VERSION ""

NS_ :

BS_:

BU_: HVESP01 HVESS

BO_ 2499743845 HVESP01_DiagnosticA_1: 8 HVESP01
 SG_ HVESP01_vBrickOverSev_1 : 2|2@1+ (1,0) [0|3] ""  HVESP01
 SG_ HVESP01_vBrickOverMod_1 : 0|2@1+ (1,0) [0|3] ""  HVESP01
 SG_ HVESP01_vBrickOverWar_1 : 14|2@1+ (1,0) [0|3] ""  HVESP01
 SG_ HVESP01_HVESP01Quiet_1 : 12|2@1+ (1,0) [0|3] ""  HVESP01
 SG_ HVESP01_vBrickUnderMod_1 : 10|2@1+ (1,0) [0|3] ""  HVESP01
 SG_ HVESP01_vBrickUnderWar_1 : 8|2@1+ (1,0) [0|3] ""  HVESP01
 SG_ HVESP01_TempModuleOverSev_1 : 22|2@1+ (1,0) [0|3] ""  HVESP01
 SG_ HVESP01_TempModuleOverMod_1 : 20|2@1+ (1,0) [0|3] ""  HVESP01
 SG_ HVESP01_TempModuleOverWar_1 : 18|2@1+ (1,0) [0|3] ""  HVESP01
 SG_ HVESP01_TempModuleUnderSev_1 : 16|2@1+ (1,0) [0|3] ""  HVESP01
 SG_ HVESP01_TempModuleUnderMod_1 : 30|2@1+ (1,0) [0|3] ""  HVESP01
 SG_ HVESP01_TempModuleUnderWar_1 : 28|2@1+ (1,0) [0|3] ""  HVESP01
 SG_ HVESP01_iOvercharge_1 : 26|2@1+ (1,0) [0|3] ""  HVESP01
 SG_ HVESP01_iOverdischarge_1 : 24|2@1+ (1,0) [0|3] ""  HVESP01
 SG_ HVESP01_iOverHardware_1 : 38|2@1+ (1,0) [0|3] ""  HVESP01
 SG_ HVESP01_PosContStuckOpen_1_1 : 36|2@1+ (1,0) [0|3] ""  HVESP01
 SG_ HVESP01_BATT_PosContWelded_1_1 : 34|2@1+ (1,0) [0|3] ""  HVESP01
 SG_ HVESP01_NegContStuckOpen_1_1 : 32|2@1+ (1,0) [0|3] ""  HVESP01
 SG_ HVESP01_NegContWelded_1_1 : 46|2@1+ (1,0) [0|3] ""  HVESP01
 SG_ HVESP01_PrechgTimeout_2_1 : 44|2@1+ (1,0) [0|3] ""  HVESP01
 SG_ HVESP01_PrechgContStuckOpen_2_1 : 42|2@1+ (1,0) [0|3] ""  HVESP01
 SG_ HVESP01_PrechgTimeout_1_1 : 40|2@1+ (1,0) [0|3] ""  HVESP01
 SG_ HVESP01_PrechgContStuckOpen_1_1 : 54|2@1+ (1,0) [0|3] ""  HVESP01
 SG_ HVESP01_ModuleImbalance_1 : 52|2@1+ (1,0) [0|3] ""  HVESP01
 SG_ HVESP01_ModuleMIA_1 : 50|2@1+ (1,0) [0|3] ""  HVESP01
 SG_ HVESP01_SensePackVoltError_1 : 48|2@1+ (1,0) [0|3] ""  HVESP01
 SG_ HVESP01_SenseLoadVoltError_1 : 62|2@1+ (1,0) [0|3] ""  HVESP01
 SG_ HVESP01_SenseShuntError_1 : 60|2@1+ (1,0) [0|3] ""  HVESP01
 SG_ HVESP01_SenseFcVoltErrorr_1 : 58|2@1+ (1,0) [0|3] ""  HVESP01
 SG_ HVESP01_Placeholder14_1 : 56|2@1+ (1,0) [0|3] ""  HVESP01

BO_ 2499743846 HVESP01_DiagnosticA_2: 8 HVESP01
 SG_ HVESP01_vBrickOverSev_2 : 2|2@1+ (1,0) [0|3] ""  HVESP01
 SG_ HVESP01_vBrickOverMod_2 : 0|2@1+ (1,0) [0|3] ""  HVESP01
 SG_ HVESP01_vBrickOverWar_2 : 14|2@1+ (1,0) [0|3] ""  HVESP01
 SG_ HVESP01_HVESP01Quiet_2 : 12|2@1+ (1,0) [0|3] ""  HVESP01
 SG_ HVESP01_vBrickUnderMod_2 : 10|2@1+ (1,0) [0|3] ""  HVESP01
 SG_ HVESP01_vBrickUnderWar_2 : 8|2@1+ (1,0) [0|3] ""  HVESP01
 SG_ HVESP01_TempModuleOverSev_2 : 22|2@1+ (1,0) [0|3] ""  HVESP01
 SG_ HVESP01_TempModuleOverMod_2 : 20|2@1+ (1,0) [0|3] ""  HVESP01
 SG_ HVESP01_TempModuleOverWar_2 : 18|2@1+ (1,0) [0|3] ""  HVESP01
 SG_ HVESP01_TempModuleUnderSev_2 : 16|2@1+ (1,0) [0|3] ""  HVESP01
 SG_ HVESP01_TempModuleUnderMod_2 : 30|2@1+ (1,0) [0|3] ""  HVESP01
 SG_ HVESP01_TempModuleUnderWar_2 : 28|2@1+ (1,0) [0|3] ""  HVESP01
 SG_ HVESP01_iOvercharge_2 : 26|2@1+ (1,0) [0|3] ""  HVESP01
 SG_ HVESP01_iOverdischarge_2 : 24|2@1+ (1,0) [0|3] ""  HVESP01
 SG_ HVESP01_iOverHardware_2 : 38|2@1+ (1,0) [0|3] ""  HVESP01
 SG_ HVESP01_PosContStuckOpen_1_2 : 36|2@1+ (1,0) [0|3] ""  HVESP01
 SG_ HVESP01_BATT_PosContWelded_1_2 : 34|2@1+ (1,0) [0|3] ""  HVESP01
 SG_ HVESP01_NegContStuckOpen_1_2 : 32|2@1+ (1,0) [0|3] ""  HVESP01
 SG_ HVESP01_NegContWelded_1_2 : 46|2@1+ (1,0) [0|3] ""  HVESP01
 SG_ HVESP01_PrechgTimeout_2_2 : 44|2@1+ (1,0) [0|3] ""  HVESP01
 SG_ HVESP01_PrechgContStuckOpen_2_2 : 42|2@1+ (1,0) [0|3] ""  HVESP01
 SG_ HVESP01_PrechgTimeout_1_2 : 40|2@1+ (1,0) [0|3] ""  HVESP01
 SG_ HVESP01_PrechgContStuckOpen_1_2 : 54|2@1+ (1,0) [0|3] ""  HVESP01
 SG_ HVESP01_ModuleImbalance_2 : 52|2@1+ (1,0) [0|3] ""  HVESP01
 SG_ HVESP01_ModuleMIA_2 : 50|2@1+ (1,0) [0|3] ""  HVESP01
 SG_ HVESP01_SensePackVoltError_2 : 48|2@1+ (1,0) [0|3] ""  HVESP01
 SG_ HVESP01_SenseLoadVoltError_2 : 62|2@1+ (1,0) [0|3] ""  HVESP01
 SG_ HVESP01_SenseShuntError_2 : 60|2@1+ (1,0) [0|3] ""  HVESP01
 SG_ HVESP01_SenseFcVoltErrorr_2 : 58|2@1+ (1,0) [0|3] ""  HVESP01
 SG_ HVESP01_Placeholder14_2 : 56|2@1+ (1,0) [0|3] ""  HVESP01

BO_ 2499743847 HVESP01_DiagnosticA_3: 8 HVESP01
 SG_ HVESP01_vBrickOverSev_3 : 2|2@1+ (1,0) [0|3] ""  HVESP01
 SG_ HVESP01_vBrickOverMod_3 : 0|2@1+ (1,0) [0|3] ""  HVESP01
 SG_ HVESP01_vBrickOverWar_3 : 14|2@1+ (1,0) [0|3] ""  HVESP01
 SG_ HVESP01_HVESP01Quiet_3 : 12|2@1+ (1,0) [0|3] ""  HVESP01
 SG_ HVESP01_vBrickUnderMod_3 : 10|2@1+ (1,0) [0|3] ""  HVESP01
 SG_ HVESP01_vBrickUnderWar_3 : 8|2@1+ (1,0) [0|3] ""  HVESP01
 SG_ HVESP01_TempModuleOverSev_3 : 22|2@1+ (1,0) [0|3] ""  HVESP01
 SG_ HVESP01_TempModuleOverMod_3 : 20|2@1+ (1,0) [0|3] ""  HVESP01
 SG_ HVESP01_TempModuleOverWar_3 : 18|2@1+ (1,0) [0|3] ""  HVESP01
 SG_ HVESP01_TempModuleUnderSev_3 : 16|2@1+ (1,0) [0|3] ""  HVESP01
 SG_ HVESP01_TempModuleUnderMod_3 : 30|2@1+ (1,0) [0|3] ""  HVESP01
 SG_ HVESP01_TempModuleUnderWar_3 : 28|2@1+ (1,0) [0|3] ""  HVESP01
 SG_ HVESP01_iOvercharge_3 : 26|2@1+ (1,0) [0|3] ""  HVESP01
 SG_ HVESP01_iOverdischarge_3 : 24|2@1+ (1,0) [0|3] ""  HVESP01
 SG_ HVESP01_iOverHardware_3 : 38|2@1+ (1,0) [0|3] ""  HVESP01
 SG_ HVESP01_PosContStuckOpen_1_3 : 36|2@1+ (1,0) [0|3] ""  HVESP01
 SG_ HVESP01_BATT_PosContWelded_1_3 : 34|2@1+ (1,0) [0|3] ""  HVESP01
 SG_ HVESP01_NegContStuckOpen_1_3 : 32|2@1+ (1,0) [0|3] ""  HVESP01
 SG_ HVESP01_NegContWelded_1_3 : 46|2@1+ (1,0) [0|3] ""  HVESP01
 SG_ HVESP01_PrechgTimeout_2_3 : 44|2@1+ (1,0) [0|3] ""  HVESP01
 SG_ HVESP01_PrechgContStuckOpen_2_3 : 42|2@1+ (1,0) [0|3] ""  HVESP01
 SG_ HVESP01_PrechgTimeout_1_3 : 40|2@1+ (1,0) [0|3] ""  HVESP01
 SG_ HVESP01_PrechgContStuckOpen_1_3 : 54|2@1+ (1,0) [0|3] ""  HVESP01
 SG_ HVESP01_ModuleImbalance_3 : 52|2@1+ (1,0) [0|3] ""  HVESP01
 SG_ HVESP01_ModuleMIA_3 : 50|2@1+ (1,0) [0|3] ""  HVESP01
 SG_ HVESP01_SensePackVoltError_3 : 48|2@1+ (1,0) [0|3] ""  HVESP01
 SG_ HVESP01_SenseLoadVoltError_3 : 62|2@1+ (1,0) [0|3] ""  HVESP01
 SG_ HVESP01_SenseShuntError_3 : 60|2@1+ (1,0) [0|3] ""  HVESP01
 SG_ HVESP01_SenseFcVoltErrorr_3 : 58|2@1+ (1,0) [0|3] ""  HVESP01
 SG_ HVESP01_Placeholder14_3 : 56|2@1+ (1,0) [0|3] ""  HVESP01

BO_ 2499743848 HVESP01_DiagnosticA_4: 8 HVESP01
 SG_ HVESP01_vBrickOverSev_4 : 2|2@1+ (1,0) [0|3] ""  HVESP01
 SG_ HVESP01_vBrickOverMod_4 : 0|2@1+ (1,0) [0|3] ""  HVESP01
 SG_ HVESP01_vBrickOverWar_4 : 14|2@1+ (1,0) [0|3] ""  HVESP01
 SG_ HVESP01_HVESP01Quiet_4 : 12|2@1+ (1,0) [0|3] ""  HVESP01
 SG_ HVESP01_vBrickUnderMod_4 : 10|2@1+ (1,0) [0|3] ""  HVESP01
 SG_ HVESP01_vBrickUnderWar_4 : 8|2@1+ (1,0) [0|3] ""  HVESP01
 SG_ HVESP01_TempModuleOverSev_4 : 22|2@1+ (1,0) [0|3] ""  HVESP01
 SG_ HVESP01_TempModuleOverMod_4 : 20|2@1+ (1,0) [0|3] ""  HVESP01
 SG_ HVESP01_TempModuleOverWar_4 : 18|2@1+ (1,0) [0|3] ""  HVESP01
 SG_ HVESP01_TempModuleUnderSev_4 : 16|2@1+ (1,0) [0|3] ""  HVESP01
 SG_ HVESP01_TempModuleUnderMod_4 : 30|2@1+ (1,0) [0|3] ""  HVESP01
 SG_ HVESP01_TempModuleUnderWar_4 : 28|2@1+ (1,0) [0|3] ""  HVESP01
 SG_ HVESP01_iOvercharge_4 : 26|2@1+ (1,0) [0|3] ""  HVESP01
 SG_ HVESP01_iOverdischarge_4 : 24|2@1+ (1,0) [0|3] ""  HVESP01
 SG_ HVESP01_iOverHardware_4 : 38|2@1+ (1,0) [0|3] ""  HVESP01
 SG_ HVESP01_PosContStuckOpen_1_4 : 36|2@1+ (1,0) [0|3] ""  HVESP01
 SG_ HVESP01_BATT_PosContWelded_1_4 : 34|2@1+ (1,0) [0|3] ""  HVESP01
 SG_ HVESP01_NegContStuckOpen_1_4 : 32|2@1+ (1,0) [0|3] ""  HVESP01
 SG_ HVESP01_NegContWelded_1_4 : 46|2@1+ (1,0) [0|3] ""  HVESP01
 SG_ HVESP01_PrechgTimeout_2_4 : 44|2@1+ (1,0) [0|3] ""  HVESP01
 SG_ HVESP01_PrechgContStuckOpen_2_4 : 42|2@1+ (1,0) [0|3] ""  HVESP01
 SG_ HVESP01_PrechgTimeout_1_4 : 40|2@1+ (1,0) [0|3] ""  HVESP01
 SG_ HVESP01_PrechgContStuckOpen_1_4 : 54|2@1+ (1,0) [0|3] ""  HVESP01
 SG_ HVESP01_ModuleImbalance_4 : 52|2@1+ (1,0) [0|3] ""  HVESP01
 SG_ HVESP01_ModuleMIA_4 : 50|2@1+ (1,0) [0|3] ""  HVESP01
 SG_ HVESP01_SensePackVoltError_4 : 48|2@1+ (1,0) [0|3] ""  HVESP01
 SG_ HVESP01_SenseLoadVoltError_4 : 62|2@1+ (1,0) [0|3] ""  HVESP01
 SG_ HVESP01_SenseShuntError_4 : 60|2@1+ (1,0) [0|3] ""  HVESP01
 SG_ HVESP01_SenseFcVoltErrorr_4 : 58|2@1+ (1,0) [0|3] ""  HVESP01
 SG_ HVESP01_Placeholder14_4 : 56|2@1+ (1,0) [0|3] ""  HVESP01

BO_ 2499743849 HVESP01_DiagnosticA_5: 8 HVESP01
 SG_ HVESP01_vBrickOverSev_5 : 2|2@1+ (1,0) [0|3] ""  HVESP01
 SG_ HVESP01_vBrickOverMod_5 : 0|2@1+ (1,0) [0|3] ""  HVESP01
 SG_ HVESP01_vBrickOverWar_5 : 14|2@1+ (1,0) [0|3] ""  HVESP01
 SG_ HVESP01_HVESP01Quiet_5 : 12|2@1+ (1,0) [0|3] ""  HVESP01
 SG_ HVESP01_vBrickUnderMod_5 : 10|2@1+ (1,0) [0|3] ""  HVESP01
 SG_ HVESP01_vBrickUnderWar_5 : 8|2@1+ (1,0) [0|3] ""  HVESP01
 SG_ HVESP01_TempModuleOverSev_5 : 22|2@1+ (1,0) [0|3] ""  HVESP01
 SG_ HVESP01_TempModuleOverMod_5 : 20|2@1+ (1,0) [0|3] ""  HVESP01
 SG_ HVESP01_TempModuleOverWar_5 : 18|2@1+ (1,0) [0|3] ""  HVESP01
 SG_ HVESP01_TempModuleUnderSev_5 : 16|2@1+ (1,0) [0|3] ""  HVESP01
 SG_ HVESP01_TempModuleUnderMod_5 : 30|2@1+ (1,0) [0|3] ""  HVESP01
 SG_ HVESP01_TempModuleUnderWar_5 : 28|2@1+ (1,0) [0|3] ""  HVESP01
 SG_ HVESP01_iOvercharge_5 : 26|2@1+ (1,0) [0|3] ""  HVESP01
 SG_ HVESP01_iOverdischarge_5 : 24|2@1+ (1,0) [0|3] ""  HVESP01
 SG_ HVESP01_iOverHardware_5 : 38|2@1+ (1,0) [0|3] ""  HVESP01
 SG_ HVESP01_PosContStuckOpen_1_5 : 36|2@1+ (1,0) [0|3] ""  HVESP01
 SG_ HVESP01_BATT_PosContWelded_1_5 : 34|2@1+ (1,0) [0|3] ""  HVESP01
 SG_ HVESP01_NegContStuckOpen_1_5 : 32|2@1+ (1,0) [0|3] ""  HVESP01
 SG_ HVESP01_NegContWelded_1_5 : 46|2@1+ (1,0) [0|3] ""  HVESP01
 SG_ HVESP01_PrechgTimeout_2_5 : 44|2@1+ (1,0) [0|3] ""  HVESP01
 SG_ HVESP01_PrechgContStuckOpen_2_5 : 42|2@1+ (1,0) [0|3] ""  HVESP01
 SG_ HVESP01_PrechgTimeout_1_5 : 40|2@1+ (1,0) [0|3] ""  HVESP01
 SG_ HVESP01_PrechgContStuckOpen_1_5 : 54|2@1+ (1,0) [0|3] ""  HVESP01
 SG_ HVESP01_ModuleImbalance_5 : 52|2@1+ (1,0) [0|3] ""  HVESP01
 SG_ HVESP01_ModuleMIA_5 : 50|2@1+ (1,0) [0|3] ""  HVESP01
 SG_ HVESP01_SensePackVoltError_5 : 48|2@1+ (1,0) [0|3] ""  HVESP01
 SG_ HVESP01_SenseLoadVoltError_5 : 62|2@1+ (1,0) [0|3] ""  HVESP01
 SG_ HVESP01_SenseShuntError_5 : 60|2@1+ (1,0) [0|3] ""  HVESP01
 SG_ HVESP01_SenseFcVoltErrorr_5 : 58|2@1+ (1,0) [0|3] ""  HVESP01
 SG_ HVESP01_Placeholder14_5 : 56|2@1+ (1,0) [0|3] ""  HVESP01

BO_ 2499743850 HVESP01_DiagnosticA_6: 8 HVESP01
 SG_ HVESP01_vBrickOverSev_6 : 2|2@1+ (1,0) [0|3] ""  HVESP01
 SG_ HVESP01_vBrickOverMod_6 : 0|2@1+ (1,0) [0|3] ""  HVESP01
 SG_ HVESP01_vBrickOverWar_6 : 14|2@1+ (1,0) [0|3] ""  HVESP01
 SG_ HVESP01_HVESP01Quiet_6 : 12|2@1+ (1,0) [0|3] ""  HVESP01
 SG_ HVESP01_vBrickUnderMod_6 : 10|2@1+ (1,0) [0|3] ""  HVESP01
 SG_ HVESP01_vBrickUnderWar_6 : 8|2@1+ (1,0) [0|3] ""  HVESP01
 SG_ HVESP01_TempModuleOverSev_6 : 22|2@1+ (1,0) [0|3] ""  HVESP01
 SG_ HVESP01_TempModuleOverMod_6 : 20|2@1+ (1,0) [0|3] ""  HVESP01
 SG_ HVESP01_TempModuleOverWar_6 : 18|2@1+ (1,0) [0|3] ""  HVESP01
 SG_ HVESP01_TempModuleUnderSev_6 : 16|2@1+ (1,0) [0|3] ""  HVESP01
 SG_ HVESP01_TempModuleUnderMod_6 : 30|2@1+ (1,0) [0|3] ""  HVESP01
 SG_ HVESP01_TempModuleUnderWar_6 : 28|2@1+ (1,0) [0|3] ""  HVESP01
 SG_ HVESP01_iOvercharge_6 : 26|2@1+ (1,0) [0|3] ""  HVESP01
 SG_ HVESP01_iOverdischarge_6 : 24|2@1+ (1,0) [0|3] ""  HVESP01
 SG_ HVESP01_iOverHardware_6 : 38|2@1+ (1,0) [0|3] ""  HVESP01
 SG_ HVESP01_PosContStuckOpen_1_6 : 36|2@1+ (1,0) [0|3] ""  HVESP01
 SG_ HVESP01_BATT_PosContWelded_1_6 : 34|2@1+ (1,0) [0|3] ""  HVESP01
 SG_ HVESP01_NegContStuckOpen_1_6 : 32|2@1+ (1,0) [0|3] ""  HVESP01
 SG_ HVESP01_NegContWelded_1_6 : 46|2@1+ (1,0) [0|3] ""  HVESP01
 SG_ HVESP01_PrechgTimeout_2_6 : 44|2@1+ (1,0) [0|3] ""  HVESP01
 SG_ HVESP01_PrechgContStuckOpen_2_6 : 42|2@1+ (1,0) [0|3] ""  HVESP01
 SG_ HVESP01_PrechgTimeout_1_6 : 40|2@1+ (1,0) [0|3] ""  HVESP01
 SG_ HVESP01_PrechgContStuckOpen_1_6 : 54|2@1+ (1,0) [0|3] ""  HVESP01
 SG_ HVESP01_ModuleImbalance_6 : 52|2@1+ (1,0) [0|3] ""  HVESP01
 SG_ HVESP01_ModuleMIA_6 : 50|2@1+ (1,0) [0|3] ""  HVESP01
 SG_ HVESP01_SensePackVoltError_6 : 48|2@1+ (1,0) [0|3] ""  HVESP01
 SG_ HVESP01_SenseLoadVoltError_6 : 62|2@1+ (1,0) [0|3] ""  HVESP01
 SG_ HVESP01_SenseShuntError_6 : 60|2@1+ (1,0) [0|3] ""  HVESP01
 SG_ HVESP01_SenseFcVoltErrorr_6 : 58|2@1+ (1,0) [0|3] ""  HVESP01
 SG_ HVESP01_Placeholder14_6 : 56|2@1+ (1,0) [0|3] ""  HVESP01

BO_ 2499743851 HVESP01_DiagnosticA_7: 8 HVESP01
 SG_ HVESP01_vBrickOverSev_7 : 2|2@1+ (1,0) [0|3] ""  HVESP01
 SG_ HVESP01_vBrickOverMod_7 : 0|2@1+ (1,0) [0|3] ""  HVESP01
 SG_ HVESP01_vBrickOverWar_7 : 14|2@1+ (1,0) [0|3] ""  HVESP01
 SG_ HVESP01_HVESP01Quiet_7 : 12|2@1+ (1,0) [0|3] ""  HVESP01
 SG_ HVESP01_vBrickUnderMod_7 : 10|2@1+ (1,0) [0|3] ""  HVESP01
 SG_ HVESP01_vBrickUnderWar_7 : 8|2@1+ (1,0) [0|3] ""  HVESP01
 SG_ HVESP01_TempModuleOverSev_7 : 22|2@1+ (1,0) [0|3] ""  HVESP01
 SG_ HVESP01_TempModuleOverMod_7 : 20|2@1+ (1,0) [0|3] ""  HVESP01
 SG_ HVESP01_TempModuleOverWar_7 : 18|2@1+ (1,0) [0|3] ""  HVESP01
 SG_ HVESP01_TempModuleUnderSev_7 : 16|2@1+ (1,0) [0|3] ""  HVESP01
 SG_ HVESP01_TempModuleUnderMod_7 : 30|2@1+ (1,0) [0|3] ""  HVESP01
 SG_ HVESP01_TempModuleUnderWar_7 : 28|2@1+ (1,0) [0|3] ""  HVESP01
 SG_ HVESP01_iOvercharge_7 : 26|2@1+ (1,0) [0|3] ""  HVESP01
 SG_ HVESP01_iOverdischarge_7 : 24|2@1+ (1,0) [0|3] ""  HVESP01
 SG_ HVESP01_iOverHardware_7 : 38|2@1+ (1,0) [0|3] ""  HVESP01
 SG_ HVESP01_PosContStuckOpen_1_7 : 36|2@1+ (1,0) [0|3] ""  HVESP01
 SG_ HVESP01_BATT_PosContWelded_1_7 : 34|2@1+ (1,0) [0|3] ""  HVESP01
 SG_ HVESP01_NegContStuckOpen_1_7 : 32|2@1+ (1,0) [0|3] ""  HVESP01
 SG_ HVESP01_NegContWelded_1_7 : 46|2@1+ (1,0) [0|3] ""  HVESP01
 SG_ HVESP01_PrechgTimeout_2_7 : 44|2@1+ (1,0) [0|3] ""  HVESP01
 SG_ HVESP01_PrechgContStuckOpen_2_7 : 42|2@1+ (1,0) [0|3] ""  HVESP01
 SG_ HVESP01_PrechgTimeout_1_7 : 40|2@1+ (1,0) [0|3] ""  HVESP01
 SG_ HVESP01_PrechgContStuckOpen_1_7 : 54|2@1+ (1,0) [0|3] ""  HVESP01
 SG_ HVESP01_ModuleImbalance_7 : 52|2@1+ (1,0) [0|3] ""  HVESP01
 SG_ HVESP01_ModuleMIA_7 : 50|2@1+ (1,0) [0|3] ""  HVESP01
 SG_ HVESP01_SensePackVoltError_7 : 48|2@1+ (1,0) [0|3] ""  HVESP01
 SG_ HVESP01_SenseLoadVoltError_7 : 62|2@1+ (1,0) [0|3] ""  HVESP01
 SG_ HVESP01_SenseShuntError_7 : 60|2@1+ (1,0) [0|3] ""  HVESP01
 SG_ HVESP01_SenseFcVoltErrorr_7 : 58|2@1+ (1,0) [0|3] ""  HVESP01
 SG_ HVESP01_Placeholder14_7 : 56|2@1+ (1,0) [0|3] ""  HVESP01

BO_ 2499743852 HVESP01_DiagnosticA_8: 8 HVESP01
 SG_ HVESP01_vBrickOverSev_8 : 2|2@1+ (1,0) [0|3] ""  HVESP01
 SG_ HVESP01_vBrickOverMod_8 : 0|2@1+ (1,0) [0|3] ""  HVESP01
 SG_ HVESP01_vBrickOverWar_8 : 14|2@1+ (1,0) [0|3] ""  HVESP01
 SG_ HVESP01_HVESP01Quiet_8 : 12|2@1+ (1,0) [0|3] ""  HVESP01
 SG_ HVESP01_vBrickUnderMod_8 : 10|2@1+ (1,0) [0|3] ""  HVESP01
 SG_ HVESP01_vBrickUnderWar_8 : 8|2@1+ (1,0) [0|3] ""  HVESP01
 SG_ HVESP01_TempModuleOverSev_8 : 22|2@1+ (1,0) [0|3] ""  HVESP01
 SG_ HVESP01_TempModuleOverMod_8 : 20|2@1+ (1,0) [0|3] ""  HVESP01
 SG_ HVESP01_TempModuleOverWar_8 : 18|2@1+ (1,0) [0|3] ""  HVESP01
 SG_ HVESP01_TempModuleUnderSev_8 : 16|2@1+ (1,0) [0|3] ""  HVESP01
 SG_ HVESP01_TempModuleUnderMod_8 : 30|2@1+ (1,0) [0|3] ""  HVESP01
 SG_ HVESP01_TempModuleUnderWar_8 : 28|2@1+ (1,0) [0|3] ""  HVESP01
 SG_ HVESP01_iOvercharge_8 : 26|2@1+ (1,0) [0|3] ""  HVESP01
 SG_ HVESP01_iOverdischarge_8 : 24|2@1+ (1,0) [0|3] ""  HVESP01
 SG_ HVESP01_iOverHardware_8 : 38|2@1+ (1,0) [0|3] ""  HVESP01
 SG_ HVESP01_PosContStuckOpen_1_8 : 36|2@1+ (1,0) [0|3] ""  HVESP01
 SG_ HVESP01_BATT_PosContWelded_1_8 : 34|2@1+ (1,0) [0|3] ""  HVESP01
 SG_ HVESP01_NegContStuckOpen_1_8 : 32|2@1+ (1,0) [0|3] ""  HVESP01
 SG_ HVESP01_NegContWelded_1_8 : 46|2@1+ (1,0) [0|3] ""  HVESP01
 SG_ HVESP01_PrechgTimeout_2_8 : 44|2@1+ (1,0) [0|3] ""  HVESP01
 SG_ HVESP01_PrechgContStuckOpen_2_8 : 42|2@1+ (1,0) [0|3] ""  HVESP01
 SG_ HVESP01_PrechgTimeout_1_8 : 40|2@1+ (1,0) [0|3] ""  HVESP01
 SG_ HVESP01_PrechgContStuckOpen_1_8 : 54|2@1+ (1,0) [0|3] ""  HVESP01
 SG_ HVESP01_ModuleImbalance_8 : 52|2@1+ (1,0) [0|3] ""  HVESP01
 SG_ HVESP01_ModuleMIA_8 : 50|2@1+ (1,0) [0|3] ""  HVESP01
 SG_ HVESP01_SensePackVoltError_8 : 48|2@1+ (1,0) [0|3] ""  HVESP01
 SG_ HVESP01_SenseLoadVoltError_8 : 62|2@1+ (1,0) [0|3] ""  HVESP01
 SG_ HVESP01_SenseShuntError_8 : 60|2@1+ (1,0) [0|3] ""  HVESP01
 SG_ HVESP01_SenseFcVoltErrorr_8 : 58|2@1+ (1,0) [0|3] ""  HVESP01
 SG_ HVESP01_Placeholder14_8 : 56|2@1+ (1,0) [0|3] ""  HVESP01

BO_ 2499744101 HVESP01_DiagnosticB_1: 8 HVESP01
 SG_ HVESP01_SenseBrickImpHigh_1 : 2|2@1+ (1,0) [0|3] ""  HVESP01
 SG_ HVESP01_AFEfault_1 : 0|2@1+ (1,0) [0|3] ""  HVESP01
 SG_ HVESP01_AFEerror_1 : 14|2@1+ (1,0) [0|3] ""  HVESP01
 SG_ HVESP01_HVESP01MIA_1 : 12|2@1+ (1,0) [0|3] ""  HVESP01
 SG_ HVESP01_TempAmbientOverSev_1 : 10|2@1+ (1,0) [0|3] ""  HVESP01
 SG_ HVESP01_TempAmbientOverMod_1 : 8|2@1+ (1,0) [0|3] ""  HVESP01
 SG_ HVESP01_TempAmbientOverWar_1 : 22|2@1+ (1,0) [0|3] ""  HVESP01
 SG_ HVESP01_AbnormReset_1 : 20|2@1+ (1,0) [0|3] ""  HVESP01
 SG_ HVESP01_SenseAuxVoltError_1 : 18|2@1+ (1,0) [0|3] ""  HVESP01
 SG_ HVESP01_CalibrationInvalid_1 : 16|2@1+ (1,0) [0|3] ""  HVESP01
 SG_ HVESP01_TaskLockup_1 : 30|2@1+ (1,0) [0|3] ""  HVESP01
 SG_ HVESP01_RAMover_1 : 28|2@1+ (1,0) [0|3] ""  HVESP01
 SG_ HVESP01_BrickOverdischarge_1 : 26|2@1+ (1,0) [0|3] ""  HVESP01
 SG_ HVESP01_BrickOvercharge_1 : 24|2@1+ (1,0) [0|3] ""  HVESP01
 SG_ HVESP01_vBrickImbalancePer_1 : 38|2@1+ (1,0) [0|3] ""  HVESP01
 SG_ HVESP01_TempBrickImbalance_1 : 36|2@1+ (1,0) [0|3] ""  HVESP01
 SG_ HVESP01_CapPackLow_1 : 34|2@1+ (1,0) [0|3] ""  HVESP01
 SG_ HVESP01_rBrickHigh_1 : 32|2@1+ (1,0) [0|3] ""  HVESP01
 SG_ HVESP01_PowerpackInsuffErr_1 : 46|2@1+ (1,0) [0|3] ""  HVESP01
 SG_ HVESP01_BrickSoftShort_1 : 44|2@1+ (1,0) [0|3] ""  HVESP01
 SG_ HVESP01_chargeUndercurrent_1 : 42|2@1+ (1,0) [0|3] ""  HVESP01
 SG_ HVESP01_HVILcurrentSourceError_1 : 40|2@1+ (1,0) [0|3] ""  HVESP01
 SG_ HVESP01_SRS_1 : 54|2@1+ (1,0) [0|3] ""  HVESP01
 SG_ HVESP01_IsolationExtWar_1 : 52|2@1+ (1,0) [0|3] ""  HVESP01
 SG_ HVESP01_IsolationIntWar_1 : 50|2@1+ (1,0) [0|3] ""  HVESP01
 SG_ HVESP01_PyroFuseBlown_1 : 48|2@1+ (1,0) [0|3] ""  HVESP01
 SG_ HVESP01_vBrickUnderSev_1 : 62|2@1+ (1,0) [0|3] ""  HVESP01
 SG_ HVESP01_chargePrechargeTimeout_1 : 60|2@1+ (1,0) [0|3] ""  HVESP01
 SG_ HVESP01_ModuleThermFaultModerate_1 : 58|2@1+ (1,0) [0|3] ""  HVESP01
 SG_ HVESP01_ModuleThermFaultWarning_1 : 56|2@1+ (1,0) [0|3] ""  HVESP01

BO_ 2499744102 HVESP01_DiagnosticB_2: 8 HVESP01
 SG_ HVESP01_SenseBrickImpHigh_2 : 2|2@1+ (1,0) [0|3] ""  HVESP01
 SG_ HVESP01_AFEfault_2 : 0|2@1+ (1,0) [0|3] ""  HVESP01
 SG_ HVESP01_AFEerror_2 : 14|2@1+ (1,0) [0|3] ""  HVESP01
 SG_ HVESP01_HVESP01MIA_2 : 12|2@1+ (1,0) [0|3] ""  HVESP01
 SG_ HVESP01_TempAmbientOverSev_2 : 10|2@1+ (1,0) [0|3] ""  HVESP01
 SG_ HVESP01_TempAmbientOverMod_2 : 8|2@1+ (1,0) [0|3] ""  HVESP01
 SG_ HVESP01_TempAmbientOverWar_2 : 22|2@1+ (1,0) [0|3] ""  HVESP01
 SG_ HVESP01_AbnormReset_2 : 20|2@1+ (1,0) [0|3] ""  HVESP01
 SG_ HVESP01_SenseAuxVoltError_2 : 18|2@1+ (1,0) [0|3] ""  HVESP01
 SG_ HVESP01_CalibrationInvalid_2 : 16|2@1+ (1,0) [0|3] ""  HVESP01
 SG_ HVESP01_TaskLockup_2 : 30|2@1+ (1,0) [0|3] ""  HVESP01
 SG_ HVESP01_RAMover_2 : 28|2@1+ (1,0) [0|3] ""  HVESP01
 SG_ HVESP01_BrickOverdischarge_2 : 26|2@1+ (1,0) [0|3] ""  HVESP01
 SG_ HVESP01_BrickOvercharge_2 : 24|2@1+ (1,0) [0|3] ""  HVESP01
 SG_ HVESP01_vBrickImbalancePer_2 : 38|2@1+ (1,0) [0|3] ""  HVESP01
 SG_ HVESP01_TempBrickImbalance_2 : 36|2@1+ (1,0) [0|3] ""  HVESP01
 SG_ HVESP01_CapPackLow_2 : 34|2@1+ (1,0) [0|3] ""  HVESP01
 SG_ HVESP01_rBrickHigh_2 : 32|2@1+ (1,0) [0|3] ""  HVESP01
 SG_ HVESP01_PowerpackInsuffErr_2 : 46|2@1+ (1,0) [0|3] ""  HVESP01
 SG_ HVESP01_BrickSoftShort_2 : 44|2@1+ (1,0) [0|3] ""  HVESP01
 SG_ HVESP01_chargeUndercurrent_2 : 42|2@1+ (1,0) [0|3] ""  HVESP01
 SG_ HVESP01_HVILcurrentSourceError_2 : 40|2@1+ (1,0) [0|3] ""  HVESP01
 SG_ HVESP01_SRS_2 : 54|2@1+ (1,0) [0|3] ""  HVESP01
 SG_ HVESP01_IsolationExtWar_2 : 52|2@1+ (1,0) [0|3] ""  HVESP01
 SG_ HVESP01_IsolationIntWar_2 : 50|2@1+ (1,0) [0|3] ""  HVESP01
 SG_ HVESP01_PyroFuseBlown_2 : 48|2@1+ (1,0) [0|3] ""  HVESP01
 SG_ HVESP01_vBrickUnderSev_2 : 62|2@1+ (1,0) [0|3] ""  HVESP01
 SG_ HVESP01_chargePrechargeTimeout_2 : 60|2@1+ (1,0) [0|3] ""  HVESP01
 SG_ HVESP01_ModuleThermFaultModerate_2 : 58|2@1+ (1,0) [0|3] ""  HVESP01
 SG_ HVESP01_ModuleThermFaultWarning_2 : 56|2@1+ (1,0) [0|3] ""  HVESP01

BO_ 2499744103 HVESP01_DiagnosticB_3: 8 HVESP01
 SG_ HVESP01_SenseBrickImpHigh_3 : 2|2@1+ (1,0) [0|3] ""  HVESP01
 SG_ HVESP01_AFEfault_3 : 0|2@1+ (1,0) [0|3] ""  HVESP01
 SG_ HVESP01_AFEerror_3 : 14|2@1+ (1,0) [0|3] ""  HVESP01
 SG_ HVESP01_HVESP01MIA_3 : 12|2@1+ (1,0) [0|3] ""  HVESP01
 SG_ HVESP01_TempAmbientOverSev_3 : 10|2@1+ (1,0) [0|3] ""  HVESP01
 SG_ HVESP01_TempAmbientOverMod_3 : 8|2@1+ (1,0) [0|3] ""  HVESP01
 SG_ HVESP01_TempAmbientOverWar_3 : 22|2@1+ (1,0) [0|3] ""  HVESP01
 SG_ HVESP01_AbnormReset_3 : 20|2@1+ (1,0) [0|3] ""  HVESP01
 SG_ HVESP01_SenseAuxVoltError_3 : 18|2@1+ (1,0) [0|3] ""  HVESP01
 SG_ HVESP01_CalibrationInvalid_3 : 16|2@1+ (1,0) [0|3] ""  HVESP01
 SG_ HVESP01_TaskLockup_3 : 30|2@1+ (1,0) [0|3] ""  HVESP01
 SG_ HVESP01_RAMover_3 : 28|2@1+ (1,0) [0|3] ""  HVESP01
 SG_ HVESP01_BrickOverdischarge_3 : 26|2@1+ (1,0) [0|3] ""  HVESP01
 SG_ HVESP01_BrickOvercharge_3 : 24|2@1+ (1,0) [0|3] ""  HVESP01
 SG_ HVESP01_vBrickImbalancePer_3 : 38|2@1+ (1,0) [0|3] ""  HVESP01
 SG_ HVESP01_TempBrickImbalance_3 : 36|2@1+ (1,0) [0|3] ""  HVESP01
 SG_ HVESP01_CapPackLow_3 : 34|2@1+ (1,0) [0|3] ""  HVESP01
 SG_ HVESP01_rBrickHigh_3 : 32|2@1+ (1,0) [0|3] ""  HVESP01
 SG_ HVESP01_PowerpackInsuffErr_3 : 46|2@1+ (1,0) [0|3] ""  HVESP01
 SG_ HVESP01_BrickSoftShort_3 : 44|2@1+ (1,0) [0|3] ""  HVESP01
 SG_ HVESP01_chargeUndercurrent_3 : 42|2@1+ (1,0) [0|3] ""  HVESP01
 SG_ HVESP01_HVILcurrentSourceError_3 : 40|2@1+ (1,0) [0|3] ""  HVESP01
 SG_ HVESP01_SRS_3 : 54|2@1+ (1,0) [0|3] ""  HVESP01
 SG_ HVESP01_IsolationExtWar_3 : 52|2@1+ (1,0) [0|3] ""  HVESP01
 SG_ HVESP01_IsolationIntWar_3 : 50|2@1+ (1,0) [0|3] ""  HVESP01
 SG_ HVESP01_PyroFuseBlown_3 : 48|2@1+ (1,0) [0|3] ""  HVESP01
 SG_ HVESP01_vBrickUnderSev_3 : 62|2@1+ (1,0) [0|3] ""  HVESP01
 SG_ HVESP01_chargePrechargeTimeout_3 : 60|2@1+ (1,0) [0|3] ""  HVESP01
 SG_ HVESP01_ModuleThermFaultModerate_3 : 58|2@1+ (1,0) [0|3] ""  HVESP01
 SG_ HVESP01_ModuleThermFaultWarning_3 : 56|2@1+ (1,0) [0|3] ""  HVESP01

BO_ 2499744104 HVESP01_DiagnosticB_4: 8 HVESP01
 SG_ HVESP01_SenseBrickImpHigh_4 : 2|2@1+ (1,0) [0|3] ""  HVESP01
 SG_ HVESP01_AFEfault_4 : 0|2@1+ (1,0) [0|3] ""  HVESP01
 SG_ HVESP01_AFEerror_4 : 14|2@1+ (1,0) [0|3] ""  HVESP01
 SG_ HVESP01_HVESP01MIA_4 : 12|2@1+ (1,0) [0|3] ""  HVESP01
 SG_ HVESP01_TempAmbientOverSev_4 : 10|2@1+ (1,0) [0|3] ""  HVESP01
 SG_ HVESP01_TempAmbientOverMod_4 : 8|2@1+ (1,0) [0|3] ""  HVESP01
 SG_ HVESP01_TempAmbientOverWar_4 : 22|2@1+ (1,0) [0|3] ""  HVESP01
 SG_ HVESP01_AbnormReset_4 : 20|2@1+ (1,0) [0|3] ""  HVESP01
 SG_ HVESP01_SenseAuxVoltError_4 : 18|2@1+ (1,0) [0|3] ""  HVESP01
 SG_ HVESP01_CalibrationInvalid_4 : 16|2@1+ (1,0) [0|3] ""  HVESP01
 SG_ HVESP01_TaskLockup_4 : 30|2@1+ (1,0) [0|3] ""  HVESP01
 SG_ HVESP01_RAMover_4 : 28|2@1+ (1,0) [0|3] ""  HVESP01
 SG_ HVESP01_BrickOverdischarge_4 : 26|2@1+ (1,0) [0|3] ""  HVESP01
 SG_ HVESP01_BrickOvercharge_4 : 24|2@1+ (1,0) [0|3] ""  HVESP01
 SG_ HVESP01_vBrickImbalancePer_4 : 38|2@1+ (1,0) [0|3] ""  HVESP01
 SG_ HVESP01_TempBrickImbalance_4 : 36|2@1+ (1,0) [0|3] ""  HVESP01
 SG_ HVESP01_CapPackLow_4 : 34|2@1+ (1,0) [0|3] ""  HVESP01
 SG_ HVESP01_rBrickHigh_4 : 32|2@1+ (1,0) [0|3] ""  HVESP01
 SG_ HVESP01_PowerpackInsuffErr_4 : 46|2@1+ (1,0) [0|3] ""  HVESP01
 SG_ HVESP01_BrickSoftShort_4 : 44|2@1+ (1,0) [0|3] ""  HVESP01
 SG_ HVESP01_chargeUndercurrent_4 : 42|2@1+ (1,0) [0|3] ""  HVESP01
 SG_ HVESP01_HVILcurrentSourceError_4 : 40|2@1+ (1,0) [0|3] ""  HVESP01
 SG_ HVESP01_SRS_4 : 54|2@1+ (1,0) [0|3] ""  HVESP01
 SG_ HVESP01_IsolationExtWar_4 : 52|2@1+ (1,0) [0|3] ""  HVESP01
 SG_ HVESP01_IsolationIntWar_4 : 50|2@1+ (1,0) [0|3] ""  HVESP01
 SG_ HVESP01_PyroFuseBlown_4 : 48|2@1+ (1,0) [0|3] ""  HVESP01
 SG_ HVESP01_vBrickUnderSev_4 : 62|2@1+ (1,0) [0|3] ""  HVESP01
 SG_ HVESP01_chargePrechargeTimeout_4 : 60|2@1+ (1,0) [0|3] ""  HVESP01
 SG_ HVESP01_ModuleThermFaultModerate_4 : 58|2@1+ (1,0) [0|3] ""  HVESP01
 SG_ HVESP01_ModuleThermFaultWarning_4 : 56|2@1+ (1,0) [0|3] ""  HVESP01

BO_ 2499744105 HVESP01_DiagnosticB_5: 8 HVESP01
 SG_ HVESP01_SenseBrickImpHigh_5 : 2|2@1+ (1,0) [0|3] ""  HVESP01
 SG_ HVESP01_AFEfault_5 : 0|2@1+ (1,0) [0|3] ""  HVESP01
 SG_ HVESP01_AFEerror_5 : 14|2@1+ (1,0) [0|3] ""  HVESP01
 SG_ HVESP01_HVESP01MIA_5 : 12|2@1+ (1,0) [0|3] ""  HVESP01
 SG_ HVESP01_TempAmbientOverSev_5 : 10|2@1+ (1,0) [0|3] ""  HVESP01
 SG_ HVESP01_TempAmbientOverMod_5 : 8|2@1+ (1,0) [0|3] ""  HVESP01
 SG_ HVESP01_TempAmbientOverWar_5 : 22|2@1+ (1,0) [0|3] ""  HVESP01
 SG_ HVESP01_AbnormReset_5 : 20|2@1+ (1,0) [0|3] ""  HVESP01
 SG_ HVESP01_SenseAuxVoltError_5 : 18|2@1+ (1,0) [0|3] ""  HVESP01
 SG_ HVESP01_CalibrationInvalid_5 : 16|2@1+ (1,0) [0|3] ""  HVESP01
 SG_ HVESP01_TaskLockup_5 : 30|2@1+ (1,0) [0|3] ""  HVESP01
 SG_ HVESP01_RAMover_5 : 28|2@1+ (1,0) [0|3] ""  HVESP01
 SG_ HVESP01_BrickOverdischarge_5 : 26|2@1+ (1,0) [0|3] ""  HVESP01
 SG_ HVESP01_BrickOvercharge_5 : 24|2@1+ (1,0) [0|3] ""  HVESP01
 SG_ HVESP01_vBrickImbalancePer_5 : 38|2@1+ (1,0) [0|3] ""  HVESP01
 SG_ HVESP01_TempBrickImbalance_5 : 36|2@1+ (1,0) [0|3] ""  HVESP01
 SG_ HVESP01_CapPackLow_5 : 34|2@1+ (1,0) [0|3] ""  HVESP01
 SG_ HVESP01_rBrickHigh_5 : 32|2@1+ (1,0) [0|3] ""  HVESP01
 SG_ HVESP01_PowerpackInsuffErr_5 : 46|2@1+ (1,0) [0|3] ""  HVESP01
 SG_ HVESP01_BrickSoftShort_5 : 44|2@1+ (1,0) [0|3] ""  HVESP01
 SG_ HVESP01_chargeUndercurrent_5 : 42|2@1+ (1,0) [0|3] ""  HVESP01
 SG_ HVESP01_HVILcurrentSourceError_5 : 40|2@1+ (1,0) [0|3] ""  HVESP01
 SG_ HVESP01_SRS_5 : 54|2@1+ (1,0) [0|3] ""  HVESP01
 SG_ HVESP01_IsolationExtWar_5 : 52|2@1+ (1,0) [0|3] ""  HVESP01
 SG_ HVESP01_IsolationIntWar_5 : 50|2@1+ (1,0) [0|3] ""  HVESP01
 SG_ HVESP01_PyroFuseBlown_5 : 48|2@1+ (1,0) [0|3] ""  HVESP01
 SG_ HVESP01_vBrickUnderSev_5 : 62|2@1+ (1,0) [0|3] ""  HVESP01
 SG_ HVESP01_chargePrechargeTimeout_5 : 60|2@1+ (1,0) [0|3] ""  HVESP01
 SG_ HVESP01_ModuleThermFaultModerate_5 : 58|2@1+ (1,0) [0|3] ""  HVESP01
 SG_ HVESP01_ModuleThermFaultWarning_5 : 56|2@1+ (1,0) [0|3] ""  HVESP01

BO_ 2499744106 HVESP01_DiagnosticB_6: 8 HVESP01
 SG_ HVESP01_SenseBrickImpHigh_6 : 2|2@1+ (1,0) [0|3] ""  HVESP01
 SG_ HVESP01_AFEfault_6 : 0|2@1+ (1,0) [0|3] ""  HVESP01
 SG_ HVESP01_AFEerror_6 : 14|2@1+ (1,0) [0|3] ""  HVESP01
 SG_ HVESP01_HVESP01MIA_6 : 12|2@1+ (1,0) [0|3] ""  HVESP01
 SG_ HVESP01_TempAmbientOverSev_6 : 10|2@1+ (1,0) [0|3] ""  HVESP01
 SG_ HVESP01_TempAmbientOverMod_6 : 8|2@1+ (1,0) [0|3] ""  HVESP01
 SG_ HVESP01_TempAmbientOverWar_6 : 22|2@1+ (1,0) [0|3] ""  HVESP01
 SG_ HVESP01_AbnormReset_6 : 20|2@1+ (1,0) [0|3] ""  HVESP01
 SG_ HVESP01_SenseAuxVoltError_6 : 18|2@1+ (1,0) [0|3] ""  HVESP01
 SG_ HVESP01_CalibrationInvalid_6 : 16|2@1+ (1,0) [0|3] ""  HVESP01
 SG_ HVESP01_TaskLockup_6 : 30|2@1+ (1,0) [0|3] ""  HVESP01
 SG_ HVESP01_RAMover_6 : 28|2@1+ (1,0) [0|3] ""  HVESP01
 SG_ HVESP01_BrickOverdischarge_6 : 26|2@1+ (1,0) [0|3] ""  HVESP01
 SG_ HVESP01_BrickOvercharge_6 : 24|2@1+ (1,0) [0|3] ""  HVESP01
 SG_ HVESP01_vBrickImbalancePer_6 : 38|2@1+ (1,0) [0|3] ""  HVESP01
 SG_ HVESP01_TempBrickImbalance_6 : 36|2@1+ (1,0) [0|3] ""  HVESP01
 SG_ HVESP01_CapPackLow_6 : 34|2@1+ (1,0) [0|3] ""  HVESP01
 SG_ HVESP01_rBrickHigh_6 : 32|2@1+ (1,0) [0|3] ""  HVESP01
 SG_ HVESP01_PowerpackInsuffErr_6 : 46|2@1+ (1,0) [0|3] ""  HVESP01
 SG_ HVESP01_BrickSoftShort_6 : 44|2@1+ (1,0) [0|3] ""  HVESP01
 SG_ HVESP01_chargeUndercurrent_6 : 42|2@1+ (1,0) [0|3] ""  HVESP01
 SG_ HVESP01_HVILcurrentSourceError_6 : 40|2@1+ (1,0) [0|3] ""  HVESP01
 SG_ HVESP01_SRS_6 : 54|2@1+ (1,0) [0|3] ""  HVESP01
 SG_ HVESP01_IsolationExtWar_6 : 52|2@1+ (1,0) [0|3] ""  HVESP01
 SG_ HVESP01_IsolationIntWar_6 : 50|2@1+ (1,0) [0|3] ""  HVESP01
 SG_ HVESP01_PyroFuseBlown_6 : 48|2@1+ (1,0) [0|3] ""  HVESP01
 SG_ HVESP01_vBrickUnderSev_6 : 62|2@1+ (1,0) [0|3] ""  HVESP01
 SG_ HVESP01_chargePrechargeTimeout_6 : 60|2@1+ (1,0) [0|3] ""  HVESP01
 SG_ HVESP01_ModuleThermFaultModerate_6 : 58|2@1+ (1,0) [0|3] ""  HVESP01
 SG_ HVESP01_ModuleThermFaultWarning_6 : 56|2@1+ (1,0) [0|3] ""  HVESP01

BO_ 2499744107 HVESP01_DiagnosticB_7: 8 HVESP01
 SG_ HVESP01_SenseBrickImpHigh_7 : 2|2@1+ (1,0) [0|3] ""  HVESP01
 SG_ HVESP01_AFEfault_7 : 0|2@1+ (1,0) [0|3] ""  HVESP01
 SG_ HVESP01_AFEerror_7 : 14|2@1+ (1,0) [0|3] ""  HVESP01
 SG_ HVESP01_HVESP01MIA_7 : 12|2@1+ (1,0) [0|3] ""  HVESP01
 SG_ HVESP01_TempAmbientOverSev_7 : 10|2@1+ (1,0) [0|3] ""  HVESP01
 SG_ HVESP01_TempAmbientOverMod_7 : 8|2@1+ (1,0) [0|3] ""  HVESP01
 SG_ HVESP01_TempAmbientOverWar_7 : 22|2@1+ (1,0) [0|3] ""  HVESP01
 SG_ HVESP01_AbnormReset_7 : 20|2@1+ (1,0) [0|3] ""  HVESP01
 SG_ HVESP01_SenseAuxVoltError_7 : 18|2@1+ (1,0) [0|3] ""  HVESP01
 SG_ HVESP01_CalibrationInvalid_7 : 16|2@1+ (1,0) [0|3] ""  HVESP01
 SG_ HVESP01_TaskLockup_7 : 30|2@1+ (1,0) [0|3] ""  HVESP01
 SG_ HVESP01_RAMover_7 : 28|2@1+ (1,0) [0|3] ""  HVESP01
 SG_ HVESP01_BrickOverdischarge_7 : 26|2@1+ (1,0) [0|3] ""  HVESP01
 SG_ HVESP01_BrickOvercharge_7 : 24|2@1+ (1,0) [0|3] ""  HVESP01
 SG_ HVESP01_vBrickImbalancePer_7 : 38|2@1+ (1,0) [0|3] ""  HVESP01
 SG_ HVESP01_TempBrickImbalance_7 : 36|2@1+ (1,0) [0|3] ""  HVESP01
 SG_ HVESP01_CapPackLow_7 : 34|2@1+ (1,0) [0|3] ""  HVESP01
 SG_ HVESP01_rBrickHigh_7 : 32|2@1+ (1,0) [0|3] ""  HVESP01
 SG_ HVESP01_PowerpackInsuffErr_7 : 46|2@1+ (1,0) [0|3] ""  HVESP01
 SG_ HVESP01_BrickSoftShort_7 : 44|2@1+ (1,0) [0|3] ""  HVESP01
 SG_ HVESP01_chargeUndercurrent_7 : 42|2@1+ (1,0) [0|3] ""  HVESP01
 SG_ HVESP01_HVILcurrentSourceError_7 : 40|2@1+ (1,0) [0|3] ""  HVESP01
 SG_ HVESP01_SRS_7 : 54|2@1+ (1,0) [0|3] ""  HVESP01
 SG_ HVESP01_IsolationExtWar_7 : 52|2@1+ (1,0) [0|3] ""  HVESP01
 SG_ HVESP01_IsolationIntWar_7 : 50|2@1+ (1,0) [0|3] ""  HVESP01
 SG_ HVESP01_PyroFuseBlown_7 : 48|2@1+ (1,0) [0|3] ""  HVESP01
 SG_ HVESP01_vBrickUnderSev_7 : 62|2@1+ (1,0) [0|3] ""  HVESP01
 SG_ HVESP01_chargePrechargeTimeout_7 : 60|2@1+ (1,0) [0|3] ""  HVESP01
 SG_ HVESP01_ModuleThermFaultModerate_7 : 58|2@1+ (1,0) [0|3] ""  HVESP01
 SG_ HVESP01_ModuleThermFaultWarning_7 : 56|2@1+ (1,0) [0|3] ""  HVESP01

BO_ 2499744108 HVESP01_DiagnosticB_8: 8 HVESP01
 SG_ HVESP01_SenseBrickImpHigh_8 : 2|2@1+ (1,0) [0|3] ""  HVESP01
 SG_ HVESP01_AFEfault_8 : 0|2@1+ (1,0) [0|3] ""  HVESP01
 SG_ HVESP01_AFEerror_8 : 14|2@1+ (1,0) [0|3] ""  HVESP01
 SG_ HVESP01_HVESP01MIA_8 : 12|2@1+ (1,0) [0|3] ""  HVESP01
 SG_ HVESP01_TempAmbientOverSev_8 : 10|2@1+ (1,0) [0|3] ""  HVESP01
 SG_ HVESP01_TempAmbientOverMod_8 : 8|2@1+ (1,0) [0|3] ""  HVESP01
 SG_ HVESP01_TempAmbientOverWar_8 : 22|2@1+ (1,0) [0|3] ""  HVESP01
 SG_ HVESP01_AbnormReset_8 : 20|2@1+ (1,0) [0|3] ""  HVESP01
 SG_ HVESP01_SenseAuxVoltError_8 : 18|2@1+ (1,0) [0|3] ""  HVESP01
 SG_ HVESP01_CalibrationInvalid_8 : 16|2@1+ (1,0) [0|3] ""  HVESP01
 SG_ HVESP01_TaskLockup_8 : 30|2@1+ (1,0) [0|3] ""  HVESP01
 SG_ HVESP01_RAMover_8 : 28|2@1+ (1,0) [0|3] ""  HVESP01
 SG_ HVESP01_BrickOverdischarge_8 : 26|2@1+ (1,0) [0|3] ""  HVESP01
 SG_ HVESP01_BrickOvercharge_8 : 24|2@1+ (1,0) [0|3] ""  HVESP01
 SG_ HVESP01_vBrickImbalancePer_8 : 38|2@1+ (1,0) [0|3] ""  HVESP01
 SG_ HVESP01_TempBrickImbalance_8 : 36|2@1+ (1,0) [0|3] ""  HVESP01
 SG_ HVESP01_CapPackLow_8 : 34|2@1+ (1,0) [0|3] ""  HVESP01
 SG_ HVESP01_rBrickHigh_8 : 32|2@1+ (1,0) [0|3] ""  HVESP01
 SG_ HVESP01_PowerpackInsuffErr_8 : 46|2@1+ (1,0) [0|3] ""  HVESP01
 SG_ HVESP01_BrickSoftShort_8 : 44|2@1+ (1,0) [0|3] ""  HVESP01
 SG_ HVESP01_chargeUndercurrent_8 : 42|2@1+ (1,0) [0|3] ""  HVESP01
 SG_ HVESP01_HVILcurrentSourceError_8 : 40|2@1+ (1,0) [0|3] ""  HVESP01
 SG_ HVESP01_SRS_8 : 54|2@1+ (1,0) [0|3] ""  HVESP01
 SG_ HVESP01_IsolationExtWar_8 : 52|2@1+ (1,0) [0|3] ""  HVESP01
 SG_ HVESP01_IsolationIntWar_8 : 50|2@1+ (1,0) [0|3] ""  HVESP01
 SG_ HVESP01_PyroFuseBlown_8 : 48|2@1+ (1,0) [0|3] ""  HVESP01
 SG_ HVESP01_vBrickUnderSev_8 : 62|2@1+ (1,0) [0|3] ""  HVESP01
 SG_ HVESP01_chargePrechargeTimeout_8 : 60|2@1+ (1,0) [0|3] ""  HVESP01
 SG_ HVESP01_ModuleThermFaultModerate_8 : 58|2@1+ (1,0) [0|3] ""  HVESP01
 SG_ HVESP01_ModuleThermFaultWarning_8 : 56|2@1+ (1,0) [0|3] ""  HVESP01

BO_ 2499744357 HVESP01_DiagnosticC_1: 8 HVESP01
 SG_ HVESP01_PackVoltageImbalance_1 : 58|2@1+ (1,0) [0|3] ""  HVESP01
 SG_ HVESP01_PrechargeoverCurrent_1 : 56|2@1+ (1,0) [0|3] ""  HVESP01
 SG_ HVESP01_HVILvoltageError_1 : 2|2@1+ (1,0) [0|3] ""  HVESP01
 SG_ HVESP01_HVILcurrentReturnError_1 : 0|2@1+ (1,0) [0|3] ""  HVESP01
 SG_ HVESP01_PosContWelded_2_1 : 14|2@1+ (1,0) [0|3] ""  HVESP01
 SG_ HVESP01_PosContStuckOpen_2_1 : 12|2@1+ (1,0) [0|3] ""  HVESP01
 SG_ HVESP01_NegFcContWelded_1 : 10|2@1+ (1,0) [0|3] ""  HVESP01
 SG_ HVESP01_NegContStuckOpen_2_1 : 8|2@1+ (1,0) [0|3] ""  HVESP01
 SG_ HVESP01_IsolationIntFault_1 : 20|2@1+ (1,0) [0|3] ""  HVESP01
 SG_ HVESP01_IsolationExtFault_1 : 18|2@1+ (1,0) [0|3] ""  HVESP01
 SG_ HVESP01_12v_filter_error_1 : 16|2@1+ (1,0) [0|3] ""  HVESP01
 SG_ HVESP01_hall_eff_hi_rang_err_1 : 30|2@1+ (1,0) [0|3] ""  HVESP01
 SG_ HVESP01_brick_volt_sns_open_1 : 28|2@1+ (1,0) [0|3] ""  HVESP01
 SG_ HVESP01_5v_error_1 : 26|2@1+ (1,0) [0|3] ""  HVESP01
 SG_ HVESP01_3_3_hot_error_1 : 24|2@1+ (1,0) [0|3] ""  HVESP01
 SG_ HVESP01_12v_input_error_1 : 38|2@1+ (1,0) [0|3] ""  HVESP01
 SG_ HVESP01_1_25v_error_1 : 36|2@1+ (1,0) [0|3] ""  HVESP01
 SG_ HVESP01_shunt_MIA_1 : 34|2@1+ (1,0) [0|3] ""  HVESP01
 SG_ HVESP01_SBC_int_reg_error_1 : 32|2@1+ (1,0) [0|3] ""  HVESP01
 SG_ HVESP01_pos_3_3v_analog_error_1 : 46|2@1+ (1,0) [0|3] ""  HVESP01
 SG_ HVESP01_outlt_clnt_thrm_open_1 : 44|2@1+ (1,0) [0|3] ""  HVESP01
 SG_ HVESP01_neg_3_3_analog_error_1 : 42|2@1+ (1,0) [0|3] ""  HVESP01
 SG_ HVESP01_inlet_clnt_thrm_open_1 : 40|2@1+ (1,0) [0|3] ""  HVESP01
 SG_ HVESP01_hall_eff_lo_rang_err_1 : 54|2@1+ (1,0) [0|3] ""  HVESP01
 SG_ HVESP01_outlt_clnt_thrm_short_1 : 52|2@1+ (1,0) [0|3] ""  HVESP01
 SG_ HVESP01_inlet_clnt_thrm_short_1 : 50|2@1+ (1,0) [0|3] ""  HVESP01
 SG_ HVESP01_3_3v_error_1 : 48|2@1+ (1,0) [0|3] ""  HVESP01

BO_ 2499744358 HVESP01_DiagnosticC_2: 8 HVESP01
 SG_ HVESP01_PackVoltageImbalance_2 : 58|2@1+ (1,0) [0|3] ""  HVESP01
 SG_ HVESP01_PrechargeoverCurrent_2 : 56|2@1+ (1,0) [0|3] ""  HVESP01
 SG_ HVESP01_HVILvoltageError_2 : 2|2@1+ (1,0) [0|3] ""  HVESP01
 SG_ HVESP01_HVILcurrentReturnError_2 : 0|2@1+ (1,0) [0|3] ""  HVESP01
 SG_ HVESP01_PosContWelded_2_2 : 14|2@1+ (1,0) [0|3] ""  HVESP01
 SG_ HVESP01_PosContStuckOpen_2_2 : 12|2@1+ (1,0) [0|3] ""  HVESP01
 SG_ HVESP01_NegFcContWelded_2 : 10|2@1+ (1,0) [0|3] ""  HVESP01
 SG_ HVESP01_NegContStuckOpen_2_2 : 8|2@1+ (1,0) [0|3] ""  HVESP01
 SG_ HVESP01_IsolationIntFault_2 : 20|2@1+ (1,0) [0|3] ""  HVESP01
 SG_ HVESP01_IsolationExtFault_2 : 18|2@1+ (1,0) [0|3] ""  HVESP01
 SG_ HVESP01_12v_filter_error_2 : 16|2@1+ (1,0) [0|3] ""  HVESP01
 SG_ HVESP01_hall_eff_hi_rang_err_2 : 30|2@1+ (1,0) [0|3] ""  HVESP01
 SG_ HVESP01_brick_volt_sns_open_2 : 28|2@1+ (1,0) [0|3] ""  HVESP01
 SG_ HVESP01_5v_error_2 : 26|2@1+ (1,0) [0|3] ""  HVESP01
 SG_ HVESP01_3_3_hot_error_2 : 24|2@1+ (1,0) [0|3] ""  HVESP01
 SG_ HVESP01_12v_input_error_2 : 38|2@1+ (1,0) [0|3] ""  HVESP01
 SG_ HVESP01_1_25v_error_2 : 36|2@1+ (1,0) [0|3] ""  HVESP01
 SG_ HVESP01_shunt_MIA_2 : 34|2@1+ (1,0) [0|3] ""  HVESP01
 SG_ HVESP01_SBC_int_reg_error_2 : 32|2@1+ (1,0) [0|3] ""  HVESP01
 SG_ HVESP01_pos_3_3v_analog_error_2 : 46|2@1+ (1,0) [0|3] ""  HVESP01
 SG_ HVESP01_outlt_clnt_thrm_open_2 : 44|2@1+ (1,0) [0|3] ""  HVESP01
 SG_ HVESP01_neg_3_3_analog_error_2 : 42|2@1+ (1,0) [0|3] ""  HVESP01
 SG_ HVESP01_inlet_clnt_thrm_open_2 : 40|2@1+ (1,0) [0|3] ""  HVESP01
 SG_ HVESP01_hall_eff_lo_rang_err_2 : 54|2@1+ (1,0) [0|3] ""  HVESP01
 SG_ HVESP01_outlt_clnt_thrm_short_2 : 52|2@1+ (1,0) [0|3] ""  HVESP01
 SG_ HVESP01_inlet_clnt_thrm_short_2 : 50|2@1+ (1,0) [0|3] ""  HVESP01
 SG_ HVESP01_3_3v_error_2 : 48|2@1+ (1,0) [0|3] ""  HVESP01

BO_ 2499744359 HVESP01_DiagnosticC_3: 8 HVESP01
 SG_ HVESP01_PackVoltageImbalance_3 : 58|2@1+ (1,0) [0|3] ""  HVESP01
 SG_ HVESP01_PrechargeoverCurrent_3 : 56|2@1+ (1,0) [0|3] ""  HVESP01
 SG_ HVESP01_HVILvoltageError_3 : 2|2@1+ (1,0) [0|3] ""  HVESP01
 SG_ HVESP01_HVILcurrentReturnError_3 : 0|2@1+ (1,0) [0|3] ""  HVESP01
 SG_ HVESP01_PosContWelded_2_3 : 14|2@1+ (1,0) [0|3] ""  HVESP01
 SG_ HVESP01_PosContStuckOpen_2_3 : 12|2@1+ (1,0) [0|3] ""  HVESP01
 SG_ HVESP01_NegFcContWelded_3 : 10|2@1+ (1,0) [0|3] ""  HVESP01
 SG_ HVESP01_NegContStuckOpen_2_3 : 8|2@1+ (1,0) [0|3] ""  HVESP01
 SG_ HVESP01_IsolationIntFault_3 : 20|2@1+ (1,0) [0|3] ""  HVESP01
 SG_ HVESP01_IsolationExtFault_3 : 18|2@1+ (1,0) [0|3] ""  HVESP01
 SG_ HVESP01_12v_filter_error_3 : 16|2@1+ (1,0) [0|3] ""  HVESP01
 SG_ HVESP01_hall_eff_hi_rang_err_3 : 30|2@1+ (1,0) [0|3] ""  HVESP01
 SG_ HVESP01_brick_volt_sns_open_3 : 28|2@1+ (1,0) [0|3] ""  HVESP01
 SG_ HVESP01_5v_error_3 : 26|2@1+ (1,0) [0|3] ""  HVESP01
 SG_ HVESP01_3_3_hot_error_3 : 24|2@1+ (1,0) [0|3] ""  HVESP01
 SG_ HVESP01_12v_input_error_3 : 38|2@1+ (1,0) [0|3] ""  HVESP01
 SG_ HVESP01_1_25v_error_3 : 36|2@1+ (1,0) [0|3] ""  HVESP01
 SG_ HVESP01_shunt_MIA_3 : 34|2@1+ (1,0) [0|3] ""  HVESP01
 SG_ HVESP01_SBC_int_reg_error_3 : 32|2@1+ (1,0) [0|3] ""  HVESP01
 SG_ HVESP01_pos_3_3v_analog_error_3 : 46|2@1+ (1,0) [0|3] ""  HVESP01
 SG_ HVESP01_outlt_clnt_thrm_open_3 : 44|2@1+ (1,0) [0|3] ""  HVESP01
 SG_ HVESP01_neg_3_3_analog_error_3 : 42|2@1+ (1,0) [0|3] ""  HVESP01
 SG_ HVESP01_inlet_clnt_thrm_open_3 : 40|2@1+ (1,0) [0|3] ""  HVESP01
 SG_ HVESP01_hall_eff_lo_rang_err_3 : 54|2@1+ (1,0) [0|3] ""  HVESP01
 SG_ HVESP01_outlt_clnt_thrm_short_3 : 52|2@1+ (1,0) [0|3] ""  HVESP01
 SG_ HVESP01_inlet_clnt_thrm_short_3 : 50|2@1+ (1,0) [0|3] ""  HVESP01
 SG_ HVESP01_3_3v_error_3 : 48|2@1+ (1,0) [0|3] ""  HVESP01

BO_ 2499744360 HVESP01_DiagnosticC_4: 8 HVESP01
 SG_ HVESP01_PackVoltageImbalance_4 : 58|2@1+ (1,0) [0|3] ""  HVESP01
 SG_ HVESP01_PrechargeoverCurrent_4 : 56|2@1+ (1,0) [0|3] ""  HVESP01
 SG_ HVESP01_HVILvoltageError_4 : 2|2@1+ (1,0) [0|3] ""  HVESP01
 SG_ HVESP01_HVILcurrentReturnError_4 : 0|2@1+ (1,0) [0|3] ""  HVESP01
 SG_ HVESP01_PosContWelded_2_4 : 14|2@1+ (1,0) [0|3] ""  HVESP01
 SG_ HVESP01_PosContStuckOpen_2_4 : 12|2@1+ (1,0) [0|3] ""  HVESP01
 SG_ HVESP01_NegFcContWelded_4 : 10|2@1+ (1,0) [0|3] ""  HVESP01
 SG_ HVESP01_NegContStuckOpen_2_4 : 8|2@1+ (1,0) [0|3] ""  HVESP01
 SG_ HVESP01_IsolationIntFault_4 : 20|2@1+ (1,0) [0|3] ""  HVESP01
 SG_ HVESP01_IsolationExtFault_4 : 18|2@1+ (1,0) [0|3] ""  HVESP01
 SG_ HVESP01_12v_filter_error_4 : 16|2@1+ (1,0) [0|3] ""  HVESP01
 SG_ HVESP01_hall_eff_hi_rang_err_4 : 30|2@1+ (1,0) [0|3] ""  HVESP01
 SG_ HVESP01_brick_volt_sns_open_4 : 28|2@1+ (1,0) [0|3] ""  HVESP01
 SG_ HVESP01_5v_error_4 : 26|2@1+ (1,0) [0|3] ""  HVESP01
 SG_ HVESP01_3_3_hot_error_4 : 24|2@1+ (1,0) [0|3] ""  HVESP01
 SG_ HVESP01_12v_input_error_4 : 38|2@1+ (1,0) [0|3] ""  HVESP01
 SG_ HVESP01_1_25v_error_4 : 36|2@1+ (1,0) [0|3] ""  HVESP01
 SG_ HVESP01_shunt_MIA_4 : 34|2@1+ (1,0) [0|3] ""  HVESP01
 SG_ HVESP01_SBC_int_reg_error_4 : 32|2@1+ (1,0) [0|3] ""  HVESP01
 SG_ HVESP01_pos_3_3v_analog_error_4 : 46|2@1+ (1,0) [0|3] ""  HVESP01
 SG_ HVESP01_outlt_clnt_thrm_open_4 : 44|2@1+ (1,0) [0|3] ""  HVESP01
 SG_ HVESP01_neg_3_3_analog_error_4 : 42|2@1+ (1,0) [0|3] ""  HVESP01
 SG_ HVESP01_inlet_clnt_thrm_open_4 : 40|2@1+ (1,0) [0|3] ""  HVESP01
 SG_ HVESP01_hall_eff_lo_rang_err_4 : 54|2@1+ (1,0) [0|3] ""  HVESP01
 SG_ HVESP01_outlt_clnt_thrm_short_4 : 52|2@1+ (1,0) [0|3] ""  HVESP01
 SG_ HVESP01_inlet_clnt_thrm_short_4 : 50|2@1+ (1,0) [0|3] ""  HVESP01
 SG_ HVESP01_3_3v_error_4 : 48|2@1+ (1,0) [0|3] ""  HVESP01

BO_ 2499744361 HVESP01_DiagnosticC_5: 8 HVESP01
 SG_ HVESP01_PackVoltageImbalance_5 : 58|2@1+ (1,0) [0|3] ""  HVESP01
 SG_ HVESP01_PrechargeoverCurrent_5 : 56|2@1+ (1,0) [0|3] ""  HVESP01
 SG_ HVESP01_HVILvoltageError_5 : 2|2@1+ (1,0) [0|3] ""  HVESP01
 SG_ HVESP01_HVILcurrentReturnError_5 : 0|2@1+ (1,0) [0|3] ""  HVESP01
 SG_ HVESP01_PosContWelded_2_5 : 14|2@1+ (1,0) [0|3] ""  HVESP01
 SG_ HVESP01_PosContStuckOpen_2_5 : 12|2@1+ (1,0) [0|3] ""  HVESP01
 SG_ HVESP01_NegFcContWelded_5 : 10|2@1+ (1,0) [0|3] ""  HVESP01
 SG_ HVESP01_NegContStuckOpen_2_5 : 8|2@1+ (1,0) [0|3] ""  HVESP01
 SG_ HVESP01_IsolationIntFault_5 : 20|2@1+ (1,0) [0|3] ""  HVESP01
 SG_ HVESP01_IsolationExtFault_5 : 18|2@1+ (1,0) [0|3] ""  HVESP01
 SG_ HVESP01_12v_filter_error_5 : 16|2@1+ (1,0) [0|3] ""  HVESP01
 SG_ HVESP01_hall_eff_hi_rang_err_5 : 30|2@1+ (1,0) [0|3] ""  HVESP01
 SG_ HVESP01_brick_volt_sns_open_5 : 28|2@1+ (1,0) [0|3] ""  HVESP01
 SG_ HVESP01_5v_error_5 : 26|2@1+ (1,0) [0|3] ""  HVESP01
 SG_ HVESP01_3_3_hot_error_5 : 24|2@1+ (1,0) [0|3] ""  HVESP01
 SG_ HVESP01_12v_input_error_5 : 38|2@1+ (1,0) [0|3] ""  HVESP01
 SG_ HVESP01_1_25v_error_5 : 36|2@1+ (1,0) [0|3] ""  HVESP01
 SG_ HVESP01_shunt_MIA_5 : 34|2@1+ (1,0) [0|3] ""  HVESP01
 SG_ HVESP01_SBC_int_reg_error_5 : 32|2@1+ (1,0) [0|3] ""  HVESP01
 SG_ HVESP01_pos_3_3v_analog_error_5 : 46|2@1+ (1,0) [0|3] ""  HVESP01
 SG_ HVESP01_outlt_clnt_thrm_open_5 : 44|2@1+ (1,0) [0|3] ""  HVESP01
 SG_ HVESP01_neg_3_3_analog_error_5 : 42|2@1+ (1,0) [0|3] ""  HVESP01
 SG_ HVESP01_inlet_clnt_thrm_open_5 : 40|2@1+ (1,0) [0|3] ""  HVESP01
 SG_ HVESP01_hall_eff_lo_rang_err_5 : 54|2@1+ (1,0) [0|3] ""  HVESP01
 SG_ HVESP01_outlt_clnt_thrm_short_5 : 52|2@1+ (1,0) [0|3] ""  HVESP01
 SG_ HVESP01_inlet_clnt_thrm_short_5 : 50|2@1+ (1,0) [0|3] ""  HVESP01
 SG_ HVESP01_3_3v_error_5 : 48|2@1+ (1,0) [0|3] ""  HVESP01

BO_ 2499744362 HVESP01_DiagnosticC_6: 8 HVESP01
 SG_ HVESP01_PackVoltageImbalance_6 : 58|2@1+ (1,0) [0|3] ""  HVESP01
 SG_ HVESP01_PrechargeoverCurrent_6 : 56|2@1+ (1,0) [0|3] ""  HVESP01
 SG_ HVESP01_HVILvoltageError_6 : 2|2@1+ (1,0) [0|3] ""  HVESP01
 SG_ HVESP01_HVILcurrentReturnError_6 : 0|2@1+ (1,0) [0|3] ""  HVESP01
 SG_ HVESP01_PosContWelded_2_6 : 14|2@1+ (1,0) [0|3] ""  HVESP01
 SG_ HVESP01_PosContStuckOpen_2_6 : 12|2@1+ (1,0) [0|3] ""  HVESP01
 SG_ HVESP01_NegFcContWelded_6 : 10|2@1+ (1,0) [0|3] ""  HVESP01
 SG_ HVESP01_NegContStuckOpen_2_6 : 8|2@1+ (1,0) [0|3] ""  HVESP01
 SG_ HVESP01_IsolationIntFault_6 : 20|2@1+ (1,0) [0|3] ""  HVESP01
 SG_ HVESP01_IsolationExtFault_6 : 18|2@1+ (1,0) [0|3] ""  HVESP01
 SG_ HVESP01_12v_filter_error_6 : 16|2@1+ (1,0) [0|3] ""  HVESP01
 SG_ HVESP01_hall_eff_hi_rang_err_6 : 30|2@1+ (1,0) [0|3] ""  HVESP01
 SG_ HVESP01_brick_volt_sns_open_6 : 28|2@1+ (1,0) [0|3] ""  HVESP01
 SG_ HVESP01_5v_error_6 : 26|2@1+ (1,0) [0|3] ""  HVESP01
 SG_ HVESP01_3_3_hot_error_6 : 24|2@1+ (1,0) [0|3] ""  HVESP01
 SG_ HVESP01_12v_input_error_6 : 38|2@1+ (1,0) [0|3] ""  HVESP01
 SG_ HVESP01_1_25v_error_6 : 36|2@1+ (1,0) [0|3] ""  HVESP01
 SG_ HVESP01_shunt_MIA_6 : 34|2@1+ (1,0) [0|3] ""  HVESP01
 SG_ HVESP01_SBC_int_reg_error_6 : 32|2@1+ (1,0) [0|3] ""  HVESP01
 SG_ HVESP01_pos_3_3v_analog_error_6 : 46|2@1+ (1,0) [0|3] ""  HVESP01
 SG_ HVESP01_outlt_clnt_thrm_open_6 : 44|2@1+ (1,0) [0|3] ""  HVESP01
 SG_ HVESP01_neg_3_3_analog_error_6 : 42|2@1+ (1,0) [0|3] ""  HVESP01
 SG_ HVESP01_inlet_clnt_thrm_open_6 : 40|2@1+ (1,0) [0|3] ""  HVESP01
 SG_ HVESP01_hall_eff_lo_rang_err_6 : 54|2@1+ (1,0) [0|3] ""  HVESP01
 SG_ HVESP01_outlt_clnt_thrm_short_6 : 52|2@1+ (1,0) [0|3] ""  HVESP01
 SG_ HVESP01_inlet_clnt_thrm_short_6 : 50|2@1+ (1,0) [0|3] ""  HVESP01
 SG_ HVESP01_3_3v_error_6 : 48|2@1+ (1,0) [0|3] ""  HVESP01

BO_ 2499744363 HVESP01_DiagnosticC_7: 8 HVESP01
 SG_ HVESP01_PackVoltageImbalance_7 : 58|2@1+ (1,0) [0|3] ""  HVESP01
 SG_ HVESP01_PrechargeoverCurrent_7 : 56|2@1+ (1,0) [0|3] ""  HVESP01
 SG_ HVESP01_HVILvoltageError_7 : 2|2@1+ (1,0) [0|3] ""  HVESP01
 SG_ HVESP01_HVILcurrentReturnError_7 : 0|2@1+ (1,0) [0|3] ""  HVESP01
 SG_ HVESP01_PosContWelded_2_7 : 14|2@1+ (1,0) [0|3] ""  HVESP01
 SG_ HVESP01_PosContStuckOpen_2_7 : 12|2@1+ (1,0) [0|3] ""  HVESP01
 SG_ HVESP01_NegFcContWelded_7 : 10|2@1+ (1,0) [0|3] ""  HVESP01
 SG_ HVESP01_NegContStuckOpen_2_7 : 8|2@1+ (1,0) [0|3] ""  HVESP01
 SG_ HVESP01_IsolationIntFault_7 : 20|2@1+ (1,0) [0|3] ""  HVESP01
 SG_ HVESP01_IsolationExtFault_7 : 18|2@1+ (1,0) [0|3] ""  HVESP01
 SG_ HVESP01_12v_filter_error_7 : 16|2@1+ (1,0) [0|3] ""  HVESP01
 SG_ HVESP01_hall_eff_hi_rang_err_7 : 30|2@1+ (1,0) [0|3] ""  HVESP01
 SG_ HVESP01_brick_volt_sns_open_7 : 28|2@1+ (1,0) [0|3] ""  HVESP01
 SG_ HVESP01_5v_error_7 : 26|2@1+ (1,0) [0|3] ""  HVESP01
 SG_ HVESP01_3_3_hot_error_7 : 24|2@1+ (1,0) [0|3] ""  HVESP01
 SG_ HVESP01_12v_input_error_7 : 38|2@1+ (1,0) [0|3] ""  HVESP01
 SG_ HVESP01_1_25v_error_7 : 36|2@1+ (1,0) [0|3] ""  HVESP01
 SG_ HVESP01_shunt_MIA_7 : 34|2@1+ (1,0) [0|3] ""  HVESP01
 SG_ HVESP01_SBC_int_reg_error_7 : 32|2@1+ (1,0) [0|3] ""  HVESP01
 SG_ HVESP01_pos_3_3v_analog_error_7 : 46|2@1+ (1,0) [0|3] ""  HVESP01
 SG_ HVESP01_outlt_clnt_thrm_open_7 : 44|2@1+ (1,0) [0|3] ""  HVESP01
 SG_ HVESP01_neg_3_3_analog_error_7 : 42|2@1+ (1,0) [0|3] ""  HVESP01
 SG_ HVESP01_inlet_clnt_thrm_open_7 : 40|2@1+ (1,0) [0|3] ""  HVESP01
 SG_ HVESP01_hall_eff_lo_rang_err_7 : 54|2@1+ (1,0) [0|3] ""  HVESP01
 SG_ HVESP01_outlt_clnt_thrm_short_7 : 52|2@1+ (1,0) [0|3] ""  HVESP01
 SG_ HVESP01_inlet_clnt_thrm_short_7 : 50|2@1+ (1,0) [0|3] ""  HVESP01
 SG_ HVESP01_3_3v_error_7 : 48|2@1+ (1,0) [0|3] ""  HVESP01

BO_ 2499744364 HVESP01_DiagnosticC_8: 8 HVESP01
 SG_ HVESP01_PackVoltageImbalance_8 : 58|2@1+ (1,0) [0|3] ""  HVESP01
 SG_ HVESP01_PrechargeoverCurrent_8 : 56|2@1+ (1,0) [0|3] ""  HVESP01
 SG_ HVESP01_HVILvoltageError_8 : 2|2@1+ (1,0) [0|3] ""  HVESP01
 SG_ HVESP01_HVILcurrentReturnError_8 : 0|2@1+ (1,0) [0|3] ""  HVESP01
 SG_ HVESP01_PosContWelded_2_8 : 14|2@1+ (1,0) [0|3] ""  HVESP01
 SG_ HVESP01_PosContStuckOpen_2_8 : 12|2@1+ (1,0) [0|3] ""  HVESP01
 SG_ HVESP01_NegFcContWelded_8 : 10|2@1+ (1,0) [0|3] ""  HVESP01
 SG_ HVESP01_NegContStuckOpen_2_8 : 8|2@1+ (1,0) [0|3] ""  HVESP01
 SG_ HVESP01_IsolationIntFault_8 : 20|2@1+ (1,0) [0|3] ""  HVESP01
 SG_ HVESP01_IsolationExtFault_8 : 18|2@1+ (1,0) [0|3] ""  HVESP01
 SG_ HVESP01_12v_filter_error_8 : 16|2@1+ (1,0) [0|3] ""  HVESP01
 SG_ HVESP01_hall_eff_hi_rang_err_8 : 30|2@1+ (1,0) [0|3] ""  HVESP01
 SG_ HVESP01_brick_volt_sns_open_8 : 28|2@1+ (1,0) [0|3] ""  HVESP01
 SG_ HVESP01_5v_error_8 : 26|2@1+ (1,0) [0|3] ""  HVESP01
 SG_ HVESP01_3_3_hot_error_8 : 24|2@1+ (1,0) [0|3] ""  HVESP01
 SG_ HVESP01_12v_input_error_8 : 38|2@1+ (1,0) [0|3] ""  HVESP01
 SG_ HVESP01_1_25v_error_8 : 36|2@1+ (1,0) [0|3] ""  HVESP01
 SG_ HVESP01_shunt_MIA_8 : 34|2@1+ (1,0) [0|3] ""  HVESP01
 SG_ HVESP01_SBC_int_reg_error_8 : 32|2@1+ (1,0) [0|3] ""  HVESP01
 SG_ HVESP01_pos_3_3v_analog_error_8 : 46|2@1+ (1,0) [0|3] ""  HVESP01
 SG_ HVESP01_outlt_clnt_thrm_open_8 : 44|2@1+ (1,0) [0|3] ""  HVESP01
 SG_ HVESP01_neg_3_3_analog_error_8 : 42|2@1+ (1,0) [0|3] ""  HVESP01
 SG_ HVESP01_inlet_clnt_thrm_open_8 : 40|2@1+ (1,0) [0|3] ""  HVESP01
 SG_ HVESP01_hall_eff_lo_rang_err_8 : 54|2@1+ (1,0) [0|3] ""  HVESP01
 SG_ HVESP01_outlt_clnt_thrm_short_8 : 52|2@1+ (1,0) [0|3] ""  HVESP01
 SG_ HVESP01_inlet_clnt_thrm_short_8 : 50|2@1+ (1,0) [0|3] ""  HVESP01
 SG_ HVESP01_3_3v_error_8 : 48|2@1+ (1,0) [0|3] ""  HVESP01

BO_ 2499744613 HVESP01_DiagnosticD_1: 8 HVESP01
 SG_ HVESP01_BusJoinFailed_1 : 10|2@1+ (1,0) [0|3] ""  HVESP01
 SG_ HVESP01_ModuleThermFaultSevere_1 : 8|2@1+ (1,0) [0|3] ""  HVESP01
 SG_ HVESP01_Placeholder11_1 : 22|2@1+ (1,0) [0|3] ""  HVESP01
 SG_ HVESP01_HardwareUvloError_1 : 20|2@1+ (1,0) [0|3] ""  HVESP01
 SG_ HVESP01_Placeholder02_1 : 46|2@1+ (1,0) [0|3] ""  HVESP01
 SG_ HVESP01_Placeholder01_1 : 44|2@1+ (1,0) [0|3] ""  HVESP01
 SG_ HVESP01_HardwareOVError_1 : 18|2@1+ (1,0) [0|3] ""  HVESP01
 SG_ HVESP01_DoubleDcContWeld_1 : 16|2@1+ (1,0) [0|3] ""  HVESP01
 SG_ HVESP01_CurrentMismatch_1 : 30|2@1+ (1,0) [0|3] ""  HVESP01
 SG_ HVESP01_vBrickImbalanceWar_1 : 28|2@1+ (1,0) [0|3] ""  HVESP01
 SG_ HVESP01_vBrickImbalanceMod_1 : 26|2@1+ (1,0) [0|3] ""  HVESP01
 SG_ HVESP01_vBrickImbalanceSev_1 : 24|2@1+ (1,0) [0|3] ""  HVESP01
 SG_ HVESP01_Placeholder06_1 : 38|2@1+ (1,0) [0|3] ""  HVESP01
 SG_ HVESP01_Placeholder05_1 : 36|2@1+ (1,0) [0|3] ""  HVESP01
 SG_ HVESP01_SpeakerMia_1 : 2|2@1+ (1,0) [0|3] ""  HVESP01
 SG_ HVESP01_IsoSpiBreak_1 : 0|2@1+ (1,0) [0|3] ""  HVESP01
 SG_ HVESP01_VersionMismatch_1 : 14|2@1+ (1,0) [0|3] ""  HVESP01
 SG_ HVESP01_SystemPrechargeFail_1 : 12|2@1+ (1,0) [0|3] ""  HVESP01
 SG_ HVESP01_Placeholder04_1 : 34|2@1+ (1,0) [0|3] ""  HVESP01
 SG_ HVESP01_Placeholder03_1 : 32|2@1+ (1,0) [0|3] ""  HVESP01

BO_ 2499744614 HVESP01_DiagnosticD_2: 8 HVESP01
 SG_ HVESP01_BusJoinFailed_2 : 10|2@1+ (1,0) [0|3] ""  HVESP01
 SG_ HVESP01_ModuleThermFaultSevere_2 : 8|2@1+ (1,0) [0|3] ""  HVESP01
 SG_ HVESP01_Placeholder11_2 : 22|2@1+ (1,0) [0|3] ""  HVESP01
 SG_ HVESP01_HardwareUvloError_2 : 20|2@1+ (1,0) [0|3] ""  HVESP01
 SG_ HVESP01_Placeholder02_2 : 46|2@1+ (1,0) [0|3] ""  HVESP01
 SG_ HVESP01_Placeholder01_2 : 44|2@1+ (1,0) [0|3] ""  HVESP01
 SG_ HVESP01_HardwareOVError_2 : 18|2@1+ (1,0) [0|3] ""  HVESP01
 SG_ HVESP01_DoubleDcContWeld_2 : 16|2@1+ (1,0) [0|3] ""  HVESP01
 SG_ HVESP01_CurrentMismatch_2 : 30|2@1+ (1,0) [0|3] ""  HVESP01
 SG_ HVESP01_vBrickImbalanceWar_2 : 28|2@1+ (1,0) [0|3] ""  HVESP01
 SG_ HVESP01_vBrickImbalanceMod_2 : 26|2@1+ (1,0) [0|3] ""  HVESP01
 SG_ HVESP01_vBrickImbalanceSev_2 : 24|2@1+ (1,0) [0|3] ""  HVESP01
 SG_ HVESP01_Placeholder06_2 : 38|2@1+ (1,0) [0|3] ""  HVESP01
 SG_ HVESP01_Placeholder05_2 : 36|2@1+ (1,0) [0|3] ""  HVESP01
 SG_ HVESP01_SpeakerMia_2 : 2|2@1+ (1,0) [0|3] ""  HVESP01
 SG_ HVESP01_IsoSpiBreak_2 : 0|2@1+ (1,0) [0|3] ""  HVESP01
 SG_ HVESP01_VersionMismatch_2 : 14|2@1+ (1,0) [0|3] ""  HVESP01
 SG_ HVESP01_SystemPrechargeFail_2 : 12|2@1+ (1,0) [0|3] ""  HVESP01
 SG_ HVESP01_Placeholder04_2 : 34|2@1+ (1,0) [0|3] ""  HVESP01
 SG_ HVESP01_Placeholder03_2 : 32|2@1+ (1,0) [0|3] ""  HVESP01

BO_ 2499744615 HVESP01_DiagnosticD_3: 8 HVESP01
 SG_ HVESP01_BusJoinFailed_3 : 10|2@1+ (1,0) [0|3] ""  HVESP01
 SG_ HVESP01_ModuleThermFaultSevere_3 : 8|2@1+ (1,0) [0|3] ""  HVESP01
 SG_ HVESP01_Placeholder11_3 : 22|2@1+ (1,0) [0|3] ""  HVESP01
 SG_ HVESP01_HardwareUvloError_3 : 20|2@1+ (1,0) [0|3] ""  HVESP01
 SG_ HVESP01_Placeholder02_3 : 46|2@1+ (1,0) [0|3] ""  HVESP01
 SG_ HVESP01_Placeholder01_3 : 44|2@1+ (1,0) [0|3] ""  HVESP01
 SG_ HVESP01_HardwareOVError_3 : 18|2@1+ (1,0) [0|3] ""  HVESP01
 SG_ HVESP01_DoubleDcContWeld_3 : 16|2@1+ (1,0) [0|3] ""  HVESP01
 SG_ HVESP01_CurrentMismatch_3 : 30|2@1+ (1,0) [0|3] ""  HVESP01
 SG_ HVESP01_vBrickImbalanceWar_3 : 28|2@1+ (1,0) [0|3] ""  HVESP01
 SG_ HVESP01_vBrickImbalanceMod_3 : 26|2@1+ (1,0) [0|3] ""  HVESP01
 SG_ HVESP01_vBrickImbalanceSev_3 : 24|2@1+ (1,0) [0|3] ""  HVESP01
 SG_ HVESP01_Placeholder06_3 : 38|2@1+ (1,0) [0|3] ""  HVESP01
 SG_ HVESP01_Placeholder05_3 : 36|2@1+ (1,0) [0|3] ""  HVESP01
 SG_ HVESP01_SpeakerMia_3 : 2|2@1+ (1,0) [0|3] ""  HVESP01
 SG_ HVESP01_IsoSpiBreak_3 : 0|2@1+ (1,0) [0|3] ""  HVESP01
 SG_ HVESP01_VersionMismatch_3 : 14|2@1+ (1,0) [0|3] ""  HVESP01
 SG_ HVESP01_SystemPrechargeFail_3 : 12|2@1+ (1,0) [0|3] ""  HVESP01
 SG_ HVESP01_Placeholder04_3 : 34|2@1+ (1,0) [0|3] ""  HVESP01
 SG_ HVESP01_Placeholder03_3 : 32|2@1+ (1,0) [0|3] ""  HVESP01

BO_ 2499744616 HVESP01_DiagnosticD_4: 8 HVESP01
 SG_ HVESP01_BusJoinFailed_4 : 10|2@1+ (1,0) [0|3] ""  HVESP01
 SG_ HVESP01_ModuleThermFaultSevere_4 : 8|2@1+ (1,0) [0|3] ""  HVESP01
 SG_ HVESP01_Placeholder11_4 : 22|2@1+ (1,0) [0|3] ""  HVESP01
 SG_ HVESP01_HardwareUvloError_4 : 20|2@1+ (1,0) [0|3] ""  HVESP01
 SG_ HVESP01_Placeholder02_4 : 46|2@1+ (1,0) [0|3] ""  HVESP01
 SG_ HVESP01_Placeholder01_4 : 44|2@1+ (1,0) [0|3] ""  HVESP01
 SG_ HVESP01_HardwareOVError_4 : 18|2@1+ (1,0) [0|3] ""  HVESP01
 SG_ HVESP01_DoubleDcContWeld_4 : 16|2@1+ (1,0) [0|3] ""  HVESP01
 SG_ HVESP01_CurrentMismatch_4 : 30|2@1+ (1,0) [0|3] ""  HVESP01
 SG_ HVESP01_vBrickImbalanceWar_4 : 28|2@1+ (1,0) [0|3] ""  HVESP01
 SG_ HVESP01_vBrickImbalanceMod_4 : 26|2@1+ (1,0) [0|3] ""  HVESP01
 SG_ HVESP01_vBrickImbalanceSev_4 : 24|2@1+ (1,0) [0|3] ""  HVESP01
 SG_ HVESP01_Placeholder06_4 : 38|2@1+ (1,0) [0|3] ""  HVESP01
 SG_ HVESP01_Placeholder05_4 : 36|2@1+ (1,0) [0|3] ""  HVESP01
 SG_ HVESP01_SpeakerMia_4 : 2|2@1+ (1,0) [0|3] ""  HVESP01
 SG_ HVESP01_IsoSpiBreak_4 : 0|2@1+ (1,0) [0|3] ""  HVESP01
 SG_ HVESP01_VersionMismatch_4 : 14|2@1+ (1,0) [0|3] ""  HVESP01
 SG_ HVESP01_SystemPrechargeFail_4 : 12|2@1+ (1,0) [0|3] ""  HVESP01
 SG_ HVESP01_Placeholder04_4 : 34|2@1+ (1,0) [0|3] ""  HVESP01
 SG_ HVESP01_Placeholder03_4 : 32|2@1+ (1,0) [0|3] ""  HVESP01

BO_ 2499744617 HVESP01_DiagnosticD_5: 8 HVESP01
 SG_ HVESP01_BusJoinFailed_5 : 10|2@1+ (1,0) [0|3] ""  HVESP01
 SG_ HVESP01_ModuleThermFaultSevere_5 : 8|2@1+ (1,0) [0|3] ""  HVESP01
 SG_ HVESP01_Placeholder11_5 : 22|2@1+ (1,0) [0|3] ""  HVESP01
 SG_ HVESP01_HardwareUvloError_5 : 20|2@1+ (1,0) [0|3] ""  HVESP01
 SG_ HVESP01_Placeholder02_5 : 46|2@1+ (1,0) [0|3] ""  HVESP01
 SG_ HVESP01_Placeholder01_5 : 44|2@1+ (1,0) [0|3] ""  HVESP01
 SG_ HVESP01_HardwareOVError_5 : 18|2@1+ (1,0) [0|3] ""  HVESP01
 SG_ HVESP01_DoubleDcContWeld_5 : 16|2@1+ (1,0) [0|3] ""  HVESP01
 SG_ HVESP01_CurrentMismatch_5 : 30|2@1+ (1,0) [0|3] ""  HVESP01
 SG_ HVESP01_vBrickImbalanceWar_5 : 28|2@1+ (1,0) [0|3] ""  HVESP01
 SG_ HVESP01_vBrickImbalanceMod_5 : 26|2@1+ (1,0) [0|3] ""  HVESP01
 SG_ HVESP01_vBrickImbalanceSev_5 : 24|2@1+ (1,0) [0|3] ""  HVESP01
 SG_ HVESP01_Placeholder06_5 : 38|2@1+ (1,0) [0|3] ""  HVESP01
 SG_ HVESP01_Placeholder05_5 : 36|2@1+ (1,0) [0|3] ""  HVESP01
 SG_ HVESP01_SpeakerMia_5 : 2|2@1+ (1,0) [0|3] ""  HVESP01
 SG_ HVESP01_IsoSpiBreak_5 : 0|2@1+ (1,0) [0|3] ""  HVESP01
 SG_ HVESP01_VersionMismatch_5 : 14|2@1+ (1,0) [0|3] ""  HVESP01
 SG_ HVESP01_SystemPrechargeFail_5 : 12|2@1+ (1,0) [0|3] ""  HVESP01
 SG_ HVESP01_Placeholder04_5 : 34|2@1+ (1,0) [0|3] ""  HVESP01
 SG_ HVESP01_Placeholder03_5 : 32|2@1+ (1,0) [0|3] ""  HVESP01

BO_ 2499744618 HVESP01_DiagnosticD_6: 8 HVESP01
 SG_ HVESP01_BusJoinFailed_6 : 10|2@1+ (1,0) [0|3] ""  HVESP01
 SG_ HVESP01_ModuleThermFaultSevere_6 : 8|2@1+ (1,0) [0|3] ""  HVESP01
 SG_ HVESP01_Placeholder11_6 : 22|2@1+ (1,0) [0|3] ""  HVESP01
 SG_ HVESP01_HardwareUvloError_6 : 20|2@1+ (1,0) [0|3] ""  HVESP01
 SG_ HVESP01_Placeholder02_6 : 46|2@1+ (1,0) [0|3] ""  HVESP01
 SG_ HVESP01_Placeholder01_6 : 44|2@1+ (1,0) [0|3] ""  HVESP01
 SG_ HVESP01_HardwareOVError_6 : 18|2@1+ (1,0) [0|3] ""  HVESP01
 SG_ HVESP01_DoubleDcContWeld_6 : 16|2@1+ (1,0) [0|3] ""  HVESP01
 SG_ HVESP01_CurrentMismatch_6 : 30|2@1+ (1,0) [0|3] ""  HVESP01
 SG_ HVESP01_vBrickImbalanceWar_6 : 28|2@1+ (1,0) [0|3] ""  HVESP01
 SG_ HVESP01_vBrickImbalanceMod_6 : 26|2@1+ (1,0) [0|3] ""  HVESP01
 SG_ HVESP01_vBrickImbalanceSev_6 : 24|2@1+ (1,0) [0|3] ""  HVESP01
 SG_ HVESP01_Placeholder06_6 : 38|2@1+ (1,0) [0|3] ""  HVESP01
 SG_ HVESP01_Placeholder05_6 : 36|2@1+ (1,0) [0|3] ""  HVESP01
 SG_ HVESP01_SpeakerMia_6 : 2|2@1+ (1,0) [0|3] ""  HVESP01
 SG_ HVESP01_IsoSpiBreak_6 : 0|2@1+ (1,0) [0|3] ""  HVESP01
 SG_ HVESP01_VersionMismatch_6 : 14|2@1+ (1,0) [0|3] ""  HVESP01
 SG_ HVESP01_SystemPrechargeFail_6 : 12|2@1+ (1,0) [0|3] ""  HVESP01
 SG_ HVESP01_Placeholder04_6 : 34|2@1+ (1,0) [0|3] ""  HVESP01
 SG_ HVESP01_Placeholder03_6 : 32|2@1+ (1,0) [0|3] ""  HVESP01

BO_ 2499744619 HVESP01_DiagnosticD_7: 8 HVESP01
 SG_ HVESP01_BusJoinFailed_7 : 10|2@1+ (1,0) [0|3] ""  HVESP01
 SG_ HVESP01_ModuleThermFaultSevere_7 : 8|2@1+ (1,0) [0|3] ""  HVESP01
 SG_ HVESP01_Placeholder11_7 : 22|2@1+ (1,0) [0|3] ""  HVESP01
 SG_ HVESP01_HardwareUvloError_7 : 20|2@1+ (1,0) [0|3] ""  HVESP01
 SG_ HVESP01_Placeholder02_7 : 46|2@1+ (1,0) [0|3] ""  HVESP01
 SG_ HVESP01_Placeholder01_7 : 44|2@1+ (1,0) [0|3] ""  HVESP01
 SG_ HVESP01_HardwareOVError_7 : 18|2@1+ (1,0) [0|3] ""  HVESP01
 SG_ HVESP01_DoubleDcContWeld_7 : 16|2@1+ (1,0) [0|3] ""  HVESP01
 SG_ HVESP01_CurrentMismatch_7 : 30|2@1+ (1,0) [0|3] ""  HVESP01
 SG_ HVESP01_vBrickImbalanceWar_7 : 28|2@1+ (1,0) [0|3] ""  HVESP01
 SG_ HVESP01_vBrickImbalanceMod_7 : 26|2@1+ (1,0) [0|3] ""  HVESP01
 SG_ HVESP01_vBrickImbalanceSev_7 : 24|2@1+ (1,0) [0|3] ""  HVESP01
 SG_ HVESP01_Placeholder06_7 : 38|2@1+ (1,0) [0|3] ""  HVESP01
 SG_ HVESP01_Placeholder05_7 : 36|2@1+ (1,0) [0|3] ""  HVESP01
 SG_ HVESP01_SpeakerMia_7 : 2|2@1+ (1,0) [0|3] ""  HVESP01
 SG_ HVESP01_IsoSpiBreak_7 : 0|2@1+ (1,0) [0|3] ""  HVESP01
 SG_ HVESP01_VersionMismatch_7 : 14|2@1+ (1,0) [0|3] ""  HVESP01
 SG_ HVESP01_SystemPrechargeFail_7 : 12|2@1+ (1,0) [0|3] ""  HVESP01
 SG_ HVESP01_Placeholder04_7 : 34|2@1+ (1,0) [0|3] ""  HVESP01
 SG_ HVESP01_Placeholder03_7 : 32|2@1+ (1,0) [0|3] ""  HVESP01

BO_ 2499744620 HVESP01_DiagnosticD_8: 8 HVESP01
 SG_ HVESP01_BusJoinFailed_8 : 10|2@1+ (1,0) [0|3] ""  HVESP01
 SG_ HVESP01_ModuleThermFaultSevere_8 : 8|2@1+ (1,0) [0|3] ""  HVESP01
 SG_ HVESP01_Placeholder11_8 : 22|2@1+ (1,0) [0|3] ""  HVESP01
 SG_ HVESP01_HardwareUvloError_8 : 20|2@1+ (1,0) [0|3] ""  HVESP01
 SG_ HVESP01_Placeholder02_8 : 46|2@1+ (1,0) [0|3] ""  HVESP01
 SG_ HVESP01_Placeholder01_8 : 44|2@1+ (1,0) [0|3] ""  HVESP01
 SG_ HVESP01_HardwareOVError_8 : 18|2@1+ (1,0) [0|3] ""  HVESP01
 SG_ HVESP01_DoubleDcContWeld_8 : 16|2@1+ (1,0) [0|3] ""  HVESP01
 SG_ HVESP01_CurrentMismatch_8 : 30|2@1+ (1,0) [0|3] ""  HVESP01
 SG_ HVESP01_vBrickImbalanceWar_8 : 28|2@1+ (1,0) [0|3] ""  HVESP01
 SG_ HVESP01_vBrickImbalanceMod_8 : 26|2@1+ (1,0) [0|3] ""  HVESP01
 SG_ HVESP01_vBrickImbalanceSev_8 : 24|2@1+ (1,0) [0|3] ""  HVESP01
 SG_ HVESP01_Placeholder06_8 : 38|2@1+ (1,0) [0|3] ""  HVESP01
 SG_ HVESP01_Placeholder05_8 : 36|2@1+ (1,0) [0|3] ""  HVESP01
 SG_ HVESP01_SpeakerMia_8 : 2|2@1+ (1,0) [0|3] ""  HVESP01
 SG_ HVESP01_IsoSpiBreak_8 : 0|2@1+ (1,0) [0|3] ""  HVESP01
 SG_ HVESP01_VersionMismatch_8 : 14|2@1+ (1,0) [0|3] ""  HVESP01
 SG_ HVESP01_SystemPrechargeFail_8 : 12|2@1+ (1,0) [0|3] ""  HVESP01
 SG_ HVESP01_Placeholder04_8 : 34|2@1+ (1,0) [0|3] ""  HVESP01
 SG_ HVESP01_Placeholder03_8 : 32|2@1+ (1,0) [0|3] ""  HVESP01

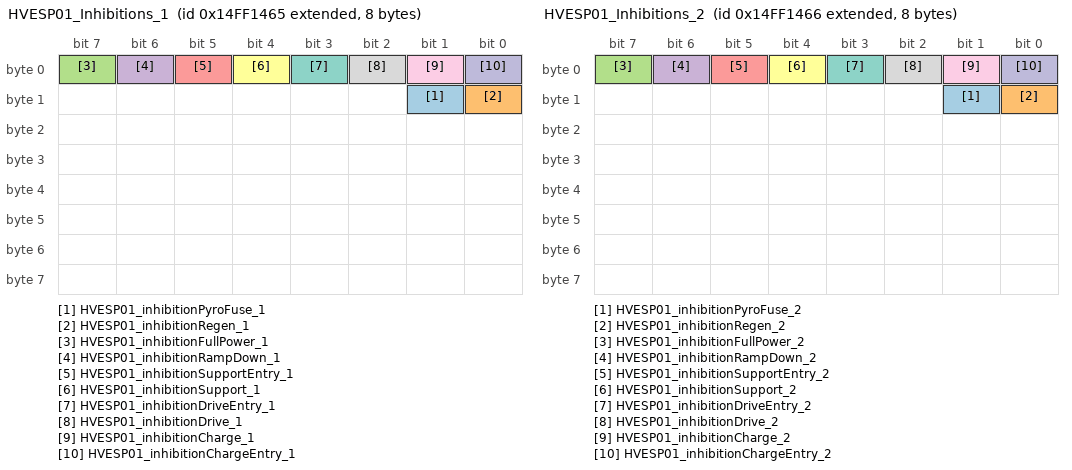
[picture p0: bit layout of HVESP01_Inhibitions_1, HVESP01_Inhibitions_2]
BO_ 2499744869 HVESP01_Inhibitions_1: 8 HVESP01
 SG_ HVESP01_inhibitionPyroFuse_1 : 9|1@1+ (1,0) [0|1] ""  HVESP01
 SG_ HVESP01_inhibitionRegen_1 : 8|1@1+ (1,0) [0|1] ""  HVESP01
 SG_ HVESP01_inhibitionFullPower_1 : 7|1@1+ (1,0) [0|1] ""  HVESP01
 SG_ HVESP01_inhibitionRampDown_1 : 6|1@1+ (1,0) [0|1] ""  HVESP01
 SG_ HVESP01_inhibitionSupportEntry_1 : 5|1@1+ (1,0) [0|1] ""  HVESP01
 SG_ HVESP01_inhibitionSupport_1 : 4|1@1+ (1,0) [0|1] ""  HVESP01
 SG_ HVESP01_inhibitionDriveEntry_1 : 3|1@1+ (1,0) [0|1] ""  HVESP01
 SG_ HVESP01_inhibitionDrive_1 : 2|1@1+ (1,0) [0|1] ""  HVESP01
 SG_ HVESP01_inhibitionCharge_1 : 1|1@1+ (1,0) [0|1] ""  HVESP01
 SG_ HVESP01_inhibitionChargeEntry_1 : 0|1@1+ (1,0) [0|1] ""  HVESP01

BO_ 2499744870 HVESP01_Inhibitions_2: 8 HVESP01
 SG_ HVESP01_inhibitionPyroFuse_2 : 9|1@1+ (1,0) [0|1] ""  HVESP01
 SG_ HVESP01_inhibitionRegen_2 : 8|1@1+ (1,0) [0|1] ""  HVESP01
 SG_ HVESP01_inhibitionFullPower_2 : 7|1@1+ (1,0) [0|1] ""  HVESP01
 SG_ HVESP01_inhibitionRampDown_2 : 6|1@1+ (1,0) [0|1] ""  HVESP01
 SG_ HVESP01_inhibitionSupportEntry_2 : 5|1@1+ (1,0) [0|1] ""  HVESP01
 SG_ HVESP01_inhibitionSupport_2 : 4|1@1+ (1,0) [0|1] ""  HVESP01
 SG_ HVESP01_inhibitionDriveEntry_2 : 3|1@1+ (1,0) [0|1] ""  HVESP01
 SG_ HVESP01_inhibitionDrive_2 : 2|1@1+ (1,0) [0|1] ""  HVESP01
 SG_ HVESP01_inhibitionCharge_2 : 1|1@1+ (1,0) [0|1] ""  HVESP01
 SG_ HVESP01_inhibitionChargeEntry_2 : 0|1@1+ (1,0) [0|1] ""  HVESP01

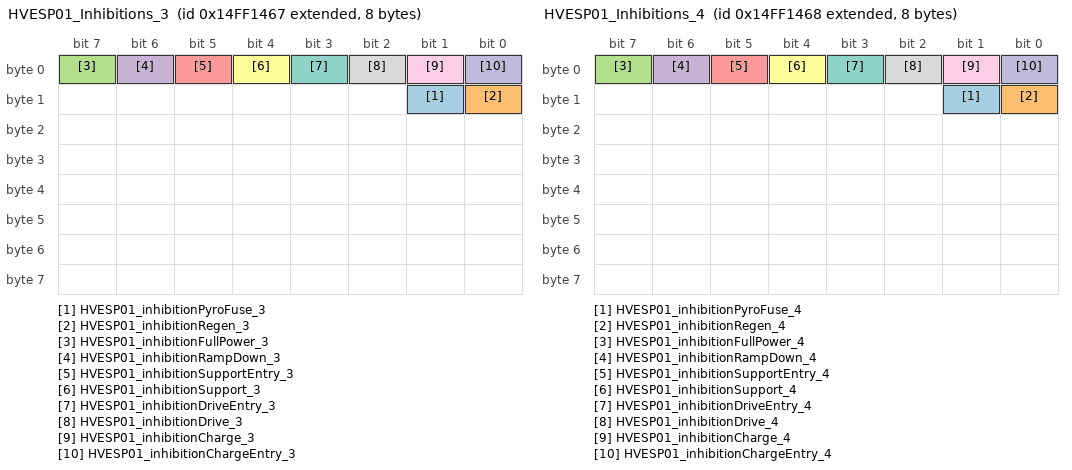
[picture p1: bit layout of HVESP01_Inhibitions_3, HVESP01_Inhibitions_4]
BO_ 2499744871 HVESP01_Inhibitions_3: 8 HVESP01
 SG_ HVESP01_inhibitionPyroFuse_3 : 9|1@1+ (1,0) [0|1] ""  HVESP01
 SG_ HVESP01_inhibitionRegen_3 : 8|1@1+ (1,0) [0|1] ""  HVESP01
 SG_ HVESP01_inhibitionFullPower_3 : 7|1@1+ (1,0) [0|1] ""  HVESP01
 SG_ HVESP01_inhibitionRampDown_3 : 6|1@1+ (1,0) [0|1] ""  HVESP01
 SG_ HVESP01_inhibitionSupportEntry_3 : 5|1@1+ (1,0) [0|1] ""  HVESP01
 SG_ HVESP01_inhibitionSupport_3 : 4|1@1+ (1,0) [0|1] ""  HVESP01
 SG_ HVESP01_inhibitionDriveEntry_3 : 3|1@1+ (1,0) [0|1] ""  HVESP01
 SG_ HVESP01_inhibitionDrive_3 : 2|1@1+ (1,0) [0|1] ""  HVESP01
 SG_ HVESP01_inhibitionCharge_3 : 1|1@1+ (1,0) [0|1] ""  HVESP01
 SG_ HVESP01_inhibitionChargeEntry_3 : 0|1@1+ (1,0) [0|1] ""  HVESP01

BO_ 2499744872 HVESP01_Inhibitions_4: 8 HVESP01
 SG_ HVESP01_inhibitionPyroFuse_4 : 9|1@1+ (1,0) [0|1] ""  HVESP01
 SG_ HVESP01_inhibitionRegen_4 : 8|1@1+ (1,0) [0|1] ""  HVESP01
 SG_ HVESP01_inhibitionFullPower_4 : 7|1@1+ (1,0) [0|1] ""  HVESP01
 SG_ HVESP01_inhibitionRampDown_4 : 6|1@1+ (1,0) [0|1] ""  HVESP01
 SG_ HVESP01_inhibitionSupportEntry_4 : 5|1@1+ (1,0) [0|1] ""  HVESP01
 SG_ HVESP01_inhibitionSupport_4 : 4|1@1+ (1,0) [0|1] ""  HVESP01
 SG_ HVESP01_inhibitionDriveEntry_4 : 3|1@1+ (1,0) [0|1] ""  HVESP01
 SG_ HVESP01_inhibitionDrive_4 : 2|1@1+ (1,0) [0|1] ""  HVESP01
 SG_ HVESP01_inhibitionCharge_4 : 1|1@1+ (1,0) [0|1] ""  HVESP01
 SG_ HVESP01_inhibitionChargeEntry_4 : 0|1@1+ (1,0) [0|1] ""  HVESP01

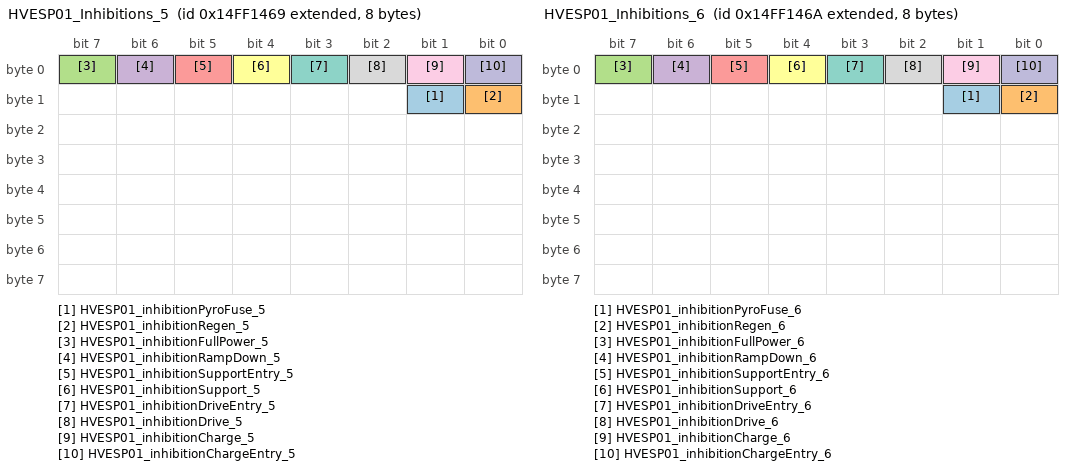
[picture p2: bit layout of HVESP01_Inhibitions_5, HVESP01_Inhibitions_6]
BO_ 2499744873 HVESP01_Inhibitions_5: 8 HVESP01
 SG_ HVESP01_inhibitionPyroFuse_5 : 9|1@1+ (1,0) [0|1] ""  HVESP01
 SG_ HVESP01_inhibitionRegen_5 : 8|1@1+ (1,0) [0|1] ""  HVESP01
 SG_ HVESP01_inhibitionFullPower_5 : 7|1@1+ (1,0) [0|1] ""  HVESP01
 SG_ HVESP01_inhibitionRampDown_5 : 6|1@1+ (1,0) [0|1] ""  HVESP01
 SG_ HVESP01_inhibitionSupportEntry_5 : 5|1@1+ (1,0) [0|1] ""  HVESP01
 SG_ HVESP01_inhibitionSupport_5 : 4|1@1+ (1,0) [0|1] ""  HVESP01
 SG_ HVESP01_inhibitionDriveEntry_5 : 3|1@1+ (1,0) [0|1] ""  HVESP01
 SG_ HVESP01_inhibitionDrive_5 : 2|1@1+ (1,0) [0|1] ""  HVESP01
 SG_ HVESP01_inhibitionCharge_5 : 1|1@1+ (1,0) [0|1] ""  HVESP01
 SG_ HVESP01_inhibitionChargeEntry_5 : 0|1@1+ (1,0) [0|1] ""  HVESP01

BO_ 2499744874 HVESP01_Inhibitions_6: 8 HVESP01
 SG_ HVESP01_inhibitionPyroFuse_6 : 9|1@1+ (1,0) [0|1] ""  HVESP01
 SG_ HVESP01_inhibitionRegen_6 : 8|1@1+ (1,0) [0|1] ""  HVESP01
 SG_ HVESP01_inhibitionFullPower_6 : 7|1@1+ (1,0) [0|1] ""  HVESP01
 SG_ HVESP01_inhibitionRampDown_6 : 6|1@1+ (1,0) [0|1] ""  HVESP01
 SG_ HVESP01_inhibitionSupportEntry_6 : 5|1@1+ (1,0) [0|1] ""  HVESP01
 SG_ HVESP01_inhibitionSupport_6 : 4|1@1+ (1,0) [0|1] ""  HVESP01
 SG_ HVESP01_inhibitionDriveEntry_6 : 3|1@1+ (1,0) [0|1] ""  HVESP01
 SG_ HVESP01_inhibitionDrive_6 : 2|1@1+ (1,0) [0|1] ""  HVESP01
 SG_ HVESP01_inhibitionCharge_6 : 1|1@1+ (1,0) [0|1] ""  HVESP01
 SG_ HVESP01_inhibitionChargeEntry_6 : 0|1@1+ (1,0) [0|1] ""  HVESP01

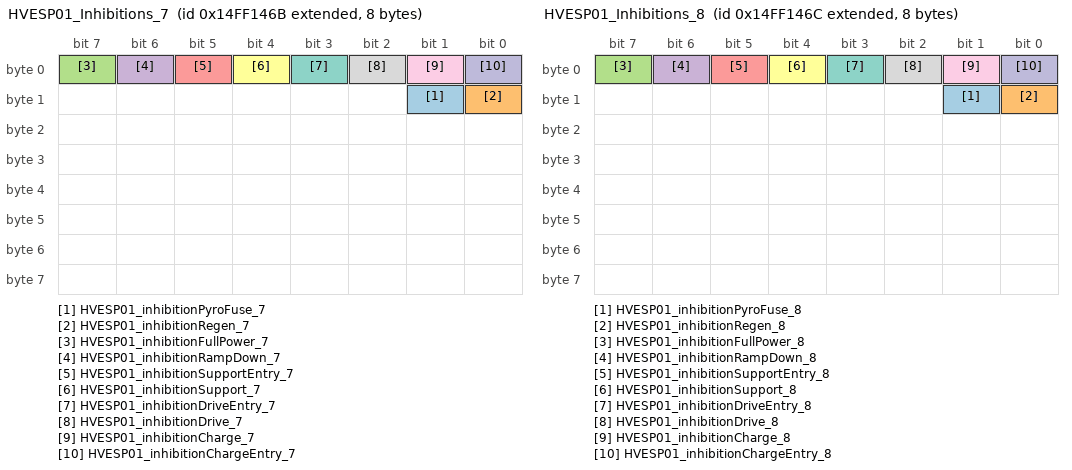
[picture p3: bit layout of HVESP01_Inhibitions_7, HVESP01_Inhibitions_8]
BO_ 2499744875 HVESP01_Inhibitions_7: 8 HVESP01
 SG_ HVESP01_inhibitionPyroFuse_7 : 9|1@1+ (1,0) [0|1] ""  HVESP01
 SG_ HVESP01_inhibitionRegen_7 : 8|1@1+ (1,0) [0|1] ""  HVESP01
 SG_ HVESP01_inhibitionFullPower_7 : 7|1@1+ (1,0) [0|1] ""  HVESP01
 SG_ HVESP01_inhibitionRampDown_7 : 6|1@1+ (1,0) [0|1] ""  HVESP01
 SG_ HVESP01_inhibitionSupportEntry_7 : 5|1@1+ (1,0) [0|1] ""  HVESP01
 SG_ HVESP01_inhibitionSupport_7 : 4|1@1+ (1,0) [0|1] ""  HVESP01
 SG_ HVESP01_inhibitionDriveEntry_7 : 3|1@1+ (1,0) [0|1] ""  HVESP01
 SG_ HVESP01_inhibitionDrive_7 : 2|1@1+ (1,0) [0|1] ""  HVESP01
 SG_ HVESP01_inhibitionCharge_7 : 1|1@1+ (1,0) [0|1] ""  HVESP01
 SG_ HVESP01_inhibitionChargeEntry_7 : 0|1@1+ (1,0) [0|1] ""  HVESP01

BO_ 2499744876 HVESP01_Inhibitions_8: 8 HVESP01
 SG_ HVESP01_inhibitionPyroFuse_8 : 9|1@1+ (1,0) [0|1] ""  HVESP01
 SG_ HVESP01_inhibitionRegen_8 : 8|1@1+ (1,0) [0|1] ""  HVESP01
 SG_ HVESP01_inhibitionFullPower_8 : 7|1@1+ (1,0) [0|1] ""  HVESP01
 SG_ HVESP01_inhibitionRampDown_8 : 6|1@1+ (1,0) [0|1] ""  HVESP01
 SG_ HVESP01_inhibitionSupportEntry_8 : 5|1@1+ (1,0) [0|1] ""  HVESP01
 SG_ HVESP01_inhibitionSupport_8 : 4|1@1+ (1,0) [0|1] ""  HVESP01
 SG_ HVESP01_inhibitionDriveEntry_8 : 3|1@1+ (1,0) [0|1] ""  HVESP01
 SG_ HVESP01_inhibitionDrive_8 : 2|1@1+ (1,0) [0|1] ""  HVESP01
 SG_ HVESP01_inhibitionCharge_8 : 1|1@1+ (1,0) [0|1] ""  HVESP01
 SG_ HVESP01_inhibitionChargeEntry_8 : 0|1@1+ (1,0) [0|1] ""  HVESP01

BO_ 2499745125 HVESP01_DiagnosticPrevA_1: 8 HVESP01
 SG_ HVESP01_vBrickOverSev_1 : 2|2@1+ (1,0) [0|3] ""  HVESP01
 SG_ HVESP01_vBrickOverMod_1 : 0|2@1+ (1,0) [0|3] ""  HVESP01
 SG_ HVESP01_vBrickOverWar_1 : 14|2@1+ (1,0) [0|3] ""  HVESP01
 SG_ HVESP01_HVESP01Quiet_1 : 12|2@1+ (1,0) [0|3] ""  HVESP01
 SG_ HVESP01_vBrickUnderMod_1 : 10|2@1+ (1,0) [0|3] ""  HVESP01
 SG_ HVESP01_vBrickUnderWar_1 : 8|2@1+ (1,0) [0|3] ""  HVESP01
 SG_ HVESP01_TempModuleOverSev_1 : 22|2@1+ (1,0) [0|3] ""  HVESP01
 SG_ HVESP01_TempModuleOverMod_1 : 20|2@1+ (1,0) [0|3] ""  HVESP01
 SG_ HVESP01_TempModuleOverWar_1 : 18|2@1+ (1,0) [0|3] ""  HVESP01
 SG_ HVESP01_TempModuleUnderSev_1 : 16|2@1+ (1,0) [0|3] ""  HVESP01
 SG_ HVESP01_TempModuleUnderMod_1 : 30|2@1+ (1,0) [0|3] ""  HVESP01
 SG_ HVESP01_TempModuleUnderWar_1 : 28|2@1+ (1,0) [0|3] ""  HVESP01
 SG_ HVESP01_iOvercharge_1 : 26|2@1+ (1,0) [0|3] ""  HVESP01
 SG_ HVESP01_iOverdischarge_1 : 24|2@1+ (1,0) [0|3] ""  HVESP01
 SG_ HVESP01_iOverHardware_1 : 38|2@1+ (1,0) [0|3] ""  HVESP01
 SG_ HVESP01_PosDcContStuckOpen_1 : 36|2@1+ (1,0) [0|3] ""  HVESP01
 SG_ HVESP01_PosDcContWelded_1 : 34|2@1+ (1,0) [0|3] ""  HVESP01
 SG_ HVESP01_NegDcContStuckOpen_1 : 32|2@1+ (1,0) [0|3] ""  HVESP01
 SG_ HVESP01_NegDcContWelded_1 : 46|2@1+ (1,0) [0|3] ""  HVESP01
 SG_ HVESP01_PrechgTooFast_1 : 44|2@1+ (1,0) [0|3] ""  HVESP01
 SG_ HVESP01_PrechgContWelded_1 : 42|2@1+ (1,0) [0|3] ""  HVESP01
 SG_ HVESP01_PrechgTimeout_1 : 40|2@1+ (1,0) [0|3] ""  HVESP01
 SG_ HVESP01_PrechgContStuckOpen_1 : 54|2@1+ (1,0) [0|3] ""  HVESP01
 SG_ HVESP01_ModuleImbalance_1 : 52|2@1+ (1,0) [0|3] ""  HVESP01
 SG_ HVESP01_ModuleMIA_1 : 50|2@1+ (1,0) [0|3] ""  HVESP01
 SG_ HVESP01_SensePackVoltError_1 : 48|2@1+ (1,0) [0|3] ""  HVESP01
 SG_ HVESP01_SenseLoadVoltError_1 : 62|2@1+ (1,0) [0|3] ""  HVESP01
 SG_ HVESP01_SenseShuntError_1 : 60|2@1+ (1,0) [0|3] ""  HVESP01
 SG_ HVESP01_SenseFcVoltErrorr_1 : 58|2@1+ (1,0) [0|3] ""  HVESP01
 SG_ HVESP01_Placeholder14_1 : 56|2@1+ (1,0) [0|3] ""  HVESP01

BO_ 2499745126 HVESP01_DiagnosticPrevA_2: 8 HVESP01
 SG_ HVESP01_vBrickOverSev_2 : 2|2@1+ (1,0) [0|3] ""  HVESP01
 SG_ HVESP01_vBrickOverMod_2 : 0|2@1+ (1,0) [0|3] ""  HVESP01
 SG_ HVESP01_vBrickOverWar_2 : 14|2@1+ (1,0) [0|3] ""  HVESP01
 SG_ HVESP01_HVESP01Quiet_2 : 12|2@1+ (1,0) [0|3] ""  HVESP01
 SG_ HVESP01_vBrickUnderMod_2 : 10|2@1+ (1,0) [0|3] ""  HVESP01
 SG_ HVESP01_vBrickUnderWar_2 : 8|2@1+ (1,0) [0|3] ""  HVESP01
 SG_ HVESP01_TempModuleOverSev_2 : 22|2@1+ (1,0) [0|3] ""  HVESP01
 SG_ HVESP01_TempModuleOverMod_2 : 20|2@1+ (1,0) [0|3] ""  HVESP01
 SG_ HVESP01_TempModuleOverWar_2 : 18|2@1+ (1,0) [0|3] ""  HVESP01
 SG_ HVESP01_TempModuleUnderSev_2 : 16|2@1+ (1,0) [0|3] ""  HVESP01
 SG_ HVESP01_TempModuleUnderMod_2 : 30|2@1+ (1,0) [0|3] ""  HVESP01
 SG_ HVESP01_TempModuleUnderWar_2 : 28|2@1+ (1,0) [0|3] ""  HVESP01
 SG_ HVESP01_iOvercharge_2 : 26|2@1+ (1,0) [0|3] ""  HVESP01
 SG_ HVESP01_iOverdischarge_2 : 24|2@1+ (1,0) [0|3] ""  HVESP01
 SG_ HVESP01_iOverHardware_2 : 38|2@1+ (1,0) [0|3] ""  HVESP01
 SG_ HVESP01_PosDcContStuckOpen_2 : 36|2@1+ (1,0) [0|3] ""  HVESP01
 SG_ HVESP01_PosDcContWelded_2 : 34|2@1+ (1,0) [0|3] ""  HVESP01
 SG_ HVESP01_NegDcContStuckOpen_2 : 32|2@1+ (1,0) [0|3] ""  HVESP01
 SG_ HVESP01_NegDcContWelded_2 : 46|2@1+ (1,0) [0|3] ""  HVESP01
 SG_ HVESP01_PrechgTooFast_2 : 44|2@1+ (1,0) [0|3] ""  HVESP01
 SG_ HVESP01_PrechgContWelded_2 : 42|2@1+ (1,0) [0|3] ""  HVESP01
 SG_ HVESP01_PrechgTimeout_2 : 40|2@1+ (1,0) [0|3] ""  HVESP01
 SG_ HVESP01_PrechgContStuckOpen_2 : 54|2@1+ (1,0) [0|3] ""  HVESP01
 SG_ HVESP01_ModuleImbalance_2 : 52|2@1+ (1,0) [0|3] ""  HVESP01
 SG_ HVESP01_ModuleMIA_2 : 50|2@1+ (1,0) [0|3] ""  HVESP01
 SG_ HVESP01_SensePackVoltError_2 : 48|2@1+ (1,0) [0|3] ""  HVESP01
 SG_ HVESP01_SenseLoadVoltError_2 : 62|2@1+ (1,0) [0|3] ""  HVESP01
 SG_ HVESP01_SenseShuntError_2 : 60|2@1+ (1,0) [0|3] ""  HVESP01
 SG_ HVESP01_SenseFcVoltErrorr_2 : 58|2@1+ (1,0) [0|3] ""  HVESP01
 SG_ HVESP01_Placeholder14_2 : 56|2@1+ (1,0) [0|3] ""  HVESP01

BO_ 2499745127 HVESP01_DiagnosticPrevA_3: 8 HVESP01
 SG_ HVESP01_vBrickOverSev_3 : 2|2@1+ (1,0) [0|3] ""  HVESP01
 SG_ HVESP01_vBrickOverMod_3 : 0|2@1+ (1,0) [0|3] ""  HVESP01
 SG_ HVESP01_vBrickOverWar_3 : 14|2@1+ (1,0) [0|3] ""  HVESP01
 SG_ HVESP01_HVESP01Quiet_3 : 12|2@1+ (1,0) [0|3] ""  HVESP01
 SG_ HVESP01_vBrickUnderMod_3 : 10|2@1+ (1,0) [0|3] ""  HVESP01
 SG_ HVESP01_vBrickUnderWar_3 : 8|2@1+ (1,0) [0|3] ""  HVESP01
 SG_ HVESP01_TempModuleOverSev_3 : 22|2@1+ (1,0) [0|3] ""  HVESP01
 SG_ HVESP01_TempModuleOverMod_3 : 20|2@1+ (1,0) [0|3] ""  HVESP01
 SG_ HVESP01_TempModuleOverWar_3 : 18|2@1+ (1,0) [0|3] ""  HVESP01
 SG_ HVESP01_TempModuleUnderSev_3 : 16|2@1+ (1,0) [0|3] ""  HVESP01
 SG_ HVESP01_TempModuleUnderMod_3 : 30|2@1+ (1,0) [0|3] ""  HVESP01
 SG_ HVESP01_TempModuleUnderWar_3 : 28|2@1+ (1,0) [0|3] ""  HVESP01
 SG_ HVESP01_iOvercharge_3 : 26|2@1+ (1,0) [0|3] ""  HVESP01
 SG_ HVESP01_iOverdischarge_3 : 24|2@1+ (1,0) [0|3] ""  HVESP01
 SG_ HVESP01_iOverHardware_3 : 38|2@1+ (1,0) [0|3] ""  HVESP01
 SG_ HVESP01_PosDcContStuckOpen_3 : 36|2@1+ (1,0) [0|3] ""  HVESP01
 SG_ HVESP01_PosDcContWelded_3 : 34|2@1+ (1,0) [0|3] ""  HVESP01
 SG_ HVESP01_NegDcContStuckOpen_3 : 32|2@1+ (1,0) [0|3] ""  HVESP01
 SG_ HVESP01_NegDcContWelded_3 : 46|2@1+ (1,0) [0|3] ""  HVESP01
 SG_ HVESP01_PrechgTooFast_3 : 44|2@1+ (1,0) [0|3] ""  HVESP01
 SG_ HVESP01_PrechgContWelded_3 : 42|2@1+ (1,0) [0|3] ""  HVESP01
 SG_ HVESP01_PrechgTimeout_3 : 40|2@1+ (1,0) [0|3] ""  HVESP01
 SG_ HVESP01_PrechgContStuckOpen_3 : 54|2@1+ (1,0) [0|3] ""  HVESP01
 SG_ HVESP01_ModuleImbalance_3 : 52|2@1+ (1,0) [0|3] ""  HVESP01
 SG_ HVESP01_ModuleMIA_3 : 50|2@1+ (1,0) [0|3] ""  HVESP01
 SG_ HVESP01_SensePackVoltError_3 : 48|2@1+ (1,0) [0|3] ""  HVESP01
 SG_ HVESP01_SenseLoadVoltError_3 : 62|2@1+ (1,0) [0|3] ""  HVESP01
 SG_ HVESP01_SenseShuntError_3 : 60|2@1+ (1,0) [0|3] ""  HVESP01
 SG_ HVESP01_SenseFcVoltErrorr_3 : 58|2@1+ (1,0) [0|3] ""  HVESP01
 SG_ HVESP01_Placeholder14_3 : 56|2@1+ (1,0) [0|3] ""  HVESP01

BO_ 2499745128 HVESP01_DiagnosticPrevA_4: 8 HVESP01
 SG_ HVESP01_vBrickOverSev_4 : 2|2@1+ (1,0) [0|3] ""  HVESP01
 SG_ HVESP01_vBrickOverMod_4 : 0|2@1+ (1,0) [0|3] ""  HVESP01
 SG_ HVESP01_vBrickOverWar_4 : 14|2@1+ (1,0) [0|3] ""  HVESP01
 SG_ HVESP01_HVESP01Quiet_4 : 12|2@1+ (1,0) [0|3] ""  HVESP01
 SG_ HVESP01_vBrickUnderMod_4 : 10|2@1+ (1,0) [0|3] ""  HVESP01
 SG_ HVESP01_vBrickUnderWar_4 : 8|2@1+ (1,0) [0|3] ""  HVESP01
 SG_ HVESP01_TempModuleOverSev_4 : 22|2@1+ (1,0) [0|3] ""  HVESP01
 SG_ HVESP01_TempModuleOverMod_4 : 20|2@1+ (1,0) [0|3] ""  HVESP01
 SG_ HVESP01_TempModuleOverWar_4 : 18|2@1+ (1,0) [0|3] ""  HVESP01
 SG_ HVESP01_TempModuleUnderSev_4 : 16|2@1+ (1,0) [0|3] ""  HVESP01
 SG_ HVESP01_TempModuleUnderMod_4 : 30|2@1+ (1,0) [0|3] ""  HVESP01
 SG_ HVESP01_TempModuleUnderWar_4 : 28|2@1+ (1,0) [0|3] ""  HVESP01
 SG_ HVESP01_iOvercharge_4 : 26|2@1+ (1,0) [0|3] ""  HVESP01
 SG_ HVESP01_iOverdischarge_4 : 24|2@1+ (1,0) [0|3] ""  HVESP01
 SG_ HVESP01_iOverHardware_4 : 38|2@1+ (1,0) [0|3] ""  HVESP01
 SG_ HVESP01_PosDcContStuckOpen_4 : 36|2@1+ (1,0) [0|3] ""  HVESP01
 SG_ HVESP01_PosDcContWelded_4 : 34|2@1+ (1,0) [0|3] ""  HVESP01
 SG_ HVESP01_NegDcContStuckOpen_4 : 32|2@1+ (1,0) [0|3] ""  HVESP01
 SG_ HVESP01_NegDcContWelded_4 : 46|2@1+ (1,0) [0|3] ""  HVESP01
 SG_ HVESP01_PrechgTooFast_4 : 44|2@1+ (1,0) [0|3] ""  HVESP01
 SG_ HVESP01_PrechgContWelded_4 : 42|2@1+ (1,0) [0|3] ""  HVESP01
 SG_ HVESP01_PrechgTimeout_4 : 40|2@1+ (1,0) [0|3] ""  HVESP01
 SG_ HVESP01_PrechgContStuckOpen_4 : 54|2@1+ (1,0) [0|3] ""  HVESP01
 SG_ HVESP01_ModuleImbalance_4 : 52|2@1+ (1,0) [0|3] ""  HVESP01
 SG_ HVESP01_ModuleMIA_4 : 50|2@1+ (1,0) [0|3] ""  HVESP01
 SG_ HVESP01_SensePackVoltError_4 : 48|2@1+ (1,0) [0|3] ""  HVESP01
 SG_ HVESP01_SenseLoadVoltError_4 : 62|2@1+ (1,0) [0|3] ""  HVESP01
 SG_ HVESP01_SenseShuntError_4 : 60|2@1+ (1,0) [0|3] ""  HVESP01
 SG_ HVESP01_SenseFcVoltErrorr_4 : 58|2@1+ (1,0) [0|3] ""  HVESP01
 SG_ HVESP01_Placeholder14_4 : 56|2@1+ (1,0) [0|3] ""  HVESP01

BO_ 2499745129 HVESP01_DiagnosticPrevA_5: 8 HVESP01
 SG_ HVESP01_vBrickOverSev_5 : 2|2@1+ (1,0) [0|3] ""  HVESP01
 SG_ HVESP01_vBrickOverMod_5 : 0|2@1+ (1,0) [0|3] ""  HVESP01
 SG_ HVESP01_vBrickOverWar_5 : 14|2@1+ (1,0) [0|3] ""  HVESP01
 SG_ HVESP01_HVESP01Quiet_5 : 12|2@1+ (1,0) [0|3] ""  HVESP01
 SG_ HVESP01_vBrickUnderMod_5 : 10|2@1+ (1,0) [0|3] ""  HVESP01
 SG_ HVESP01_vBrickUnderWar_5 : 8|2@1+ (1,0) [0|3] ""  HVESP01
 SG_ HVESP01_TempModuleOverSev_5 : 22|2@1+ (1,0) [0|3] ""  HVESP01
 SG_ HVESP01_TempModuleOverMod_5 : 20|2@1+ (1,0) [0|3] ""  HVESP01
 SG_ HVESP01_TempModuleOverWar_5 : 18|2@1+ (1,0) [0|3] ""  HVESP01
 SG_ HVESP01_TempModuleUnderSev_5 : 16|2@1+ (1,0) [0|3] ""  HVESP01
 SG_ HVESP01_TempModuleUnderMod_5 : 30|2@1+ (1,0) [0|3] ""  HVESP01
 SG_ HVESP01_TempModuleUnderWar_5 : 28|2@1+ (1,0) [0|3] ""  HVESP01
 SG_ HVESP01_iOvercharge_5 : 26|2@1+ (1,0) [0|3] ""  HVESP01
 SG_ HVESP01_iOverdischarge_5 : 24|2@1+ (1,0) [0|3] ""  HVESP01
 SG_ HVESP01_iOverHardware_5 : 38|2@1+ (1,0) [0|3] ""  HVESP01
 SG_ HVESP01_PosDcContStuckOpen_5 : 36|2@1+ (1,0) [0|3] ""  HVESP01
 SG_ HVESP01_PosDcContWelded_5 : 34|2@1+ (1,0) [0|3] ""  HVESP01
 SG_ HVESP01_NegDcContStuckOpen_5 : 32|2@1+ (1,0) [0|3] ""  HVESP01
 SG_ HVESP01_NegDcContWelded_5 : 46|2@1+ (1,0) [0|3] ""  HVESP01
 SG_ HVESP01_PrechgTooFast_5 : 44|2@1+ (1,0) [0|3] ""  HVESP01
 SG_ HVESP01_PrechgContWelded_5 : 42|2@1+ (1,0) [0|3] ""  HVESP01
 SG_ HVESP01_PrechgTimeout_5 : 40|2@1+ (1,0) [0|3] ""  HVESP01
 SG_ HVESP01_PrechgContStuckOpen_5 : 54|2@1+ (1,0) [0|3] ""  HVESP01
 SG_ HVESP01_ModuleImbalance_5 : 52|2@1+ (1,0) [0|3] ""  HVESP01
 SG_ HVESP01_ModuleMIA_5 : 50|2@1+ (1,0) [0|3] ""  HVESP01
 SG_ HVESP01_SensePackVoltError_5 : 48|2@1+ (1,0) [0|3] ""  HVESP01
 SG_ HVESP01_SenseLoadVoltError_5 : 62|2@1+ (1,0) [0|3] ""  HVESP01
 SG_ HVESP01_SenseShuntError_5 : 60|2@1+ (1,0) [0|3] ""  HVESP01
 SG_ HVESP01_SenseFcVoltErrorr_5 : 58|2@1+ (1,0) [0|3] ""  HVESP01
 SG_ HVESP01_Placeholder14_5 : 56|2@1+ (1,0) [0|3] ""  HVESP01

BO_ 2499745130 HVESP01_DiagnosticPrevA_6: 8 HVESP01
 SG_ HVESP01_vBrickOverSev_6 : 2|2@1+ (1,0) [0|3] ""  HVESP01
 SG_ HVESP01_vBrickOverMod_6 : 0|2@1+ (1,0) [0|3] ""  HVESP01
 SG_ HVESP01_vBrickOverWar_6 : 14|2@1+ (1,0) [0|3] ""  HVESP01
 SG_ HVESP01_HVESP01Quiet_6 : 12|2@1+ (1,0) [0|3] ""  HVESP01
 SG_ HVESP01_vBrickUnderMod_6 : 10|2@1+ (1,0) [0|3] ""  HVESP01
 SG_ HVESP01_vBrickUnderWar_6 : 8|2@1+ (1,0) [0|3] ""  HVESP01
 SG_ HVESP01_TempModuleOverSev_6 : 22|2@1+ (1,0) [0|3] ""  HVESP01
 SG_ HVESP01_TempModuleOverMod_6 : 20|2@1+ (1,0) [0|3] ""  HVESP01
 SG_ HVESP01_TempModuleOverWar_6 : 18|2@1+ (1,0) [0|3] ""  HVESP01
 SG_ HVESP01_TempModuleUnderSev_6 : 16|2@1+ (1,0) [0|3] ""  HVESP01
 SG_ HVESP01_TempModuleUnderMod_6 : 30|2@1+ (1,0) [0|3] ""  HVESP01
 SG_ HVESP01_TempModuleUnderWar_6 : 28|2@1+ (1,0) [0|3] ""  HVESP01
 SG_ HVESP01_iOvercharge_6 : 26|2@1+ (1,0) [0|3] ""  HVESP01
 SG_ HVESP01_iOverdischarge_6 : 24|2@1+ (1,0) [0|3] ""  HVESP01
 SG_ HVESP01_iOverHardware_6 : 38|2@1+ (1,0) [0|3] ""  HVESP01
 SG_ HVESP01_PosDcContStuckOpen_6 : 36|2@1+ (1,0) [0|3] ""  HVESP01
 SG_ HVESP01_PosDcContWelded_6 : 34|2@1+ (1,0) [0|3] ""  HVESP01
 SG_ HVESP01_NegDcContStuckOpen_6 : 32|2@1+ (1,0) [0|3] ""  HVESP01
 SG_ HVESP01_NegDcContWelded_6 : 46|2@1+ (1,0) [0|3] ""  HVESP01
 SG_ HVESP01_PrechgTooFast_6 : 44|2@1+ (1,0) [0|3] ""  HVESP01
 SG_ HVESP01_PrechgContWelded_6 : 42|2@1+ (1,0) [0|3] ""  HVESP01
 SG_ HVESP01_PrechgTimeout_6 : 40|2@1+ (1,0) [0|3] ""  HVESP01
 SG_ HVESP01_PrechgContStuckOpen_6 : 54|2@1+ (1,0) [0|3] ""  HVESP01
 SG_ HVESP01_ModuleImbalance_6 : 52|2@1+ (1,0) [0|3] ""  HVESP01
 SG_ HVESP01_ModuleMIA_6 : 50|2@1+ (1,0) [0|3] ""  HVESP01
 SG_ HVESP01_SensePackVoltError_6 : 48|2@1+ (1,0) [0|3] ""  HVESP01
 SG_ HVESP01_SenseLoadVoltError_6 : 62|2@1+ (1,0) [0|3] ""  HVESP01
 SG_ HVESP01_SenseShuntError_6 : 60|2@1+ (1,0) [0|3] ""  HVESP01
 SG_ HVESP01_SenseFcVoltErrorr_6 : 58|2@1+ (1,0) [0|3] ""  HVESP01
 SG_ HVESP01_Placeholder14_6 : 56|2@1+ (1,0) [0|3] ""  HVESP01

BO_ 2499745131 HVESP01_DiagnosticPrevA_7: 8 HVESP01
 SG_ HVESP01_vBrickOverSev_7 : 2|2@1+ (1,0) [0|3] ""  HVESP01
 SG_ HVESP01_vBrickOverMod_7 : 0|2@1+ (1,0) [0|3] ""  HVESP01
 SG_ HVESP01_vBrickOverWar_7 : 14|2@1+ (1,0) [0|3] ""  HVESP01
 SG_ HVESP01_HVESP01Quiet_7 : 12|2@1+ (1,0) [0|3] ""  HVESP01
 SG_ HVESP01_vBrickUnderMod_7 : 10|2@1+ (1,0) [0|3] ""  HVESP01
 SG_ HVESP01_vBrickUnderWar_7 : 8|2@1+ (1,0) [0|3] ""  HVESP01
 SG_ HVESP01_TempModuleOverSev_7 : 22|2@1+ (1,0) [0|3] ""  HVESP01
 SG_ HVESP01_TempModuleOverMod_7 : 20|2@1+ (1,0) [0|3] ""  HVESP01
 SG_ HVESP01_TempModuleOverWar_7 : 18|2@1+ (1,0) [0|3] ""  HVESP01
 SG_ HVESP01_TempModuleUnderSev_7 : 16|2@1+ (1,0) [0|3] ""  HVESP01
 SG_ HVESP01_TempModuleUnderMod_7 : 30|2@1+ (1,0) [0|3] ""  HVESP01
 SG_ HVESP01_TempModuleUnderWar_7 : 28|2@1+ (1,0) [0|3] ""  HVESP01
 SG_ HVESP01_iOvercharge_7 : 26|2@1+ (1,0) [0|3] ""  HVESP01
 SG_ HVESP01_iOverdischarge_7 : 24|2@1+ (1,0) [0|3] ""  HVESP01
 SG_ HVESP01_iOverHardware_7 : 38|2@1+ (1,0) [0|3] ""  HVESP01
 SG_ HVESP01_PosDcContStuckOpen_7 : 36|2@1+ (1,0) [0|3] ""  HVESP01
 SG_ HVESP01_PosDcContWelded_7 : 34|2@1+ (1,0) [0|3] ""  HVESP01
 SG_ HVESP01_NegDcContStuckOpen_7 : 32|2@1+ (1,0) [0|3] ""  HVESP01
 SG_ HVESP01_NegDcContWelded_7 : 46|2@1+ (1,0) [0|3] ""  HVESP01
 SG_ HVESP01_PrechgTooFast_7 : 44|2@1+ (1,0) [0|3] ""  HVESP01
 SG_ HVESP01_PrechgContWelded_7 : 42|2@1+ (1,0) [0|3] ""  HVESP01
 SG_ HVESP01_PrechgTimeout_7 : 40|2@1+ (1,0) [0|3] ""  HVESP01
 SG_ HVESP01_PrechgContStuckOpen_7 : 54|2@1+ (1,0) [0|3] ""  HVESP01
 SG_ HVESP01_ModuleImbalance_7 : 52|2@1+ (1,0) [0|3] ""  HVESP01
 SG_ HVESP01_ModuleMIA_7 : 50|2@1+ (1,0) [0|3] ""  HVESP01
 SG_ HVESP01_SensePackVoltError_7 : 48|2@1+ (1,0) [0|3] ""  HVESP01
 SG_ HVESP01_SenseLoadVoltError_7 : 62|2@1+ (1,0) [0|3] ""  HVESP01
 SG_ HVESP01_SenseShuntError_7 : 60|2@1+ (1,0) [0|3] ""  HVESP01
 SG_ HVESP01_SenseFcVoltErrorr_7 : 58|2@1+ (1,0) [0|3] ""  HVESP01
 SG_ HVESP01_Placeholder14_7 : 56|2@1+ (1,0) [0|3] ""  HVESP01

BO_ 2499745132 HVESP01_DiagnosticPrevA_8: 8 HVESP01
 SG_ HVESP01_vBrickOverSev_8 : 2|2@1+ (1,0) [0|3] ""  HVESP01
 SG_ HVESP01_vBrickOverMod_8 : 0|2@1+ (1,0) [0|3] ""  HVESP01
 SG_ HVESP01_vBrickOverWar_8 : 14|2@1+ (1,0) [0|3] ""  HVESP01
 SG_ HVESP01_HVESP01Quiet_8 : 12|2@1+ (1,0) [0|3] ""  HVESP01
 SG_ HVESP01_vBrickUnderMod_8 : 10|2@1+ (1,0) [0|3] ""  HVESP01
 SG_ HVESP01_vBrickUnderWar_8 : 8|2@1+ (1,0) [0|3] ""  HVESP01
 SG_ HVESP01_TempModuleOverSev_8 : 22|2@1+ (1,0) [0|3] ""  HVESP01
 SG_ HVESP01_TempModuleOverMod_8 : 20|2@1+ (1,0) [0|3] ""  HVESP01
 SG_ HVESP01_TempModuleOverWar_8 : 18|2@1+ (1,0) [0|3] ""  HVESP01
 SG_ HVESP01_TempModuleUnderSev_8 : 16|2@1+ (1,0) [0|3] ""  HVESP01
 SG_ HVESP01_TempModuleUnderMod_8 : 30|2@1+ (1,0) [0|3] ""  HVESP01
 SG_ HVESP01_TempModuleUnderWar_8 : 28|2@1+ (1,0) [0|3] ""  HVESP01
 SG_ HVESP01_iOvercharge_8 : 26|2@1+ (1,0) [0|3] ""  HVESP01
 SG_ HVESP01_iOverdischarge_8 : 24|2@1+ (1,0) [0|3] ""  HVESP01
 SG_ HVESP01_iOverHardware_8 : 38|2@1+ (1,0) [0|3] ""  HVESP01
 SG_ HVESP01_PosDcContStuckOpen_8 : 36|2@1+ (1,0) [0|3] ""  HVESP01
 SG_ HVESP01_PosDcContWelded_8 : 34|2@1+ (1,0) [0|3] ""  HVESP01
 SG_ HVESP01_NegDcContStuckOpen_8 : 32|2@1+ (1,0) [0|3] ""  HVESP01
 SG_ HVESP01_NegDcContWelded_8 : 46|2@1+ (1,0) [0|3] ""  HVESP01
 SG_ HVESP01_PrechgTooFast_8 : 44|2@1+ (1,0) [0|3] ""  HVESP01
 SG_ HVESP01_PrechgContWelded_8 : 42|2@1+ (1,0) [0|3] ""  HVESP01
 SG_ HVESP01_PrechgTimeout_8 : 40|2@1+ (1,0) [0|3] ""  HVESP01
 SG_ HVESP01_PrechgContStuckOpen_8 : 54|2@1+ (1,0) [0|3] ""  HVESP01
 SG_ HVESP01_ModuleImbalance_8 : 52|2@1+ (1,0) [0|3] ""  HVESP01
 SG_ HVESP01_ModuleMIA_8 : 50|2@1+ (1,0) [0|3] ""  HVESP01
 SG_ HVESP01_SensePackVoltError_8 : 48|2@1+ (1,0) [0|3] ""  HVESP01
 SG_ HVESP01_SenseLoadVoltError_8 : 62|2@1+ (1,0) [0|3] ""  HVESP01
 SG_ HVESP01_SenseShuntError_8 : 60|2@1+ (1,0) [0|3] ""  HVESP01
 SG_ HVESP01_SenseFcVoltErrorr_8 : 58|2@1+ (1,0) [0|3] ""  HVESP01
 SG_ HVESP01_Placeholder14_8 : 56|2@1+ (1,0) [0|3] ""  HVESP01

BO_ 2499745381 HVESP01_DiagnosticPrevB_1: 8 HVESP01
 SG_ HVESP01_SenseBrickImpHigh_1 : 2|2@1+ (1,0) [0|3] ""  HVESP01
 SG_ HVESP01_AFEfault_1 : 0|2@1+ (1,0) [0|3] ""  HVESP01
 SG_ HVESP01_AFEerror_1 : 14|2@1+ (1,0) [0|3] ""  HVESP01
 SG_ HVESP01_HVESP01MIA_1 : 12|2@1+ (1,0) [0|3] ""  HVESP01
 SG_ HVESP01_TempAmbientOverSev_1 : 10|2@1+ (1,0) [0|3] ""  HVESP01
 SG_ HVESP01_TempAmbientOverMod_1 : 8|2@1+ (1,0) [0|3] ""  HVESP01
 SG_ HVESP01_TempAmbientOverWar_1 : 22|2@1+ (1,0) [0|3] ""  HVESP01
 SG_ HVESP01_AbnormReset_1 : 20|2@1+ (1,0) [0|3] ""  HVESP01
 SG_ HVESP01_SenseAuxVoltError_1 : 18|2@1+ (1,0) [0|3] ""  HVESP01
 SG_ HVESP01_CalibrationInvalid_1 : 16|2@1+ (1,0) [0|3] ""  HVESP01
 SG_ HVESP01_TaskLockup_1 : 30|2@1+ (1,0) [0|3] ""  HVESP01
 SG_ HVESP01_RAMover_1 : 28|2@1+ (1,0) [0|3] ""  HVESP01
 SG_ HVESP01_BrickOverdischarge_1 : 26|2@1+ (1,0) [0|3] ""  HVESP01
 SG_ HVESP01_BrickOvercharge_1 : 24|2@1+ (1,0) [0|3] ""  HVESP01
 SG_ HVESP01_vBrickImbalancePer_1 : 38|2@1+ (1,0) [0|3] ""  HVESP01
 SG_ HVESP01_TempBrickImbalance_1 : 36|2@1+ (1,0) [0|3] ""  HVESP01
 SG_ HVESP01_CapPackLow_1 : 34|2@1+ (1,0) [0|3] ""  HVESP01
 SG_ HVESP01_rBrickHigh_1 : 32|2@1+ (1,0) [0|3] ""  HVESP01
 SG_ HVESP01_PowerpackInsuffErr_1 : 46|2@1+ (1,0) [0|3] ""  HVESP01
 SG_ HVESP01_BrickSoftShort_1 : 44|2@1+ (1,0) [0|3] ""  HVESP01
 SG_ HVESP01_chargeUndercurrent_1 : 42|2@1+ (1,0) [0|3] ""  HVESP01
 SG_ HVESP01_HVILcurrentSourceError_1 : 40|2@1+ (1,0) [0|3] ""  HVESP01
 SG_ HVESP01_SRS_1 : 54|2@1+ (1,0) [0|3] ""  HVESP01
 SG_ HVESP01_IsolationExtWar_1 : 52|2@1+ (1,0) [0|3] ""  HVESP01
 SG_ HVESP01_IsolationIntWar_1 : 50|2@1+ (1,0) [0|3] ""  HVESP01
 SG_ HVESP01_PyroFuseBlown_1 : 48|2@1+ (1,0) [0|3] ""  HVESP01
 SG_ HVESP01_vBrickUnderSev_1 : 62|2@1+ (1,0) [0|3] ""  HVESP01
 SG_ HVESP01_chargePrechargeTimeout_1 : 60|2@1+ (1,0) [0|3] ""  HVESP01
 SG_ HVESP01_ModuleThermFaultModerate_1 : 58|2@1+ (1,0) [0|3] ""  HVESP01
 SG_ HVESP01_ModuleThermFaultWarning_1 : 56|2@1+ (1,0) [0|3] ""  HVESP01

BO_ 2499745382 HVESP01_DiagnosticPrevB_2: 8 HVESP01
 SG_ HVESP01_SenseBrickImpHigh_2 : 2|2@1+ (1,0) [0|3] ""  HVESP01
 SG_ HVESP01_AFEfault_2 : 0|2@1+ (1,0) [0|3] ""  HVESP01
 SG_ HVESP01_AFEerror_2 : 14|2@1+ (1,0) [0|3] ""  HVESP01
 SG_ HVESP01_HVESP01MIA_2 : 12|2@1+ (1,0) [0|3] ""  HVESP01
 SG_ HVESP01_TempAmbientOverSev_2 : 10|2@1+ (1,0) [0|3] ""  HVESP01
 SG_ HVESP01_TempAmbientOverMod_2 : 8|2@1+ (1,0) [0|3] ""  HVESP01
 SG_ HVESP01_TempAmbientOverWar_2 : 22|2@1+ (1,0) [0|3] ""  HVESP01
 SG_ HVESP01_AbnormReset_2 : 20|2@1+ (1,0) [0|3] ""  HVESP01
 SG_ HVESP01_SenseAuxVoltError_2 : 18|2@1+ (1,0) [0|3] ""  HVESP01
 SG_ HVESP01_CalibrationInvalid_2 : 16|2@1+ (1,0) [0|3] ""  HVESP01
 SG_ HVESP01_TaskLockup_2 : 30|2@1+ (1,0) [0|3] ""  HVESP01
 SG_ HVESP01_RAMover_2 : 28|2@1+ (1,0) [0|3] ""  HVESP01
 SG_ HVESP01_BrickOverdischarge_2 : 26|2@1+ (1,0) [0|3] ""  HVESP01
 SG_ HVESP01_BrickOvercharge_2 : 24|2@1+ (1,0) [0|3] ""  HVESP01
 SG_ HVESP01_vBrickImbalancePer_2 : 38|2@1+ (1,0) [0|3] ""  HVESP01
 SG_ HVESP01_TempBrickImbalance_2 : 36|2@1+ (1,0) [0|3] ""  HVESP01
 SG_ HVESP01_CapPackLow_2 : 34|2@1+ (1,0) [0|3] ""  HVESP01
 SG_ HVESP01_rBrickHigh_2 : 32|2@1+ (1,0) [0|3] ""  HVESP01
 SG_ HVESP01_PowerpackInsuffErr_2 : 46|2@1+ (1,0) [0|3] ""  HVESP01
 SG_ HVESP01_BrickSoftShort_2 : 44|2@1+ (1,0) [0|3] ""  HVESP01
 SG_ HVESP01_chargeUndercurrent_2 : 42|2@1+ (1,0) [0|3] ""  HVESP01
 SG_ HVESP01_HVILcurrentSourceError_2 : 40|2@1+ (1,0) [0|3] ""  HVESP01
 SG_ HVESP01_SRS_2 : 54|2@1+ (1,0) [0|3] ""  HVESP01
 SG_ HVESP01_IsolationExtWar_2 : 52|2@1+ (1,0) [0|3] ""  HVESP01
 SG_ HVESP01_IsolationIntWar_2 : 50|2@1+ (1,0) [0|3] ""  HVESP01
 SG_ HVESP01_PyroFuseBlown_2 : 48|2@1+ (1,0) [0|3] ""  HVESP01
 SG_ HVESP01_vBrickUnderSev_2 : 62|2@1+ (1,0) [0|3] ""  HVESP01
 SG_ HVESP01_chargePrechargeTimeout_2 : 60|2@1+ (1,0) [0|3] ""  HVESP01
 SG_ HVESP01_ModuleThermFaultModerate_2 : 58|2@1+ (1,0) [0|3] ""  HVESP01
 SG_ HVESP01_ModuleThermFaultWarning_2 : 56|2@1+ (1,0) [0|3] ""  HVESP01

BO_ 2499745383 HVESP01_DiagnosticPrevB_3: 8 HVESP01
 SG_ HVESP01_SenseBrickImpHigh_3 : 2|2@1+ (1,0) [0|3] ""  HVESP01
 SG_ HVESP01_AFEfault_3 : 0|2@1+ (1,0) [0|3] ""  HVESP01
 SG_ HVESP01_AFEerror_3 : 14|2@1+ (1,0) [0|3] ""  HVESP01
 SG_ HVESP01_HVESP01MIA_3 : 12|2@1+ (1,0) [0|3] ""  HVESP01
 SG_ HVESP01_TempAmbientOverSev_3 : 10|2@1+ (1,0) [0|3] ""  HVESP01
 SG_ HVESP01_TempAmbientOverMod_3 : 8|2@1+ (1,0) [0|3] ""  HVESP01
 SG_ HVESP01_TempAmbientOverWar_3 : 22|2@1+ (1,0) [0|3] ""  HVESP01
 SG_ HVESP01_AbnormReset_3 : 20|2@1+ (1,0) [0|3] ""  HVESP01
 SG_ HVESP01_SenseAuxVoltError_3 : 18|2@1+ (1,0) [0|3] ""  HVESP01
 SG_ HVESP01_CalibrationInvalid_3 : 16|2@1+ (1,0) [0|3] ""  HVESP01
 SG_ HVESP01_TaskLockup_3 : 30|2@1+ (1,0) [0|3] ""  HVESP01
 SG_ HVESP01_RAMover_3 : 28|2@1+ (1,0) [0|3] ""  HVESP01
 SG_ HVESP01_BrickOverdischarge_3 : 26|2@1+ (1,0) [0|3] ""  HVESP01
 SG_ HVESP01_BrickOvercharge_3 : 24|2@1+ (1,0) [0|3] ""  HVESP01
 SG_ HVESP01_vBrickImbalancePer_3 : 38|2@1+ (1,0) [0|3] ""  HVESP01
 SG_ HVESP01_TempBrickImbalance_3 : 36|2@1+ (1,0) [0|3] ""  HVESP01
 SG_ HVESP01_CapPackLow_3 : 34|2@1+ (1,0) [0|3] ""  HVESP01
 SG_ HVESP01_rBrickHigh_3 : 32|2@1+ (1,0) [0|3] ""  HVESP01
 SG_ HVESP01_PowerpackInsuffErr_3 : 46|2@1+ (1,0) [0|3] ""  HVESP01
 SG_ HVESP01_BrickSoftShort_3 : 44|2@1+ (1,0) [0|3] ""  HVESP01
 SG_ HVESP01_chargeUndercurrent_3 : 42|2@1+ (1,0) [0|3] ""  HVESP01
 SG_ HVESP01_HVILcurrentSourceError_3 : 40|2@1+ (1,0) [0|3] ""  HVESP01
 SG_ HVESP01_SRS_3 : 54|2@1+ (1,0) [0|3] ""  HVESP01
 SG_ HVESP01_IsolationExtWar_3 : 52|2@1+ (1,0) [0|3] ""  HVESP01
 SG_ HVESP01_IsolationIntWar_3 : 50|2@1+ (1,0) [0|3] ""  HVESP01
 SG_ HVESP01_PyroFuseBlown_3 : 48|2@1+ (1,0) [0|3] ""  HVESP01
 SG_ HVESP01_vBrickUnderSev_3 : 62|2@1+ (1,0) [0|3] ""  HVESP01
 SG_ HVESP01_chargePrechargeTimeout_3 : 60|2@1+ (1,0) [0|3] ""  HVESP01
 SG_ HVESP01_ModuleThermFaultModerate_3 : 58|2@1+ (1,0) [0|3] ""  HVESP01
 SG_ HVESP01_ModuleThermFaultWarning_3 : 56|2@1+ (1,0) [0|3] ""  HVESP01

BO_ 2499745384 HVESP01_DiagnosticPrevB_4: 8 HVESP01
 SG_ HVESP01_SenseBrickImpHigh_4 : 2|2@1+ (1,0) [0|3] ""  HVESP01
 SG_ HVESP01_AFEfault_4 : 0|2@1+ (1,0) [0|3] ""  HVESP01
 SG_ HVESP01_AFEerror_4 : 14|2@1+ (1,0) [0|3] ""  HVESP01
 SG_ HVESP01_HVESP01MIA_4 : 12|2@1+ (1,0) [0|3] ""  HVESP01
 SG_ HVESP01_TempAmbientOverSev_4 : 10|2@1+ (1,0) [0|3] ""  HVESP01
 SG_ HVESP01_TempAmbientOverMod_4 : 8|2@1+ (1,0) [0|3] ""  HVESP01
 SG_ HVESP01_TempAmbientOverWar_4 : 22|2@1+ (1,0) [0|3] ""  HVESP01
 SG_ HVESP01_AbnormReset_4 : 20|2@1+ (1,0) [0|3] ""  HVESP01
 SG_ HVESP01_SenseAuxVoltError_4 : 18|2@1+ (1,0) [0|3] ""  HVESP01
 SG_ HVESP01_CalibrationInvalid_4 : 16|2@1+ (1,0) [0|3] ""  HVESP01
 SG_ HVESP01_TaskLockup_4 : 30|2@1+ (1,0) [0|3] ""  HVESP01
 SG_ HVESP01_RAMover_4 : 28|2@1+ (1,0) [0|3] ""  HVESP01
 SG_ HVESP01_BrickOverdischarge_4 : 26|2@1+ (1,0) [0|3] ""  HVESP01
 SG_ HVESP01_BrickOvercharge_4 : 24|2@1+ (1,0) [0|3] ""  HVESP01
 SG_ HVESP01_vBrickImbalancePer_4 : 38|2@1+ (1,0) [0|3] ""  HVESP01
 SG_ HVESP01_TempBrickImbalance_4 : 36|2@1+ (1,0) [0|3] ""  HVESP01
 SG_ HVESP01_CapPackLow_4 : 34|2@1+ (1,0) [0|3] ""  HVESP01
 SG_ HVESP01_rBrickHigh_4 : 32|2@1+ (1,0) [0|3] ""  HVESP01
 SG_ HVESP01_PowerpackInsuffErr_4 : 46|2@1+ (1,0) [0|3] ""  HVESP01
 SG_ HVESP01_BrickSoftShort_4 : 44|2@1+ (1,0) [0|3] ""  HVESP01
 SG_ HVESP01_chargeUndercurrent_4 : 42|2@1+ (1,0) [0|3] ""  HVESP01
 SG_ HVESP01_HVILcurrentSourceError_4 : 40|2@1+ (1,0) [0|3] ""  HVESP01
 SG_ HVESP01_SRS_4 : 54|2@1+ (1,0) [0|3] ""  HVESP01
 SG_ HVESP01_IsolationExtWar_4 : 52|2@1+ (1,0) [0|3] ""  HVESP01
 SG_ HVESP01_IsolationIntWar_4 : 50|2@1+ (1,0) [0|3] ""  HVESP01
 SG_ HVESP01_PyroFuseBlown_4 : 48|2@1+ (1,0) [0|3] ""  HVESP01
 SG_ HVESP01_vBrickUnderSev_4 : 62|2@1+ (1,0) [0|3] ""  HVESP01
 SG_ HVESP01_chargePrechargeTimeout_4 : 60|2@1+ (1,0) [0|3] ""  HVESP01
 SG_ HVESP01_ModuleThermFaultModerate_4 : 58|2@1+ (1,0) [0|3] ""  HVESP01
 SG_ HVESP01_ModuleThermFaultWarning_4 : 56|2@1+ (1,0) [0|3] ""  HVESP01

BO_ 2499745385 HVESP01_DiagnosticPrevB_5: 8 HVESP01
 SG_ HVESP01_SenseBrickImpHigh_5 : 2|2@1+ (1,0) [0|3] ""  HVESP01
 SG_ HVESP01_AFEfault_5 : 0|2@1+ (1,0) [0|3] ""  HVESP01
 SG_ HVESP01_AFEerror_5 : 14|2@1+ (1,0) [0|3] ""  HVESP01
 SG_ HVESP01_HVESP01MIA_5 : 12|2@1+ (1,0) [0|3] ""  HVESP01
 SG_ HVESP01_TempAmbientOverSev_5 : 10|2@1+ (1,0) [0|3] ""  HVESP01
 SG_ HVESP01_TempAmbientOverMod_5 : 8|2@1+ (1,0) [0|3] ""  HVESP01
 SG_ HVESP01_TempAmbientOverWar_5 : 22|2@1+ (1,0) [0|3] ""  HVESP01
 SG_ HVESP01_AbnormReset_5 : 20|2@1+ (1,0) [0|3] ""  HVESP01
 SG_ HVESP01_SenseAuxVoltError_5 : 18|2@1+ (1,0) [0|3] ""  HVESP01
 SG_ HVESP01_CalibrationInvalid_5 : 16|2@1+ (1,0) [0|3] ""  HVESP01
 SG_ HVESP01_TaskLockup_5 : 30|2@1+ (1,0) [0|3] ""  HVESP01
 SG_ HVESP01_RAMover_5 : 28|2@1+ (1,0) [0|3] ""  HVESP01
 SG_ HVESP01_BrickOverdischarge_5 : 26|2@1+ (1,0) [0|3] ""  HVESP01
 SG_ HVESP01_BrickOvercharge_5 : 24|2@1+ (1,0) [0|3] ""  HVESP01
 SG_ HVESP01_vBrickImbalancePer_5 : 38|2@1+ (1,0) [0|3] ""  HVESP01
 SG_ HVESP01_TempBrickImbalance_5 : 36|2@1+ (1,0) [0|3] ""  HVESP01
 SG_ HVESP01_CapPackLow_5 : 34|2@1+ (1,0) [0|3] ""  HVESP01
 SG_ HVESP01_rBrickHigh_5 : 32|2@1+ (1,0) [0|3] ""  HVESP01
 SG_ HVESP01_PowerpackInsuffErr_5 : 46|2@1+ (1,0) [0|3] ""  HVESP01
 SG_ HVESP01_BrickSoftShort_5 : 44|2@1+ (1,0) [0|3] ""  HVESP01
 SG_ HVESP01_chargeUndercurrent_5 : 42|2@1+ (1,0) [0|3] ""  HVESP01
 SG_ HVESP01_HVILcurrentSourceError_5 : 40|2@1+ (1,0) [0|3] ""  HVESP01
 SG_ HVESP01_SRS_5 : 54|2@1+ (1,0) [0|3] ""  HVESP01
 SG_ HVESP01_IsolationExtWar_5 : 52|2@1+ (1,0) [0|3] ""  HVESP01
 SG_ HVESP01_IsolationIntWar_5 : 50|2@1+ (1,0) [0|3] ""  HVESP01
 SG_ HVESP01_PyroFuseBlown_5 : 48|2@1+ (1,0) [0|3] ""  HVESP01
 SG_ HVESP01_vBrickUnderSev_5 : 62|2@1+ (1,0) [0|3] ""  HVESP01
 SG_ HVESP01_chargePrechargeTimeout_5 : 60|2@1+ (1,0) [0|3] ""  HVESP01
 SG_ HVESP01_ModuleThermFaultModerate_5 : 58|2@1+ (1,0) [0|3] ""  HVESP01
 SG_ HVESP01_ModuleThermFaultWarning_5 : 56|2@1+ (1,0) [0|3] ""  HVESP01

BO_ 2499745386 HVESP01_DiagnosticPrevB_6: 8 HVESP01
 SG_ HVESP01_SenseBrickImpHigh_6 : 2|2@1+ (1,0) [0|3] ""  HVESP01
 SG_ HVESP01_AFEfault_6 : 0|2@1+ (1,0) [0|3] ""  HVESP01
 SG_ HVESP01_AFEerror_6 : 14|2@1+ (1,0) [0|3] ""  HVESP01
 SG_ HVESP01_HVESP01MIA_6 : 12|2@1+ (1,0) [0|3] ""  HVESP01
 SG_ HVESP01_TempAmbientOverSev_6 : 10|2@1+ (1,0) [0|3] ""  HVESP01
 SG_ HVESP01_TempAmbientOverMod_6 : 8|2@1+ (1,0) [0|3] ""  HVESP01
 SG_ HVESP01_TempAmbientOverWar_6 : 22|2@1+ (1,0) [0|3] ""  HVESP01
 SG_ HVESP01_AbnormReset_6 : 20|2@1+ (1,0) [0|3] ""  HVESP01
 SG_ HVESP01_SenseAuxVoltError_6 : 18|2@1+ (1,0) [0|3] ""  HVESP01
 SG_ HVESP01_CalibrationInvalid_6 : 16|2@1+ (1,0) [0|3] ""  HVESP01
 SG_ HVESP01_TaskLockup_6 : 30|2@1+ (1,0) [0|3] ""  HVESP01
 SG_ HVESP01_RAMover_6 : 28|2@1+ (1,0) [0|3] ""  HVESP01
 SG_ HVESP01_BrickOverdischarge_6 : 26|2@1+ (1,0) [0|3] ""  HVESP01
 SG_ HVESP01_BrickOvercharge_6 : 24|2@1+ (1,0) [0|3] ""  HVESP01
 SG_ HVESP01_vBrickImbalancePer_6 : 38|2@1+ (1,0) [0|3] ""  HVESP01
 SG_ HVESP01_TempBrickImbalance_6 : 36|2@1+ (1,0) [0|3] ""  HVESP01
 SG_ HVESP01_CapPackLow_6 : 34|2@1+ (1,0) [0|3] ""  HVESP01
 SG_ HVESP01_rBrickHigh_6 : 32|2@1+ (1,0) [0|3] ""  HVESP01
 SG_ HVESP01_PowerpackInsuffErr_6 : 46|2@1+ (1,0) [0|3] ""  HVESP01
 SG_ HVESP01_BrickSoftShort_6 : 44|2@1+ (1,0) [0|3] ""  HVESP01
 SG_ HVESP01_chargeUndercurrent_6 : 42|2@1+ (1,0) [0|3] ""  HVESP01
 SG_ HVESP01_HVILcurrentSourceError_6 : 40|2@1+ (1,0) [0|3] ""  HVESP01
 SG_ HVESP01_SRS_6 : 54|2@1+ (1,0) [0|3] ""  HVESP01
 SG_ HVESP01_IsolationExtWar_6 : 52|2@1+ (1,0) [0|3] ""  HVESP01
 SG_ HVESP01_IsolationIntWar_6 : 50|2@1+ (1,0) [0|3] ""  HVESP01
 SG_ HVESP01_PyroFuseBlown_6 : 48|2@1+ (1,0) [0|3] ""  HVESP01
 SG_ HVESP01_vBrickUnderSev_6 : 62|2@1+ (1,0) [0|3] ""  HVESP01
 SG_ HVESP01_chargePrechargeTimeout_6 : 60|2@1+ (1,0) [0|3] ""  HVESP01
 SG_ HVESP01_ModuleThermFaultModerate_6 : 58|2@1+ (1,0) [0|3] ""  HVESP01
 SG_ HVESP01_ModuleThermFaultWarning_6 : 56|2@1+ (1,0) [0|3] ""  HVESP01

BO_ 2499745387 HVESP01_DiagnosticPrevB_7: 8 HVESP01
 SG_ HVESP01_SenseBrickImpHigh_7 : 2|2@1+ (1,0) [0|3] ""  HVESP01
 SG_ HVESP01_AFEfault_7 : 0|2@1+ (1,0) [0|3] ""  HVESP01
 SG_ HVESP01_AFEerror_7 : 14|2@1+ (1,0) [0|3] ""  HVESP01
 SG_ HVESP01_HVESP01MIA_7 : 12|2@1+ (1,0) [0|3] ""  HVESP01
 SG_ HVESP01_TempAmbientOverSev_7 : 10|2@1+ (1,0) [0|3] ""  HVESP01
 SG_ HVESP01_TempAmbientOverMod_7 : 8|2@1+ (1,0) [0|3] ""  HVESP01
 SG_ HVESP01_TempAmbientOverWar_7 : 22|2@1+ (1,0) [0|3] ""  HVESP01
 SG_ HVESP01_AbnormReset_7 : 20|2@1+ (1,0) [0|3] ""  HVESP01
 SG_ HVESP01_SenseAuxVoltError_7 : 18|2@1+ (1,0) [0|3] ""  HVESP01
 SG_ HVESP01_CalibrationInvalid_7 : 16|2@1+ (1,0) [0|3] ""  HVESP01
 SG_ HVESP01_TaskLockup_7 : 30|2@1+ (1,0) [0|3] ""  HVESP01
 SG_ HVESP01_RAMover_7 : 28|2@1+ (1,0) [0|3] ""  HVESP01
 SG_ HVESP01_BrickOverdischarge_7 : 26|2@1+ (1,0) [0|3] ""  HVESP01
 SG_ HVESP01_BrickOvercharge_7 : 24|2@1+ (1,0) [0|3] ""  HVESP01
 SG_ HVESP01_vBrickImbalancePer_7 : 38|2@1+ (1,0) [0|3] ""  HVESP01
 SG_ HVESP01_TempBrickImbalance_7 : 36|2@1+ (1,0) [0|3] ""  HVESP01
 SG_ HVESP01_CapPackLow_7 : 34|2@1+ (1,0) [0|3] ""  HVESP01
 SG_ HVESP01_rBrickHigh_7 : 32|2@1+ (1,0) [0|3] ""  HVESP01
 SG_ HVESP01_PowerpackInsuffErr_7 : 46|2@1+ (1,0) [0|3] ""  HVESP01
 SG_ HVESP01_BrickSoftShort_7 : 44|2@1+ (1,0) [0|3] ""  HVESP01
 SG_ HVESP01_chargeUndercurrent_7 : 42|2@1+ (1,0) [0|3] ""  HVESP01
 SG_ HVESP01_HVILcurrentSourceError_7 : 40|2@1+ (1,0) [0|3] ""  HVESP01
 SG_ HVESP01_SRS_7 : 54|2@1+ (1,0) [0|3] ""  HVESP01
 SG_ HVESP01_IsolationExtWar_7 : 52|2@1+ (1,0) [0|3] ""  HVESP01
 SG_ HVESP01_IsolationIntWar_7 : 50|2@1+ (1,0) [0|3] ""  HVESP01
 SG_ HVESP01_PyroFuseBlown_7 : 48|2@1+ (1,0) [0|3] ""  HVESP01
 SG_ HVESP01_vBrickUnderSev_7 : 62|2@1+ (1,0) [0|3] ""  HVESP01
 SG_ HVESP01_chargePrechargeTimeout_7 : 60|2@1+ (1,0) [0|3] ""  HVESP01
 SG_ HVESP01_ModuleThermFaultModerate_7 : 58|2@1+ (1,0) [0|3] ""  HVESP01
 SG_ HVESP01_ModuleThermFaultWarning_7 : 56|2@1+ (1,0) [0|3] ""  HVESP01

BO_ 2499745388 HVESP01_DiagnosticPrevB_8: 8 HVESP01
 SG_ HVESP01_SenseBrickImpHigh_8 : 2|2@1+ (1,0) [0|3] ""  HVESP01
 SG_ HVESP01_AFEfault_8 : 0|2@1+ (1,0) [0|3] ""  HVESP01
 SG_ HVESP01_AFEerror_8 : 14|2@1+ (1,0) [0|3] ""  HVESP01
 SG_ HVESP01_HVESP01MIA_8 : 12|2@1+ (1,0) [0|3] ""  HVESP01
 SG_ HVESP01_TempAmbientOverSev_8 : 10|2@1+ (1,0) [0|3] ""  HVESP01
 SG_ HVESP01_TempAmbientOverMod_8 : 8|2@1+ (1,0) [0|3] ""  HVESP01
 SG_ HVESP01_TempAmbientOverWar_8 : 22|2@1+ (1,0) [0|3] ""  HVESP01
 SG_ HVESP01_AbnormReset_8 : 20|2@1+ (1,0) [0|3] ""  HVESP01
 SG_ HVESP01_SenseAuxVoltError_8 : 18|2@1+ (1,0) [0|3] ""  HVESP01
 SG_ HVESP01_CalibrationInvalid_8 : 16|2@1+ (1,0) [0|3] ""  HVESP01
 SG_ HVESP01_TaskLockup_8 : 30|2@1+ (1,0) [0|3] ""  HVESP01
 SG_ HVESP01_RAMover_8 : 28|2@1+ (1,0) [0|3] ""  HVESP01
 SG_ HVESP01_BrickOverdischarge_8 : 26|2@1+ (1,0) [0|3] ""  HVESP01
 SG_ HVESP01_BrickOvercharge_8 : 24|2@1+ (1,0) [0|3] ""  HVESP01
 SG_ HVESP01_vBrickImbalancePer_8 : 38|2@1+ (1,0) [0|3] ""  HVESP01
 SG_ HVESP01_TempBrickImbalance_8 : 36|2@1+ (1,0) [0|3] ""  HVESP01
 SG_ HVESP01_CapPackLow_8 : 34|2@1+ (1,0) [0|3] ""  HVESP01
 SG_ HVESP01_rBrickHigh_8 : 32|2@1+ (1,0) [0|3] ""  HVESP01
 SG_ HVESP01_PowerpackInsuffErr_8 : 46|2@1+ (1,0) [0|3] ""  HVESP01
 SG_ HVESP01_BrickSoftShort_8 : 44|2@1+ (1,0) [0|3] ""  HVESP01
 SG_ HVESP01_chargeUndercurrent_8 : 42|2@1+ (1,0) [0|3] ""  HVESP01
 SG_ HVESP01_HVILcurrentSourceError_8 : 40|2@1+ (1,0) [0|3] ""  HVESP01
 SG_ HVESP01_SRS_8 : 54|2@1+ (1,0) [0|3] ""  HVESP01
 SG_ HVESP01_IsolationExtWar_8 : 52|2@1+ (1,0) [0|3] ""  HVESP01
 SG_ HVESP01_IsolationIntWar_8 : 50|2@1+ (1,0) [0|3] ""  HVESP01
 SG_ HVESP01_PyroFuseBlown_8 : 48|2@1+ (1,0) [0|3] ""  HVESP01
 SG_ HVESP01_vBrickUnderSev_8 : 62|2@1+ (1,0) [0|3] ""  HVESP01
 SG_ HVESP01_chargePrechargeTimeout_8 : 60|2@1+ (1,0) [0|3] ""  HVESP01
 SG_ HVESP01_ModuleThermFaultModerate_8 : 58|2@1+ (1,0) [0|3] ""  HVESP01
 SG_ HVESP01_ModuleThermFaultWarning_8 : 56|2@1+ (1,0) [0|3] ""  HVESP01

BO_ 2499745637 HVESP01_DiagnosticPrevC_1: 8 HVESP01
 SG_ HVESP01_PackVoltageImbalance_1 : 58|2@1+ (1,0) [0|3] ""  HVESP01
 SG_ HVESP01_PrechargeoverCurrent_1 : 56|2@1+ (1,0) [0|3] ""  HVESP01
 SG_ HVESP01_HVILvoltageError_1 : 2|2@1+ (1,0) [0|3] ""  HVESP01
 SG_ HVESP01_HVILcurrentReturnError_1 : 0|2@1+ (1,0) [0|3] ""  HVESP01
 SG_ HVESP01_PosFcContWelded_1 : 14|2@1+ (1,0) [0|3] ""  HVESP01
 SG_ HVESP01_PosContStuckOpen_2_1 : 12|2@1+ (1,0) [0|3] ""  HVESP01
 SG_ HVESP01_NegContWelded_2_1 : 10|2@1+ (1,0) [0|3] ""  HVESP01
 SG_ HVESP01_NegFcContStuckOpen_1 : 8|2@1+ (1,0) [0|3] ""  HVESP01
 SG_ HVESP01_IsospiBreak_1 : 22|2@1+ (1,0) [0|3] ""  HVESP01
 SG_ HVESP01_IsolationIntFault_1 : 20|2@1+ (1,0) [0|3] ""  HVESP01
 SG_ HVESP01_IsolationExtFault_1 : 18|2@1+ (1,0) [0|3] ""  HVESP01
 SG_ HVESP01_12v_filter_error_1 : 16|2@1+ (1,0) [0|3] ""  HVESP01
 SG_ HVESP01_hall_eff_hi_rang_err_1 : 30|2@1+ (1,0) [0|3] ""  HVESP01
 SG_ HVESP01_brick_volt_sns_open_1 : 28|2@1+ (1,0) [0|3] ""  HVESP01
 SG_ HVESP01_5v_error_1 : 26|2@1+ (1,0) [0|3] ""  HVESP01
 SG_ HVESP01_3_3_hot_error_1 : 24|2@1+ (1,0) [0|3] ""  HVESP01
 SG_ HVESP01_12v_input_error_1 : 38|2@1+ (1,0) [0|3] ""  HVESP01
 SG_ HVESP01_1_25v_error_1 : 36|2@1+ (1,0) [0|3] ""  HVESP01
 SG_ HVESP01_shunt_MIA_1 : 34|2@1+ (1,0) [0|3] ""  HVESP01
 SG_ HVESP01_SBC_int_reg_error_1 : 32|2@1+ (1,0) [0|3] ""  HVESP01
 SG_ HVESP01_pos_3_3v_analog_error_1 : 46|2@1+ (1,0) [0|3] ""  HVESP01
 SG_ HVESP01_outlt_clnt_thrm_open_1 : 44|2@1+ (1,0) [0|3] ""  HVESP01
 SG_ HVESP01_neg_3_3_analog_error_1 : 42|2@1+ (1,0) [0|3] ""  HVESP01
 SG_ HVESP01_inlet_clnt_thrm_open_1 : 40|2@1+ (1,0) [0|3] ""  HVESP01
 SG_ HVESP01_hall_eff_lo_rang_err_1 : 54|2@1+ (1,0) [0|3] ""  HVESP01
 SG_ HVESP01_outlt_clnt_thrm_short_1 : 52|2@1+ (1,0) [0|3] ""  HVESP01
 SG_ HVESP01_inlet_clnt_thrm_short_1 : 50|2@1+ (1,0) [0|3] ""  HVESP01
 SG_ HVESP01_3_3v_error_1 : 48|2@1+ (1,0) [0|3] ""  HVESP01

BO_ 2499745638 HVESP01_DiagnosticPrevC_2: 8 HVESP01
 SG_ HVESP01_PackVoltageImbalance_2 : 58|2@1+ (1,0) [0|3] ""  HVESP01
 SG_ HVESP01_PrechargeoverCurrent_2 : 56|2@1+ (1,0) [0|3] ""  HVESP01
 SG_ HVESP01_HVILvoltageError_2 : 2|2@1+ (1,0) [0|3] ""  HVESP01
 SG_ HVESP01_HVILcurrentReturnError_2 : 0|2@1+ (1,0) [0|3] ""  HVESP01
 SG_ HVESP01_PosFcContWelded_2 : 14|2@1+ (1,0) [0|3] ""  HVESP01
 SG_ HVESP01_PosContStuckOpen_2_2 : 12|2@1+ (1,0) [0|3] ""  HVESP01
 SG_ HVESP01_NegContWelded_2_2 : 10|2@1+ (1,0) [0|3] ""  HVESP01
 SG_ HVESP01_NegFcContStuckOpen_2 : 8|2@1+ (1,0) [0|3] ""  HVESP01
 SG_ HVESP01_IsospiBreak_2 : 22|2@1+ (1,0) [0|3] ""  HVESP01
 SG_ HVESP01_IsolationIntFault_2 : 20|2@1+ (1,0) [0|3] ""  HVESP01
 SG_ HVESP01_IsolationExtFault_2 : 18|2@1+ (1,0) [0|3] ""  HVESP01
 SG_ HVESP01_12v_filter_error_2 : 16|2@1+ (1,0) [0|3] ""  HVESP01
 SG_ HVESP01_hall_eff_hi_rang_err_2 : 30|2@1+ (1,0) [0|3] ""  HVESP01
 SG_ HVESP01_brick_volt_sns_open_2 : 28|2@1+ (1,0) [0|3] ""  HVESP01
 SG_ HVESP01_5v_error_2 : 26|2@1+ (1,0) [0|3] ""  HVESP01
 SG_ HVESP01_3_3_hot_error_2 : 24|2@1+ (1,0) [0|3] ""  HVESP01
 SG_ HVESP01_12v_input_error_2 : 38|2@1+ (1,0) [0|3] ""  HVESP01
 SG_ HVESP01_1_25v_error_2 : 36|2@1+ (1,0) [0|3] ""  HVESP01
 SG_ HVESP01_shunt_MIA_2 : 34|2@1+ (1,0) [0|3] ""  HVESP01
 SG_ HVESP01_SBC_int_reg_error_2 : 32|2@1+ (1,0) [0|3] ""  HVESP01
 SG_ HVESP01_pos_3_3v_analog_error_2 : 46|2@1+ (1,0) [0|3] ""  HVESP01
 SG_ HVESP01_outlt_clnt_thrm_open_2 : 44|2@1+ (1,0) [0|3] ""  HVESP01
 SG_ HVESP01_neg_3_3_analog_error_2 : 42|2@1+ (1,0) [0|3] ""  HVESP01
 SG_ HVESP01_inlet_clnt_thrm_open_2 : 40|2@1+ (1,0) [0|3] ""  HVESP01
 SG_ HVESP01_hall_eff_lo_rang_err_2 : 54|2@1+ (1,0) [0|3] ""  HVESP01
 SG_ HVESP01_outlt_clnt_thrm_short_2 : 52|2@1+ (1,0) [0|3] ""  HVESP01
 SG_ HVESP01_inlet_clnt_thrm_short_2 : 50|2@1+ (1,0) [0|3] ""  HVESP01
 SG_ HVESP01_3_3v_error_2 : 48|2@1+ (1,0) [0|3] ""  HVESP01

BO_ 2499745639 HVESP01_DiagnosticPrevC_3: 8 HVESP01
 SG_ HVESP01_PackVoltageImbalance_3 : 58|2@1+ (1,0) [0|3] ""  HVESP01
 SG_ HVESP01_PrechargeoverCurrent_3 : 56|2@1+ (1,0) [0|3] ""  HVESP01
 SG_ HVESP01_HVILvoltageError_3 : 2|2@1+ (1,0) [0|3] ""  HVESP01
 SG_ HVESP01_HVILcurrentReturnError_3 : 0|2@1+ (1,0) [0|3] ""  HVESP01
 SG_ HVESP01_PosFcContWelded_3 : 14|2@1+ (1,0) [0|3] ""  HVESP01
 SG_ HVESP01_PosContStuckOpen_2_3 : 12|2@1+ (1,0) [0|3] ""  HVESP01
 SG_ HVESP01_NegContWelded_2_3 : 10|2@1+ (1,0) [0|3] ""  HVESP01
 SG_ HVESP01_NegFcContStuckOpen_3 : 8|2@1+ (1,0) [0|3] ""  HVESP01
 SG_ HVESP01_IsospiBreak_3 : 22|2@1+ (1,0) [0|3] ""  HVESP01
 SG_ HVESP01_IsolationIntFault_3 : 20|2@1+ (1,0) [0|3] ""  HVESP01
 SG_ HVESP01_IsolationExtFault_3 : 18|2@1+ (1,0) [0|3] ""  HVESP01
 SG_ HVESP01_12v_filter_error_3 : 16|2@1+ (1,0) [0|3] ""  HVESP01
 SG_ HVESP01_hall_eff_hi_rang_err_3 : 30|2@1+ (1,0) [0|3] ""  HVESP01
 SG_ HVESP01_brick_volt_sns_open_3 : 28|2@1+ (1,0) [0|3] ""  HVESP01
 SG_ HVESP01_5v_error_3 : 26|2@1+ (1,0) [0|3] ""  HVESP01
 SG_ HVESP01_3_3_hot_error_3 : 24|2@1+ (1,0) [0|3] ""  HVESP01
 SG_ HVESP01_12v_input_error_3 : 38|2@1+ (1,0) [0|3] ""  HVESP01
 SG_ HVESP01_1_25v_error_3 : 36|2@1+ (1,0) [0|3] ""  HVESP01
 SG_ HVESP01_shunt_MIA_3 : 34|2@1+ (1,0) [0|3] ""  HVESP01
 SG_ HVESP01_SBC_int_reg_error_3 : 32|2@1+ (1,0) [0|3] ""  HVESP01
 SG_ HVESP01_pos_3_3v_analog_error_3 : 46|2@1+ (1,0) [0|3] ""  HVESP01
 SG_ HVESP01_outlt_clnt_thrm_open_3 : 44|2@1+ (1,0) [0|3] ""  HVESP01
 SG_ HVESP01_neg_3_3_analog_error_3 : 42|2@1+ (1,0) [0|3] ""  HVESP01
 SG_ HVESP01_inlet_clnt_thrm_open_3 : 40|2@1+ (1,0) [0|3] ""  HVESP01
 SG_ HVESP01_hall_eff_lo_rang_err_3 : 54|2@1+ (1,0) [0|3] ""  HVESP01
 SG_ HVESP01_outlt_clnt_thrm_short_3 : 52|2@1+ (1,0) [0|3] ""  HVESP01
 SG_ HVESP01_inlet_clnt_thrm_short_3 : 50|2@1+ (1,0) [0|3] ""  HVESP01
 SG_ HVESP01_3_3v_error_3 : 48|2@1+ (1,0) [0|3] ""  HVESP01

BO_ 2499745640 HVESP01_DiagnosticPrevC_4: 8 HVESP01
 SG_ HVESP01_PackVoltageImbalance_4 : 58|2@1+ (1,0) [0|3] ""  HVESP01
 SG_ HVESP01_PrechargeoverCurrent_4 : 56|2@1+ (1,0) [0|3] ""  HVESP01
 SG_ HVESP01_HVILvoltageError_4 : 2|2@1+ (1,0) [0|3] ""  HVESP01
 SG_ HVESP01_HVILcurrentReturnError_4 : 0|2@1+ (1,0) [0|3] ""  HVESP01
 SG_ HVESP01_PosFcContWelded_4 : 14|2@1+ (1,0) [0|3] ""  HVESP01
 SG_ HVESP01_PosContStuckOpen_2_4 : 12|2@1+ (1,0) [0|3] ""  HVESP01
 SG_ HVESP01_NegContWelded_2_4 : 10|2@1+ (1,0) [0|3] ""  HVESP01
 SG_ HVESP01_NegFcContStuckOpen_4 : 8|2@1+ (1,0) [0|3] ""  HVESP01
 SG_ HVESP01_IsospiBreak_4 : 22|2@1+ (1,0) [0|3] ""  HVESP01
 SG_ HVESP01_IsolationIntFault_4 : 20|2@1+ (1,0) [0|3] ""  HVESP01
 SG_ HVESP01_IsolationExtFault_4 : 18|2@1+ (1,0) [0|3] ""  HVESP01
 SG_ HVESP01_12v_filter_error_4 : 16|2@1+ (1,0) [0|3] ""  HVESP01
 SG_ HVESP01_hall_eff_hi_rang_err_4 : 30|2@1+ (1,0) [0|3] ""  HVESP01
 SG_ HVESP01_brick_volt_sns_open_4 : 28|2@1+ (1,0) [0|3] ""  HVESP01
 SG_ HVESP01_5v_error_4 : 26|2@1+ (1,0) [0|3] ""  HVESP01
 SG_ HVESP01_3_3_hot_error_4 : 24|2@1+ (1,0) [0|3] ""  HVESP01
 SG_ HVESP01_12v_input_error_4 : 38|2@1+ (1,0) [0|3] ""  HVESP01
 SG_ HVESP01_1_25v_error_4 : 36|2@1+ (1,0) [0|3] ""  HVESP01
 SG_ HVESP01_shunt_MIA_4 : 34|2@1+ (1,0) [0|3] ""  HVESP01
 SG_ HVESP01_SBC_int_reg_error_4 : 32|2@1+ (1,0) [0|3] ""  HVESP01
 SG_ HVESP01_pos_3_3v_analog_error_4 : 46|2@1+ (1,0) [0|3] ""  HVESP01
 SG_ HVESP01_outlt_clnt_thrm_open_4 : 44|2@1+ (1,0) [0|3] ""  HVESP01
 SG_ HVESP01_neg_3_3_analog_error_4 : 42|2@1+ (1,0) [0|3] ""  HVESP01
 SG_ HVESP01_inlet_clnt_thrm_open_4 : 40|2@1+ (1,0) [0|3] ""  HVESP01
 SG_ HVESP01_hall_eff_lo_rang_err_4 : 54|2@1+ (1,0) [0|3] ""  HVESP01
 SG_ HVESP01_outlt_clnt_thrm_short_4 : 52|2@1+ (1,0) [0|3] ""  HVESP01
 SG_ HVESP01_inlet_clnt_thrm_short_4 : 50|2@1+ (1,0) [0|3] ""  HVESP01
 SG_ HVESP01_3_3v_error_4 : 48|2@1+ (1,0) [0|3] ""  HVESP01

BO_ 2499745641 HVESP01_DiagnosticPrevC_5: 8 HVESP01
 SG_ HVESP01_PackVoltageImbalance_5 : 58|2@1+ (1,0) [0|3] ""  HVESP01
 SG_ HVESP01_PrechargeoverCurrent_5 : 56|2@1+ (1,0) [0|3] ""  HVESP01
 SG_ HVESP01_HVILvoltageError_5 : 2|2@1+ (1,0) [0|3] ""  HVESP01
 SG_ HVESP01_HVILcurrentReturnError_5 : 0|2@1+ (1,0) [0|3] ""  HVESP01
 SG_ HVESP01_PosFcContWelded_5 : 14|2@1+ (1,0) [0|3] ""  HVESP01
 SG_ HVESP01_PosContStuckOpen_2_5 : 12|2@1+ (1,0) [0|3] ""  HVESP01
 SG_ HVESP01_NegContWelded_2_5 : 10|2@1+ (1,0) [0|3] ""  HVESP01
 SG_ HVESP01_NegFcContStuckOpen_5 : 8|2@1+ (1,0) [0|3] ""  HVESP01
 SG_ HVESP01_IsospiBreak_5 : 22|2@1+ (1,0) [0|3] ""  HVESP01
 SG_ HVESP01_IsolationIntFault_5 : 20|2@1+ (1,0) [0|3] ""  HVESP01
 SG_ HVESP01_IsolationExtFault_5 : 18|2@1+ (1,0) [0|3] ""  HVESP01
 SG_ HVESP01_12v_filter_error_5 : 16|2@1+ (1,0) [0|3] ""  HVESP01
 SG_ HVESP01_hall_eff_hi_rang_err_5 : 30|2@1+ (1,0) [0|3] ""  HVESP01
 SG_ HVESP01_brick_volt_sns_open_5 : 28|2@1+ (1,0) [0|3] ""  HVESP01
 SG_ HVESP01_5v_error_5 : 26|2@1+ (1,0) [0|3] ""  HVESP01
 SG_ HVESP01_3_3_hot_error_5 : 24|2@1+ (1,0) [0|3] ""  HVESP01
 SG_ HVESP01_12v_input_error_5 : 38|2@1+ (1,0) [0|3] ""  HVESP01
 SG_ HVESP01_1_25v_error_5 : 36|2@1+ (1,0) [0|3] ""  HVESP01
 SG_ HVESP01_shunt_MIA_5 : 34|2@1+ (1,0) [0|3] ""  HVESP01
 SG_ HVESP01_SBC_int_reg_error_5 : 32|2@1+ (1,0) [0|3] ""  HVESP01
 SG_ HVESP01_pos_3_3v_analog_error_5 : 46|2@1+ (1,0) [0|3] ""  HVESP01
 SG_ HVESP01_outlt_clnt_thrm_open_5 : 44|2@1+ (1,0) [0|3] ""  HVESP01
 SG_ HVESP01_neg_3_3_analog_error_5 : 42|2@1+ (1,0) [0|3] ""  HVESP01
 SG_ HVESP01_inlet_clnt_thrm_open_5 : 40|2@1+ (1,0) [0|3] ""  HVESP01
 SG_ HVESP01_hall_eff_lo_rang_err_5 : 54|2@1+ (1,0) [0|3] ""  HVESP01
 SG_ HVESP01_outlt_clnt_thrm_short_5 : 52|2@1+ (1,0) [0|3] ""  HVESP01
 SG_ HVESP01_inlet_clnt_thrm_short_5 : 50|2@1+ (1,0) [0|3] ""  HVESP01
 SG_ HVESP01_3_3v_error_5 : 48|2@1+ (1,0) [0|3] ""  HVESP01

BO_ 2499745642 HVESP01_DiagnosticPrevC_6: 8 HVESP01
 SG_ HVESP01_PackVoltageImbalance_6 : 58|2@1+ (1,0) [0|3] ""  HVESP01
 SG_ HVESP01_PrechargeoverCurrent_6 : 56|2@1+ (1,0) [0|3] ""  HVESP01
 SG_ HVESP01_HVILvoltageError_6 : 2|2@1+ (1,0) [0|3] ""  HVESP01
 SG_ HVESP01_HVILcurrentReturnError_6 : 0|2@1+ (1,0) [0|3] ""  HVESP01
 SG_ HVESP01_PosFcContWelded_6 : 14|2@1+ (1,0) [0|3] ""  HVESP01
 SG_ HVESP01_PosContStuckOpen_2_6 : 12|2@1+ (1,0) [0|3] ""  HVESP01
 SG_ HVESP01_NegContWelded_2_6 : 10|2@1+ (1,0) [0|3] ""  HVESP01
 SG_ HVESP01_NegFcContStuckOpen_6 : 8|2@1+ (1,0) [0|3] ""  HVESP01
 SG_ HVESP01_IsospiBreak_6 : 22|2@1+ (1,0) [0|3] ""  HVESP01
 SG_ HVESP01_IsolationIntFault_6 : 20|2@1+ (1,0) [0|3] ""  HVESP01
 SG_ HVESP01_IsolationExtFault_6 : 18|2@1+ (1,0) [0|3] ""  HVESP01
 SG_ HVESP01_12v_filter_error_6 : 16|2@1+ (1,0) [0|3] ""  HVESP01
 SG_ HVESP01_hall_eff_hi_rang_err_6 : 30|2@1+ (1,0) [0|3] ""  HVESP01
 SG_ HVESP01_brick_volt_sns_open_6 : 28|2@1+ (1,0) [0|3] ""  HVESP01
 SG_ HVESP01_5v_error_6 : 26|2@1+ (1,0) [0|3] ""  HVESP01
 SG_ HVESP01_3_3_hot_error_6 : 24|2@1+ (1,0) [0|3] ""  HVESP01
 SG_ HVESP01_12v_input_error_6 : 38|2@1+ (1,0) [0|3] ""  HVESP01
 SG_ HVESP01_1_25v_error_6 : 36|2@1+ (1,0) [0|3] ""  HVESP01
 SG_ HVESP01_shunt_MIA_6 : 34|2@1+ (1,0) [0|3] ""  HVESP01
 SG_ HVESP01_SBC_int_reg_error_6 : 32|2@1+ (1,0) [0|3] ""  HVESP01
 SG_ HVESP01_pos_3_3v_analog_error_6 : 46|2@1+ (1,0) [0|3] ""  HVESP01
 SG_ HVESP01_outlt_clnt_thrm_open_6 : 44|2@1+ (1,0) [0|3] ""  HVESP01
 SG_ HVESP01_neg_3_3_analog_error_6 : 42|2@1+ (1,0) [0|3] ""  HVESP01
 SG_ HVESP01_inlet_clnt_thrm_open_6 : 40|2@1+ (1,0) [0|3] ""  HVESP01
 SG_ HVESP01_hall_eff_lo_rang_err_6 : 54|2@1+ (1,0) [0|3] ""  HVESP01
 SG_ HVESP01_outlt_clnt_thrm_short_6 : 52|2@1+ (1,0) [0|3] ""  HVESP01
 SG_ HVESP01_inlet_clnt_thrm_short_6 : 50|2@1+ (1,0) [0|3] ""  HVESP01
 SG_ HVESP01_3_3v_error_6 : 48|2@1+ (1,0) [0|3] ""  HVESP01

BO_ 2499745643 HVESP01_DiagnosticPrevC_7: 8 HVESP01
 SG_ HVESP01_PackVoltageImbalance_7 : 58|2@1+ (1,0) [0|3] ""  HVESP01
 SG_ HVESP01_PrechargeoverCurrent_7 : 56|2@1+ (1,0) [0|3] ""  HVESP01
 SG_ HVESP01_HVILvoltageError_7 : 2|2@1+ (1,0) [0|3] ""  HVESP01
 SG_ HVESP01_HVILcurrentReturnError_7 : 0|2@1+ (1,0) [0|3] ""  HVESP01
 SG_ HVESP01_PosFcContWelded_7 : 14|2@1+ (1,0) [0|3] ""  HVESP01
 SG_ HVESP01_PosContStuckOpen_2_7 : 12|2@1+ (1,0) [0|3] ""  HVESP01
 SG_ HVESP01_NegContWelded_2_7 : 10|2@1+ (1,0) [0|3] ""  HVESP01
 SG_ HVESP01_NegFcContStuckOpen_7 : 8|2@1+ (1,0) [0|3] ""  HVESP01
 SG_ HVESP01_IsospiBreak_7 : 22|2@1+ (1,0) [0|3] ""  HVESP01
 SG_ HVESP01_IsolationIntFault_7 : 20|2@1+ (1,0) [0|3] ""  HVESP01
 SG_ HVESP01_IsolationExtFault_7 : 18|2@1+ (1,0) [0|3] ""  HVESP01
 SG_ HVESP01_12v_filter_error_7 : 16|2@1+ (1,0) [0|3] ""  HVESP01
 SG_ HVESP01_hall_eff_hi_rang_err_7 : 30|2@1+ (1,0) [0|3] ""  HVESP01
 SG_ HVESP01_brick_volt_sns_open_7 : 28|2@1+ (1,0) [0|3] ""  HVESP01
 SG_ HVESP01_5v_error_7 : 26|2@1+ (1,0) [0|3] ""  HVESP01
 SG_ HVESP01_3_3_hot_error_7 : 24|2@1+ (1,0) [0|3] ""  HVESP01
 SG_ HVESP01_12v_input_error_7 : 38|2@1+ (1,0) [0|3] ""  HVESP01
 SG_ HVESP01_1_25v_error_7 : 36|2@1+ (1,0) [0|3] ""  HVESP01
 SG_ HVESP01_shunt_MIA_7 : 34|2@1+ (1,0) [0|3] ""  HVESP01
 SG_ HVESP01_SBC_int_reg_error_7 : 32|2@1+ (1,0) [0|3] ""  HVESP01
 SG_ HVESP01_pos_3_3v_analog_error_7 : 46|2@1+ (1,0) [0|3] ""  HVESP01
 SG_ HVESP01_outlt_clnt_thrm_open_7 : 44|2@1+ (1,0) [0|3] ""  HVESP01
 SG_ HVESP01_neg_3_3_analog_error_7 : 42|2@1+ (1,0) [0|3] ""  HVESP01
 SG_ HVESP01_inlet_clnt_thrm_open_7 : 40|2@1+ (1,0) [0|3] ""  HVESP01
 SG_ HVESP01_hall_eff_lo_rang_err_7 : 54|2@1+ (1,0) [0|3] ""  HVESP01
 SG_ HVESP01_outlt_clnt_thrm_short_7 : 52|2@1+ (1,0) [0|3] ""  HVESP01
 SG_ HVESP01_inlet_clnt_thrm_short_7 : 50|2@1+ (1,0) [0|3] ""  HVESP01
 SG_ HVESP01_3_3v_error_7 : 48|2@1+ (1,0) [0|3] ""  HVESP01

BO_ 2499745644 HVESP01_DiagnosticPrevC_8: 8 HVESP01
 SG_ HVESP01_PackVoltageImbalance_8 : 58|2@1+ (1,0) [0|3] ""  HVESP01
 SG_ HVESP01_PrechargeoverCurrent_8 : 56|2@1+ (1,0) [0|3] ""  HVESP01
 SG_ HVESP01_HVILvoltageError_8 : 2|2@1+ (1,0) [0|3] ""  HVESP01
 SG_ HVESP01_HVILcurrentReturnError_8 : 0|2@1+ (1,0) [0|3] ""  HVESP01
 SG_ HVESP01_PosFcContWelded_8 : 14|2@1+ (1,0) [0|3] ""  HVESP01
 SG_ HVESP01_PosContStuckOpen_2_8 : 12|2@1+ (1,0) [0|3] ""  HVESP01
 SG_ HVESP01_NegContWelded_2_8 : 10|2@1+ (1,0) [0|3] ""  HVESP01
 SG_ HVESP01_NegFcContStuckOpen_8 : 8|2@1+ (1,0) [0|3] ""  HVESP01
 SG_ HVESP01_IsospiBreak_8 : 22|2@1+ (1,0) [0|3] ""  HVESP01
 SG_ HVESP01_IsolationIntFault_8 : 20|2@1+ (1,0) [0|3] ""  HVESP01
 SG_ HVESP01_IsolationExtFault_8 : 18|2@1+ (1,0) [0|3] ""  HVESP01
 SG_ HVESP01_12v_filter_error_8 : 16|2@1+ (1,0) [0|3] ""  HVESP01
 SG_ HVESP01_hall_eff_hi_rang_err_8 : 30|2@1+ (1,0) [0|3] ""  HVESP01
 SG_ HVESP01_brick_volt_sns_open_8 : 28|2@1+ (1,0) [0|3] ""  HVESP01
 SG_ HVESP01_5v_error_8 : 26|2@1+ (1,0) [0|3] ""  HVESP01
 SG_ HVESP01_3_3_hot_error_8 : 24|2@1+ (1,0) [0|3] ""  HVESP01
 SG_ HVESP01_12v_input_error_8 : 38|2@1+ (1,0) [0|3] ""  HVESP01
 SG_ HVESP01_1_25v_error_8 : 36|2@1+ (1,0) [0|3] ""  HVESP01
 SG_ HVESP01_shunt_MIA_8 : 34|2@1+ (1,0) [0|3] ""  HVESP01
 SG_ HVESP01_SBC_int_reg_error_8 : 32|2@1+ (1,0) [0|3] ""  HVESP01
 SG_ HVESP01_pos_3_3v_analog_error_8 : 46|2@1+ (1,0) [0|3] ""  HVESP01
 SG_ HVESP01_outlt_clnt_thrm_open_8 : 44|2@1+ (1,0) [0|3] ""  HVESP01
 SG_ HVESP01_neg_3_3_analog_error_8 : 42|2@1+ (1,0) [0|3] ""  HVESP01
 SG_ HVESP01_inlet_clnt_thrm_open_8 : 40|2@1+ (1,0) [0|3] ""  HVESP01
 SG_ HVESP01_hall_eff_lo_rang_err_8 : 54|2@1+ (1,0) [0|3] ""  HVESP01
 SG_ HVESP01_outlt_clnt_thrm_short_8 : 52|2@1+ (1,0) [0|3] ""  HVESP01
 SG_ HVESP01_inlet_clnt_thrm_short_8 : 50|2@1+ (1,0) [0|3] ""  HVESP01
 SG_ HVESP01_3_3v_error_8 : 48|2@1+ (1,0) [0|3] ""  HVESP01

BO_ 2499745893 HVESP01_DiagnosticPrevD_1: 8 HVESP01
 SG_ HVESP01_BusJoinFailed_1 : 10|2@1+ (1,0) [0|3] ""  HVESP01
 SG_ HVESP01_ModuleThermFaultSevere_1 : 8|2@1+ (1,0) [0|3] ""  HVESP01
 SG_ HVESP01_Placeholder11_1 : 22|2@1+ (1,0) [0|3] ""  HVESP01
 SG_ HVESP01_HardwareUvloError_1 : 20|2@1+ (1,0) [0|3] ""  HVESP01
 SG_ HVESP01_Placeholder02_1 : 46|2@1+ (1,0) [0|3] ""  HVESP01
 SG_ HVESP01_Placeholder01_1 : 44|2@1+ (1,0) [0|3] ""  HVESP01
 SG_ HVESP01_HardwareOVError_1 : 18|2@1+ (1,0) [0|3] ""  HVESP01
 SG_ HVESP01_DoubleDcContWeld_1 : 16|2@1+ (1,0) [0|3] ""  HVESP01
 SG_ HVESP01_CurrentMismatch_1 : 30|2@1+ (1,0) [0|3] ""  HVESP01
 SG_ HVESP01_vBrickImbalanceWar_1 : 28|2@1+ (1,0) [0|3] ""  HVESP01
 SG_ HVESP01_vBrickImbalanceMod_1 : 26|2@1+ (1,0) [0|3] ""  HVESP01
 SG_ HVESP01_vBrickImbalanceSev_1 : 24|2@1+ (1,0) [0|3] ""  HVESP01
 SG_ HVESP01_Placeholder06_1 : 38|2@1+ (1,0) [0|3] ""  HVESP01
 SG_ HVESP01_Placeholder05_1 : 36|2@1+ (1,0) [0|3] ""  HVESP01
 SG_ HVESP01_SpeakerMia_1 : 2|2@1+ (1,0) [0|3] ""  HVESP01
 SG_ HVESP01_IsoSpiBreak_1 : 0|2@1+ (1,0) [0|3] ""  HVESP01
 SG_ HVESP01_VersionMismatch_1 : 14|2@1+ (1,0) [0|3] ""  HVESP01
 SG_ HVESP01_SystemPrechargeFail_1 : 12|2@1+ (1,0) [0|3] ""  HVESP01
 SG_ HVESP01_Placeholder04_1 : 34|2@1+ (1,0) [0|3] ""  HVESP01
 SG_ HVESP01_Placeholder03_1 : 32|2@1+ (1,0) [0|3] ""  HVESP01

BO_ 2499745894 HVESP01_DiagnosticPrevD_2: 8 HVESP01
 SG_ HVESP01_BusJoinFailed_2 : 10|2@1+ (1,0) [0|3] ""  HVESP01
 SG_ HVESP01_ModuleThermFaultSevere_2 : 8|2@1+ (1,0) [0|3] ""  HVESP01
 SG_ HVESP01_Placeholder11_2 : 22|2@1+ (1,0) [0|3] ""  HVESP01
 SG_ HVESP01_HardwareUvloError_2 : 20|2@1+ (1,0) [0|3] ""  HVESP01
 SG_ HVESP01_Placeholder02_2 : 46|2@1+ (1,0) [0|3] ""  HVESP01
 SG_ HVESP01_Placeholder01_2 : 44|2@1+ (1,0) [0|3] ""  HVESP01
 SG_ HVESP01_HardwareOVError_2 : 18|2@1+ (1,0) [0|3] ""  HVESP01
 SG_ HVESP01_DoubleDcContWeld_2 : 16|2@1+ (1,0) [0|3] ""  HVESP01
 SG_ HVESP01_CurrentMismatch_2 : 30|2@1+ (1,0) [0|3] ""  HVESP01
 SG_ HVESP01_vBrickImbalanceWar_2 : 28|2@1+ (1,0) [0|3] ""  HVESP01
 SG_ HVESP01_vBrickImbalanceMod_2 : 26|2@1+ (1,0) [0|3] ""  HVESP01
 SG_ HVESP01_vBrickImbalanceSev_2 : 24|2@1+ (1,0) [0|3] ""  HVESP01
 SG_ HVESP01_Placeholder06_2 : 38|2@1+ (1,0) [0|3] ""  HVESP01
 SG_ HVESP01_Placeholder05_2 : 36|2@1+ (1,0) [0|3] ""  HVESP01
 SG_ HVESP01_SpeakerMia_2 : 2|2@1+ (1,0) [0|3] ""  HVESP01
 SG_ HVESP01_IsoSpiBreak_2 : 0|2@1+ (1,0) [0|3] ""  HVESP01
 SG_ HVESP01_VersionMismatch_2 : 14|2@1+ (1,0) [0|3] ""  HVESP01
 SG_ HVESP01_SystemPrechargeFail_2 : 12|2@1+ (1,0) [0|3] ""  HVESP01
 SG_ HVESP01_Placeholder04_2 : 34|2@1+ (1,0) [0|3] ""  HVESP01
 SG_ HVESP01_Placeholder03_2 : 32|2@1+ (1,0) [0|3] ""  HVESP01

BO_ 2499745895 HVESP01_DiagnosticPrevD_3: 8 HVESP01
 SG_ HVESP01_BusJoinFailed_3 : 10|2@1+ (1,0) [0|3] ""  HVESP01
 SG_ HVESP01_ModuleThermFaultSevere_3 : 8|2@1+ (1,0) [0|3] ""  HVESP01
 SG_ HVESP01_Placeholder11_3 : 22|2@1+ (1,0) [0|3] ""  HVESP01
 SG_ HVESP01_HardwareUvloError_3 : 20|2@1+ (1,0) [0|3] ""  HVESP01
 SG_ HVESP01_Placeholder02_3 : 46|2@1+ (1,0) [0|3] ""  HVESP01
 SG_ HVESP01_Placeholder01_3 : 44|2@1+ (1,0) [0|3] ""  HVESP01
 SG_ HVESP01_HardwareOVError_3 : 18|2@1+ (1,0) [0|3] ""  HVESP01
 SG_ HVESP01_DoubleDcContWeld_3 : 16|2@1+ (1,0) [0|3] ""  HVESP01
 SG_ HVESP01_CurrentMismatch_3 : 30|2@1+ (1,0) [0|3] ""  HVESP01
 SG_ HVESP01_vBrickImbalanceWar_3 : 28|2@1+ (1,0) [0|3] ""  HVESP01
 SG_ HVESP01_vBrickImbalanceMod_3 : 26|2@1+ (1,0) [0|3] ""  HVESP01
 SG_ HVESP01_vBrickImbalanceSev_3 : 24|2@1+ (1,0) [0|3] ""  HVESP01
 SG_ HVESP01_Placeholder06_3 : 38|2@1+ (1,0) [0|3] ""  HVESP01
 SG_ HVESP01_Placeholder05_3 : 36|2@1+ (1,0) [0|3] ""  HVESP01
 SG_ HVESP01_SpeakerMia_3 : 2|2@1+ (1,0) [0|3] ""  HVESP01
 SG_ HVESP01_IsoSpiBreak_3 : 0|2@1+ (1,0) [0|3] ""  HVESP01
 SG_ HVESP01_VersionMismatch_3 : 14|2@1+ (1,0) [0|3] ""  HVESP01
 SG_ HVESP01_SystemPrechargeFail_3 : 12|2@1+ (1,0) [0|3] ""  HVESP01
 SG_ HVESP01_Placeholder04_3 : 34|2@1+ (1,0) [0|3] ""  HVESP01
 SG_ HVESP01_Placeholder03_3 : 32|2@1+ (1,0) [0|3] ""  HVESP01

BO_ 2499745896 HVESP01_DiagnosticPrevD_4: 8 HVESP01
 SG_ HVESP01_BusJoinFailed_4 : 10|2@1+ (1,0) [0|3] ""  HVESP01
 SG_ HVESP01_ModuleThermFaultSevere_4 : 8|2@1+ (1,0) [0|3] ""  HVESP01
 SG_ HVESP01_Placeholder11_4 : 22|2@1+ (1,0) [0|3] ""  HVESP01
 SG_ HVESP01_HardwareUvloError_4 : 20|2@1+ (1,0) [0|3] ""  HVESP01
 SG_ HVESP01_Placeholder02_4 : 46|2@1+ (1,0) [0|3] ""  HVESP01
 SG_ HVESP01_Placeholder01_4 : 44|2@1+ (1,0) [0|3] ""  HVESP01
 SG_ HVESP01_HardwareOVError_4 : 18|2@1+ (1,0) [0|3] ""  HVESP01
 SG_ HVESP01_DoubleDcContWeld_4 : 16|2@1+ (1,0) [0|3] ""  HVESP01
 SG_ HVESP01_CurrentMismatch_4 : 30|2@1+ (1,0) [0|3] ""  HVESP01
 SG_ HVESP01_vBrickImbalanceWar_4 : 28|2@1+ (1,0) [0|3] ""  HVESP01
 SG_ HVESP01_vBrickImbalanceMod_4 : 26|2@1+ (1,0) [0|3] ""  HVESP01
 SG_ HVESP01_vBrickImbalanceSev_4 : 24|2@1+ (1,0) [0|3] ""  HVESP01
 SG_ HVESP01_Placeholder06_4 : 38|2@1+ (1,0) [0|3] ""  HVESP01
 SG_ HVESP01_Placeholder05_4 : 36|2@1+ (1,0) [0|3] ""  HVESP01
 SG_ HVESP01_SpeakerMia_4 : 2|2@1+ (1,0) [0|3] ""  HVESP01
 SG_ HVESP01_IsoSpiBreak_4 : 0|2@1+ (1,0) [0|3] ""  HVESP01
 SG_ HVESP01_VersionMismatch_4 : 14|2@1+ (1,0) [0|3] ""  HVESP01
 SG_ HVESP01_SystemPrechargeFail_4 : 12|2@1+ (1,0) [0|3] ""  HVESP01
 SG_ HVESP01_Placeholder04_4 : 34|2@1+ (1,0) [0|3] ""  HVESP01
 SG_ HVESP01_Placeholder03_4 : 32|2@1+ (1,0) [0|3] ""  HVESP01

BO_ 2499745897 HVESP01_DiagnosticPrevD_5: 8 HVESP01
 SG_ HVESP01_BusJoinFailed_5 : 10|2@1+ (1,0) [0|3] ""  HVESP01
 SG_ HVESP01_ModuleThermFaultSevere_5 : 8|2@1+ (1,0) [0|3] ""  HVESP01
 SG_ HVESP01_Placeholder11_5 : 22|2@1+ (1,0) [0|3] ""  HVESP01
 SG_ HVESP01_HardwareUvloError_5 : 20|2@1+ (1,0) [0|3] ""  HVESP01
 SG_ HVESP01_Placeholder02_5 : 46|2@1+ (1,0) [0|3] ""  HVESP01
 SG_ HVESP01_Placeholder01_5 : 44|2@1+ (1,0) [0|3] ""  HVESP01
 SG_ HVESP01_HardwareOVError_5 : 18|2@1+ (1,0) [0|3] ""  HVESP01
 SG_ HVESP01_DoubleDcContWeld_5 : 16|2@1+ (1,0) [0|3] ""  HVESP01
 SG_ HVESP01_CurrentMismatch_5 : 30|2@1+ (1,0) [0|3] ""  HVESP01
 SG_ HVESP01_vBrickImbalanceWar_5 : 28|2@1+ (1,0) [0|3] ""  HVESP01
 SG_ HVESP01_vBrickImbalanceMod_5 : 26|2@1+ (1,0) [0|3] ""  HVESP01
 SG_ HVESP01_vBrickImbalanceSev_5 : 24|2@1+ (1,0) [0|3] ""  HVESP01
 SG_ HVESP01_Placeholder06_5 : 38|2@1+ (1,0) [0|3] ""  HVESP01
 SG_ HVESP01_Placeholder05_5 : 36|2@1+ (1,0) [0|3] ""  HVESP01
 SG_ HVESP01_SpeakerMia_5 : 2|2@1+ (1,0) [0|3] ""  HVESP01
 SG_ HVESP01_IsoSpiBreak_5 : 0|2@1+ (1,0) [0|3] ""  HVESP01
 SG_ HVESP01_VersionMismatch_5 : 14|2@1+ (1,0) [0|3] ""  HVESP01
 SG_ HVESP01_SystemPrechargeFail_5 : 12|2@1+ (1,0) [0|3] ""  HVESP01
 SG_ HVESP01_Placeholder04_5 : 34|2@1+ (1,0) [0|3] ""  HVESP01
 SG_ HVESP01_Placeholder03_5 : 32|2@1+ (1,0) [0|3] ""  HVESP01

BO_ 2499745898 HVESP01_DiagnosticPrevD_6: 8 HVESP01
 SG_ HVESP01_BusJoinFailed_6 : 10|2@1+ (1,0) [0|3] ""  HVESP01
 SG_ HVESP01_ModuleThermFaultSevere_6 : 8|2@1+ (1,0) [0|3] ""  HVESP01
 SG_ HVESP01_Placeholder11_6 : 22|2@1+ (1,0) [0|3] ""  HVESP01
 SG_ HVESP01_HardwareUvloError_6 : 20|2@1+ (1,0) [0|3] ""  HVESP01
 SG_ HVESP01_Placeholder02_6 : 46|2@1+ (1,0) [0|3] ""  HVESP01
 SG_ HVESP01_Placeholder01_6 : 44|2@1+ (1,0) [0|3] ""  HVESP01
 SG_ HVESP01_HardwareOVError_6 : 18|2@1+ (1,0) [0|3] ""  HVESP01
 SG_ HVESP01_DoubleDcContWeld_6 : 16|2@1+ (1,0) [0|3] ""  HVESP01
 SG_ HVESP01_CurrentMismatch_6 : 30|2@1+ (1,0) [0|3] ""  HVESP01
 SG_ HVESP01_vBrickImbalanceWar_6 : 28|2@1+ (1,0) [0|3] ""  HVESP01
 SG_ HVESP01_vBrickImbalanceMod_6 : 26|2@1+ (1,0) [0|3] ""  HVESP01
 SG_ HVESP01_vBrickImbalanceSev_6 : 24|2@1+ (1,0) [0|3] ""  HVESP01
 SG_ HVESP01_Placeholder06_6 : 38|2@1+ (1,0) [0|3] ""  HVESP01
 SG_ HVESP01_Placeholder05_6 : 36|2@1+ (1,0) [0|3] ""  HVESP01
 SG_ HVESP01_SpeakerMia_6 : 2|2@1+ (1,0) [0|3] ""  HVESP01
 SG_ HVESP01_IsoSpiBreak_6 : 0|2@1+ (1,0) [0|3] ""  HVESP01
 SG_ HVESP01_VersionMismatch_6 : 14|2@1+ (1,0) [0|3] ""  HVESP01
 SG_ HVESP01_SystemPrechargeFail_6 : 12|2@1+ (1,0) [0|3] ""  HVESP01
 SG_ HVESP01_Placeholder04_6 : 34|2@1+ (1,0) [0|3] ""  HVESP01
 SG_ HVESP01_Placeholder03_6 : 32|2@1+ (1,0) [0|3] ""  HVESP01

BO_ 2499745899 HVESP01_DiagnosticPrevD_7: 8 HVESP01
 SG_ HVESP01_BusJoinFailed_7 : 10|2@1+ (1,0) [0|3] ""  HVESP01
 SG_ HVESP01_ModuleThermFaultSevere_7 : 8|2@1+ (1,0) [0|3] ""  HVESP01
 SG_ HVESP01_Placeholder11_7 : 22|2@1+ (1,0) [0|3] ""  HVESP01
 SG_ HVESP01_HardwareUvloError_7 : 20|2@1+ (1,0) [0|3] ""  HVESP01
 SG_ HVESP01_Placeholder02_7 : 46|2@1+ (1,0) [0|3] ""  HVESP01
 SG_ HVESP01_Placeholder01_7 : 44|2@1+ (1,0) [0|3] ""  HVESP01
 SG_ HVESP01_HardwareOVError_7 : 18|2@1+ (1,0) [0|3] ""  HVESP01
 SG_ HVESP01_DoubleDcContWeld_7 : 16|2@1+ (1,0) [0|3] ""  HVESP01
 SG_ HVESP01_CurrentMismatch_7 : 30|2@1+ (1,0) [0|3] ""  HVESP01
 SG_ HVESP01_vBrickImbalanceWar_7 : 28|2@1+ (1,0) [0|3] ""  HVESP01
 SG_ HVESP01_vBrickImbalanceMod_7 : 26|2@1+ (1,0) [0|3] ""  HVESP01
 SG_ HVESP01_vBrickImbalanceSev_7 : 24|2@1+ (1,0) [0|3] ""  HVESP01
 SG_ HVESP01_Placeholder06_7 : 38|2@1+ (1,0) [0|3] ""  HVESP01
 SG_ HVESP01_Placeholder05_7 : 36|2@1+ (1,0) [0|3] ""  HVESP01
 SG_ HVESP01_SpeakerMia_7 : 2|2@1+ (1,0) [0|3] ""  HVESP01
 SG_ HVESP01_IsoSpiBreak_7 : 0|2@1+ (1,0) [0|3] ""  HVESP01
 SG_ HVESP01_VersionMismatch_7 : 14|2@1+ (1,0) [0|3] ""  HVESP01
 SG_ HVESP01_SystemPrechargeFail_7 : 12|2@1+ (1,0) [0|3] ""  HVESP01
 SG_ HVESP01_Placeholder04_7 : 34|2@1+ (1,0) [0|3] ""  HVESP01
 SG_ HVESP01_Placeholder03_7 : 32|2@1+ (1,0) [0|3] ""  HVESP01

BO_ 2499745900 HVESP01_DiagnosticPrevD_8: 8 HVESP01
 SG_ HVESP01_BusJoinFailed_8 : 10|2@1+ (1,0) [0|3] ""  HVESP01
 SG_ HVESP01_ModuleThermFaultSevere_8 : 8|2@1+ (1,0) [0|3] ""  HVESP01
 SG_ HVESP01_Placeholder11_8 : 22|2@1+ (1,0) [0|3] ""  HVESP01
 SG_ HVESP01_HardwareUvloError_8 : 20|2@1+ (1,0) [0|3] ""  HVESP01
 SG_ HVESP01_Placeholder02_8 : 46|2@1+ (1,0) [0|3] ""  HVESP01
 SG_ HVESP01_Placeholder01_8 : 44|2@1+ (1,0) [0|3] ""  HVESP01
 SG_ HVESP01_HardwareOVError_8 : 18|2@1+ (1,0) [0|3] ""  HVESP01
 SG_ HVESP01_DoubleDcContWeld_8 : 16|2@1+ (1,0) [0|3] ""  HVESP01
 SG_ HVESP01_CurrentMismatch_8 : 30|2@1+ (1,0) [0|3] ""  HVESP01
 SG_ HVESP01_vBrickImbalanceWar_8 : 28|2@1+ (1,0) [0|3] ""  HVESP01
 SG_ HVESP01_vBrickImbalanceMod_8 : 26|2@1+ (1,0) [0|3] ""  HVESP01
 SG_ HVESP01_vBrickImbalanceSev_8 : 24|2@1+ (1,0) [0|3] ""  HVESP01
 SG_ HVESP01_Placeholder06_8 : 38|2@1+ (1,0) [0|3] ""  HVESP01
 SG_ HVESP01_Placeholder05_8 : 36|2@1+ (1,0) [0|3] ""  HVESP01
 SG_ HVESP01_SpeakerMia_8 : 2|2@1+ (1,0) [0|3] ""  HVESP01
 SG_ HVESP01_IsoSpiBreak_8 : 0|2@1+ (1,0) [0|3] ""  HVESP01
 SG_ HVESP01_VersionMismatch_8 : 14|2@1+ (1,0) [0|3] ""  HVESP01
 SG_ HVESP01_SystemPrechargeFail_8 : 12|2@1+ (1,0) [0|3] ""  HVESP01
 SG_ HVESP01_Placeholder04_8 : 34|2@1+ (1,0) [0|3] ""  HVESP01
 SG_ HVESP01_Placeholder03_8 : 32|2@1+ (1,0) [0|3] ""  HVESP01

BO_ 2499746149 HVESP01_Current_1: 8 HVESP01
 SG_ HVESP01_currentSecondary_1 : 0|22@1+ (0.001,-1600) [-1600|1600] "A"  HVESP01
 SG_ HVESP01_currentPrimary_1 : 40|22@1+ (0.001,-1600) [-1600|1600] "A"  HVESP01

BO_ 2499746150 HVESP01_Current_2: 8 HVESP01
 SG_ HVESP01_currentSecondary_2 : 0|22@1+ (0.001,-1600) [-1600|1600] "A"  HVESP01
 SG_ HVESP01_currentPrimary_2 : 40|22@1+ (0.001,-1600) [-1600|1600] "A"  HVESP01

BO_ 2499746151 HVESP01_Current_3: 8 HVESP01
 SG_ HVESP01_currentSecondary_3 : 0|22@1+ (0.001,-1600) [-1600|1600] "A"  HVESP01
 SG_ HVESP01_currentPrimary_3 : 40|22@1+ (0.001,-1600) [-1600|1600] "A"  HVESP01

BO_ 2499746152 HVESP01_Current_4: 8 HVESP01
 SG_ HVESP01_currentSecondary_4 : 0|22@1+ (0.001,-1600) [-1600|1600] "A"  HVESP01
 SG_ HVESP01_currentPrimary_4 : 40|22@1+ (0.001,-1600) [-1600|1600] "A"  HVESP01

BO_ 2499746153 HVESP01_Current_5: 8 HVESP01
 SG_ HVESP01_currentSecondary_5 : 0|22@1+ (0.001,-1600) [-1600|1600] "A"  HVESP01
 SG_ HVESP01_currentPrimary_5 : 40|22@1+ (0.001,-1600) [-1600|1600] "A"  HVESP01

BO_ 2499746154 HVESP01_Current_6: 8 HVESP01
 SG_ HVESP01_currentSecondary_6 : 0|22@1+ (0.001,-1600) [-1600|1600] "A"  HVESP01
 SG_ HVESP01_currentPrimary_6 : 40|22@1+ (0.001,-1600) [-1600|1600] "A"  HVESP01

BO_ 2499746155 HVESP01_Current_7: 8 HVESP01
 SG_ HVESP01_currentSecondary_7 : 0|22@1+ (0.001,-1600) [-1600|1600] "A"  HVESP01
 SG_ HVESP01_currentPrimary_7 : 40|22@1+ (0.001,-1600) [-1600|1600] "A"  HVESP01

BO_ 2499746156 HVESP01_Current_8: 8 HVESP01
 SG_ HVESP01_currentSecondary_8 : 0|22@1+ (0.001,-1600) [-1600|1600] "A"  HVESP01
 SG_ HVESP01_currentPrimary_8 : 40|22@1+ (0.001,-1600) [-1600|1600] "A"  HVESP01

BO_ 2499747941 HVESP01_VoltageDiag_1: 8 HVESP01
 SG_ HVESP01_diagVPackPos_1 : 16|16@1+ (0.02,0) [0|1310.7] "v"  HVESP01
 SG_ HVESP01_diagVPackNeg_1 : 0|16@1+ (0.02,0) [0|1310.7] "v"  HVESP01
 SG_ HVESP01_diagVLoadNeg_1 : 32|16@1+ (0.02,0) [0|1310.7] "v"  HVESP01
 SG_ HVESP01_diagVLoadPos_1 : 48|16@1+ (0.02,0) [0|1310.7] "v"  HVESP01

BO_ 2499747942 HVESP01_VoltageDiag_2: 8 HVESP01
 SG_ HVESP01_diagVPackPos_2 : 16|16@1+ (0.02,0) [0|1310.7] "v"  HVESP01
 SG_ HVESP01_diagVPackNeg_2 : 0|16@1+ (0.02,0) [0|1310.7] "v"  HVESP01
 SG_ HVESP01_diagVLoadNeg_2 : 32|16@1+ (0.02,0) [0|1310.7] "v"  HVESP01
 SG_ HVESP01_diagVLoadPos_2 : 48|16@1+ (0.02,0) [0|1310.7] "v"  HVESP01

BO_ 2499747943 HVESP01_VoltageDiag_3: 8 HVESP01
 SG_ HVESP01_diagVPackPos_3 : 16|16@1+ (0.02,0) [0|1310.7] "v"  HVESP01
 SG_ HVESP01_diagVPackNeg_3 : 0|16@1+ (0.02,0) [0|1310.7] "v"  HVESP01
 SG_ HVESP01_diagVLoadNeg_3 : 32|16@1+ (0.02,0) [0|1310.7] "v"  HVESP01
 SG_ HVESP01_diagVLoadPos_3 : 48|16@1+ (0.02,0) [0|1310.7] "v"  HVESP01

BO_ 2499747944 HVESP01_VoltageDiag_4: 8 HVESP01
 SG_ HVESP01_diagVPackPos_4 : 16|16@1+ (0.02,0) [0|1310.7] "v"  HVESP01
 SG_ HVESP01_diagVPackNeg_4 : 0|16@1+ (0.02,0) [0|1310.7] "v"  HVESP01
 SG_ HVESP01_diagVLoadNeg_4 : 32|16@1+ (0.02,0) [0|1310.7] "v"  HVESP01
 SG_ HVESP01_diagVLoadPos_4 : 48|16@1+ (0.02,0) [0|1310.7] "v"  HVESP01

BO_ 2499747945 HVESP01_VoltageDiag_5: 8 HVESP01
 SG_ HVESP01_diagVPackPos_5 : 16|16@1+ (0.02,0) [0|1310.7] "v"  HVESP01
 SG_ HVESP01_diagVPackNeg_5 : 0|16@1+ (0.02,0) [0|1310.7] "v"  HVESP01
 SG_ HVESP01_diagVLoadNeg_5 : 32|16@1+ (0.02,0) [0|1310.7] "v"  HVESP01
 SG_ HVESP01_diagVLoadPos_5 : 48|16@1+ (0.02,0) [0|1310.7] "v"  HVESP01

BO_ 2499747946 HVESP01_VoltageDiag_6: 8 HVESP01
 SG_ HVESP01_diagVPackPos_6 : 16|16@1+ (0.02,0) [0|1310.7] "v"  HVESP01
 SG_ HVESP01_diagVPackNeg_6 : 0|16@1+ (0.02,0) [0|1310.7] "v"  HVESP01
 SG_ HVESP01_diagVLoadNeg_6 : 32|16@1+ (0.02,0) [0|1310.7] "v"  HVESP01
 SG_ HVESP01_diagVLoadPos_6 : 48|16@1+ (0.02,0) [0|1310.7] "v"  HVESP01

BO_ 2499747947 HVESP01_VoltageDiag_7: 8 HVESP01
 SG_ HVESP01_diagVPackPos_7 : 16|16@1+ (0.02,0) [0|1310.7] "v"  HVESP01
 SG_ HVESP01_diagVPackNeg_7 : 0|16@1+ (0.02,0) [0|1310.7] "v"  HVESP01
 SG_ HVESP01_diagVLoadNeg_7 : 32|16@1+ (0.02,0) [0|1310.7] "v"  HVESP01
 SG_ HVESP01_diagVLoadPos_7 : 48|16@1+ (0.02,0) [0|1310.7] "v"  HVESP01

BO_ 2499747948 HVESP01_VoltageDiag_8: 8 HVESP01
 SG_ HVESP01_diagVPackPos_8 : 16|16@1+ (0.02,0) [0|1310.7] "v"  HVESP01
 SG_ HVESP01_diagVPackNeg_8 : 0|16@1+ (0.02,0) [0|1310.7] "v"  HVESP01
 SG_ HVESP01_diagVLoadNeg_8 : 32|16@1+ (0.02,0) [0|1310.7] "v"  HVESP01
 SG_ HVESP01_diagVLoadPos_8 : 48|16@1+ (0.02,0) [0|1310.7] "v"  HVESP01

BO_ 2499748197 HVESP01_BMSDiag_1: 6 HVESP01
 SG_ HVESP01_pyroCheckResult_1 : 0|16@1+ (0.001,0) [0|30] "V"  HVESP01
 SG_ HVESP01_dc_pos_cntr_coil_1 : 16|16@1+ (0.01,0) [0|655] "V"  HVESP01
 SG_ HVESP01_dc_neg_cntr_coil_1 : 32|16@1+ (0.01,0) [0|655] "V"  HVESP01

BO_ 2499748198 HVESP01_BMSDiag_2: 6 HVESP01
 SG_ HVESP01_pyroCheckResult_2 : 0|16@1+ (0.001,0) [0|30] "V"  HVESP01
 SG_ HVESP01_dc_pos_cntr_coil_2 : 16|16@1+ (0.01,0) [0|655] "V"  HVESP01
 SG_ HVESP01_dc_neg_cntr_coil_2 : 32|16@1+ (0.01,0) [0|655] "V"  HVESP01

BO_ 2499748199 HVESP01_BMSDiag_3: 6 HVESP01
 SG_ HVESP01_pyroCheckResult_3 : 0|16@1+ (0.001,0) [0|30] "V"  HVESP01
 SG_ HVESP01_dc_pos_cntr_coil_3 : 16|16@1+ (0.01,0) [0|655] "V"  HVESP01
 SG_ HVESP01_dc_neg_cntr_coil_3 : 32|16@1+ (0.01,0) [0|655] "V"  HVESP01

BO_ 2499748200 HVESP01_BMSDiag_4: 6 HVESP01
 SG_ HVESP01_pyroCheckResult_4 : 0|16@1+ (0.001,0) [0|30] "V"  HVESP01
 SG_ HVESP01_dc_pos_cntr_coil_4 : 16|16@1+ (0.01,0) [0|655] "V"  HVESP01
 SG_ HVESP01_dc_neg_cntr_coil_4 : 32|16@1+ (0.01,0) [0|655] "V"  HVESP01

BO_ 2499748201 HVESP01_BMSDiag_5: 6 HVESP01
 SG_ HVESP01_pyroCheckResult_5 : 0|16@1+ (0.001,0) [0|30] "V"  HVESP01
 SG_ HVESP01_dc_pos_cntr_coil_5 : 16|16@1+ (0.01,0) [0|655] "V"  HVESP01
 SG_ HVESP01_dc_neg_cntr_coil_5 : 32|16@1+ (0.01,0) [0|655] "V"  HVESP01

BO_ 2499748202 HVESP01_BMSDiag_6: 6 HVESP01
 SG_ HVESP01_pyroCheckResult_6 : 0|16@1+ (0.001,0) [0|30] "V"  HVESP01
 SG_ HVESP01_dc_pos_cntr_coil_6 : 16|16@1+ (0.01,0) [0|655] "V"  HVESP01
 SG_ HVESP01_dc_neg_cntr_coil_6 : 32|16@1+ (0.01,0) [0|655] "V"  HVESP01

BO_ 2499748203 HVESP01_BMSDiag_7: 6 HVESP01
 SG_ HVESP01_pyroCheckResult_7 : 0|16@1+ (0.001,0) [0|30] "V"  HVESP01
 SG_ HVESP01_dc_pos_cntr_coil_7 : 16|16@1+ (0.01,0) [0|655] "V"  HVESP01
 SG_ HVESP01_dc_neg_cntr_coil_7 : 32|16@1+ (0.01,0) [0|655] "V"  HVESP01

BO_ 2499748204 HVESP01_BMSDiag_8: 6 HVESP01
 SG_ HVESP01_pyroCheckResult_8 : 0|16@1+ (0.001,0) [0|30] "V"  HVESP01
 SG_ HVESP01_dc_pos_cntr_coil_8 : 16|16@1+ (0.01,0) [0|655] "V"  HVESP01
 SG_ HVESP01_dc_neg_cntr_coil_8 : 32|16@1+ (0.01,0) [0|655] "V"  HVESP01

BO_ 2499748453 HVESP01_SleepWake_1: 8 HVESP01
 SG_ HVESP01_timeAsleepSec_1 : 32|32@1+ (1,0) [0|4294967295] "seconds"  HVESP01
 SG_ HVESP01_timeAwakeSec_1 : 0|32@1+ (1,0) [0|4294967295] "seconds"  HVESP01

BO_ 2499748454 HVESP01_SleepWake_2: 8 HVESP01
 SG_ HVESP01_timeAsleepSec_2 : 32|32@1+ (1,0) [0|4294967295] "seconds"  HVESP01
 SG_ HVESP01_timeAwakeSec_2 : 0|32@1+ (1,0) [0|4294967295] "seconds"  HVESP01

BO_ 2499748455 HVESP01_SleepWake_3: 8 HVESP01
 SG_ HVESP01_timeAsleepSec_3 : 32|32@1+ (1,0) [0|4294967295] "seconds"  HVESP01
 SG_ HVESP01_timeAwakeSec_3 : 0|32@1+ (1,0) [0|4294967295] "seconds"  HVESP01

BO_ 2499748456 HVESP01_SleepWake_4: 8 HVESP01
 SG_ HVESP01_timeAsleepSec_4 : 32|32@1+ (1,0) [0|4294967295] "seconds"  HVESP01
 SG_ HVESP01_timeAwakeSec_4 : 0|32@1+ (1,0) [0|4294967295] "seconds"  HVESP01

BO_ 2499748457 HVESP01_SleepWake_5: 8 HVESP01
 SG_ HVESP01_timeAsleepSec_5 : 32|32@1+ (1,0) [0|4294967295] "seconds"  HVESP01
 SG_ HVESP01_timeAwakeSec_5 : 0|32@1+ (1,0) [0|4294967295] "seconds"  HVESP01

BO_ 2499748458 HVESP01_SleepWake_6: 8 HVESP01
 SG_ HVESP01_timeAsleepSec_6 : 32|32@1+ (1,0) [0|4294967295] "seconds"  HVESP01
 SG_ HVESP01_timeAwakeSec_6 : 0|32@1+ (1,0) [0|4294967295] "seconds"  HVESP01

BO_ 2499748459 HVESP01_SleepWake_7: 8 HVESP01
 SG_ HVESP01_timeAsleepSec_7 : 32|32@1+ (1,0) [0|4294967295] "seconds"  HVESP01
 SG_ HVESP01_timeAwakeSec_7 : 0|32@1+ (1,0) [0|4294967295] "seconds"  HVESP01

BO_ 2499748460 HVESP01_SleepWake_8: 8 HVESP01
 SG_ HVESP01_timeAsleepSec_8 : 32|32@1+ (1,0) [0|4294967295] "seconds"  HVESP01
 SG_ HVESP01_timeAwakeSec_8 : 0|32@1+ (1,0) [0|4294967295] "seconds"  HVESP01

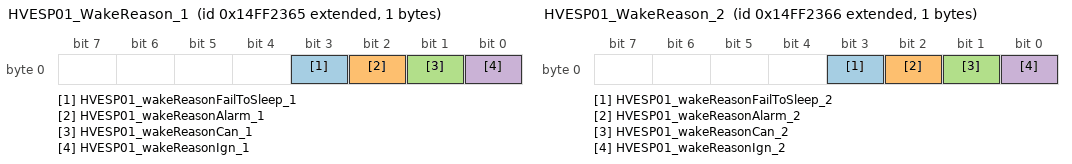
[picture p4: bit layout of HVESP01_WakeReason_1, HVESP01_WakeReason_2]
BO_ 2499748709 HVESP01_WakeReason_1: 1 HVESP01
 SG_ HVESP01_wakeReasonFailToSleep_1 : 3|1@1+ (1,0) [0|1] ""  HVESP01
 SG_ HVESP01_wakeReasonAlarm_1 : 2|1@1+ (1,0) [0|1] ""  HVESP01
 SG_ HVESP01_wakeReasonCan_1 : 1|1@1+ (1,0) [0|1] ""  HVESP01
 SG_ HVESP01_wakeReasonIgn_1 : 0|1@1+ (1,0) [0|1] ""  HVESP01

BO_ 2499748710 HVESP01_WakeReason_2: 1 HVESP01
 SG_ HVESP01_wakeReasonFailToSleep_2 : 3|1@1+ (1,0) [0|1] ""  HVESP01
 SG_ HVESP01_wakeReasonAlarm_2 : 2|1@1+ (1,0) [0|1] ""  HVESP01
 SG_ HVESP01_wakeReasonCan_2 : 1|1@1+ (1,0) [0|1] ""  HVESP01
 SG_ HVESP01_wakeReasonIgn_2 : 0|1@1+ (1,0) [0|1] ""  HVESP01

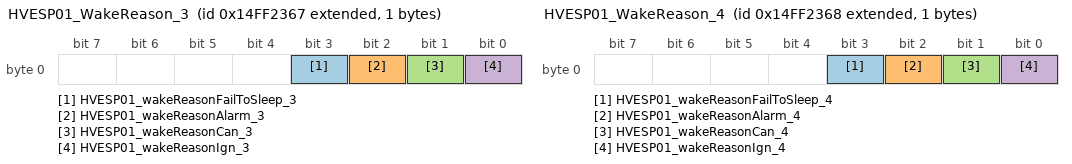
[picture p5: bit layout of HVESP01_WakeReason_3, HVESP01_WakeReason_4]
BO_ 2499748711 HVESP01_WakeReason_3: 1 HVESP01
 SG_ HVESP01_wakeReasonFailToSleep_3 : 3|1@1+ (1,0) [0|1] ""  HVESP01
 SG_ HVESP01_wakeReasonAlarm_3 : 2|1@1+ (1,0) [0|1] ""  HVESP01
 SG_ HVESP01_wakeReasonCan_3 : 1|1@1+ (1,0) [0|1] ""  HVESP01
 SG_ HVESP01_wakeReasonIgn_3 : 0|1@1+ (1,0) [0|1] ""  HVESP01

BO_ 2499748712 HVESP01_WakeReason_4: 1 HVESP01
 SG_ HVESP01_wakeReasonFailToSleep_4 : 3|1@1+ (1,0) [0|1] ""  HVESP01
 SG_ HVESP01_wakeReasonAlarm_4 : 2|1@1+ (1,0) [0|1] ""  HVESP01
 SG_ HVESP01_wakeReasonCan_4 : 1|1@1+ (1,0) [0|1] ""  HVESP01
 SG_ HVESP01_wakeReasonIgn_4 : 0|1@1+ (1,0) [0|1] ""  HVESP01

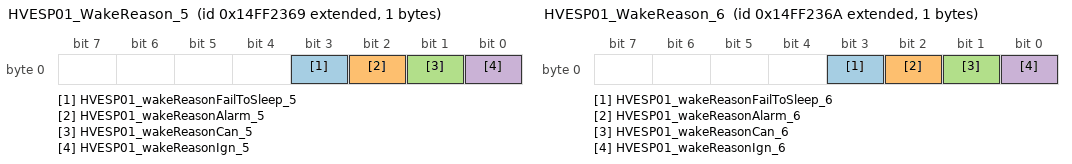
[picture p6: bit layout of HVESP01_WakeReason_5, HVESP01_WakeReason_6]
BO_ 2499748713 HVESP01_WakeReason_5: 1 HVESP01
 SG_ HVESP01_wakeReasonFailToSleep_5 : 3|1@1+ (1,0) [0|1] ""  HVESP01
 SG_ HVESP01_wakeReasonAlarm_5 : 2|1@1+ (1,0) [0|1] ""  HVESP01
 SG_ HVESP01_wakeReasonCan_5 : 1|1@1+ (1,0) [0|1] ""  HVESP01
 SG_ HVESP01_wakeReasonIgn_5 : 0|1@1+ (1,0) [0|1] ""  HVESP01

BO_ 2499748714 HVESP01_WakeReason_6: 1 HVESP01
 SG_ HVESP01_wakeReasonFailToSleep_6 : 3|1@1+ (1,0) [0|1] ""  HVESP01
 SG_ HVESP01_wakeReasonAlarm_6 : 2|1@1+ (1,0) [0|1] ""  HVESP01
 SG_ HVESP01_wakeReasonCan_6 : 1|1@1+ (1,0) [0|1] ""  HVESP01
 SG_ HVESP01_wakeReasonIgn_6 : 0|1@1+ (1,0) [0|1] ""  HVESP01

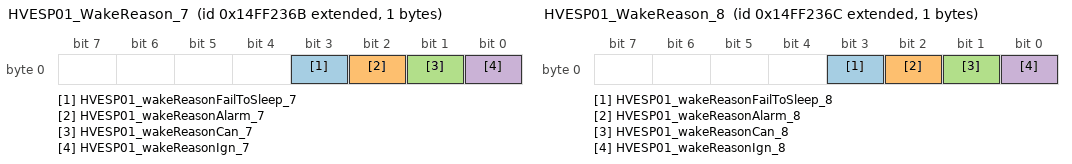
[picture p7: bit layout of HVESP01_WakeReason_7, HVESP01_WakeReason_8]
BO_ 2499748715 HVESP01_WakeReason_7: 1 HVESP01
 SG_ HVESP01_wakeReasonFailToSleep_7 : 3|1@1+ (1,0) [0|1] ""  HVESP01
 SG_ HVESP01_wakeReasonAlarm_7 : 2|1@1+ (1,0) [0|1] ""  HVESP01
 SG_ HVESP01_wakeReasonCan_7 : 1|1@1+ (1,0) [0|1] ""  HVESP01
 SG_ HVESP01_wakeReasonIgn_7 : 0|1@1+ (1,0) [0|1] ""  HVESP01

BO_ 2499748716 HVESP01_WakeReason_8: 1 HVESP01
 SG_ HVESP01_wakeReasonFailToSleep_8 : 3|1@1+ (1,0) [0|1] ""  HVESP01
 SG_ HVESP01_wakeReasonAlarm_8 : 2|1@1+ (1,0) [0|1] ""  HVESP01
 SG_ HVESP01_wakeReasonCan_8 : 1|1@1+ (1,0) [0|1] ""  HVESP01
 SG_ HVESP01_wakeReasonIgn_8 : 0|1@1+ (1,0) [0|1] ""  HVESP01

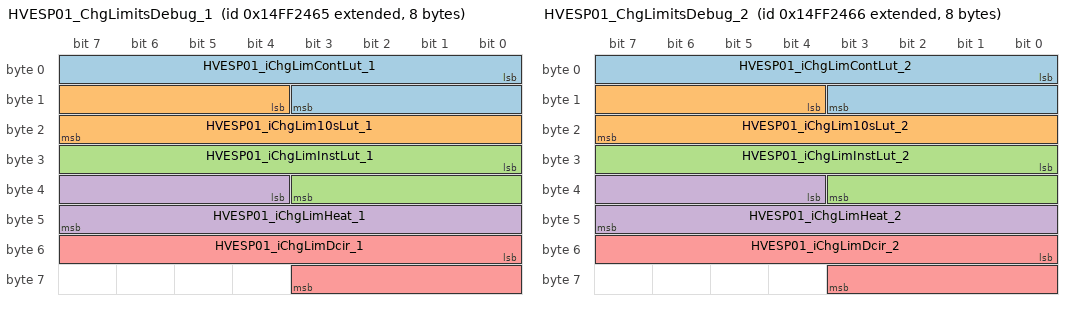
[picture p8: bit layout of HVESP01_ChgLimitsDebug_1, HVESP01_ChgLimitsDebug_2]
BO_ 2499748965 HVESP01_ChgLimitsDebug_1: 8 HVESP01
 SG_ HVESP01_iChgLimContLut_1 : 0|12@1+ (1,0) [0|4095] "A"  HVESP01
 SG_ HVESP01_iChgLim10sLut_1 : 12|12@1+ (1,0) [0|4095] "A"  HVESP01
 SG_ HVESP01_iChgLimInstLut_1 : 24|12@1+ (1,0) [0|4095] "A"  HVESP01
 SG_ HVESP01_iChgLimHeat_1 : 36|12@1+ (1,0) [0|4095] "A"  HVESP01
 SG_ HVESP01_iChgLimDcir_1 : 48|12@1+ (1,0) [0|4095] "A"  HVESP01

BO_ 2499748966 HVESP01_ChgLimitsDebug_2: 8 HVESP01
 SG_ HVESP01_iChgLimContLut_2 : 0|12@1+ (1,0) [0|4095] "A"  HVESP01
 SG_ HVESP01_iChgLim10sLut_2 : 12|12@1+ (1,0) [0|4095] "A"  HVESP01
 SG_ HVESP01_iChgLimInstLut_2 : 24|12@1+ (1,0) [0|4095] "A"  HVESP01
 SG_ HVESP01_iChgLimHeat_2 : 36|12@1+ (1,0) [0|4095] "A"  HVESP01
 SG_ HVESP01_iChgLimDcir_2 : 48|12@1+ (1,0) [0|4095] "A"  HVESP01

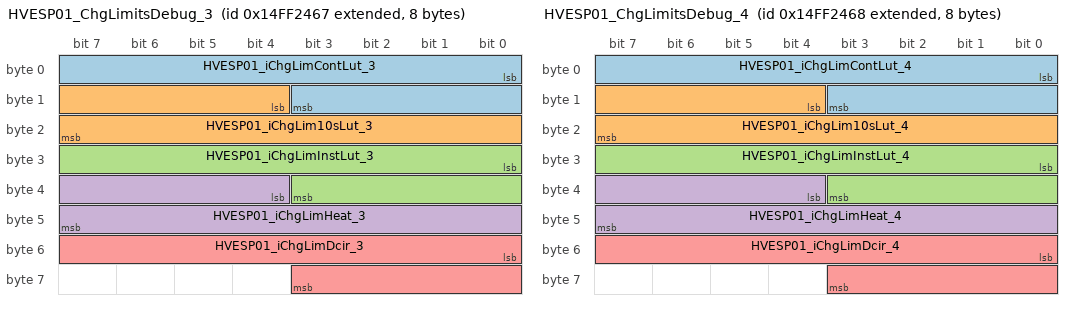
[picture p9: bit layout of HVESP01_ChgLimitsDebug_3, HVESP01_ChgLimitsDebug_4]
BO_ 2499748967 HVESP01_ChgLimitsDebug_3: 8 HVESP01
 SG_ HVESP01_iChgLimContLut_3 : 0|12@1+ (1,0) [0|4095] "A"  HVESP01
 SG_ HVESP01_iChgLim10sLut_3 : 12|12@1+ (1,0) [0|4095] "A"  HVESP01
 SG_ HVESP01_iChgLimInstLut_3 : 24|12@1+ (1,0) [0|4095] "A"  HVESP01
 SG_ HVESP01_iChgLimHeat_3 : 36|12@1+ (1,0) [0|4095] "A"  HVESP01
 SG_ HVESP01_iChgLimDcir_3 : 48|12@1+ (1,0) [0|4095] "A"  HVESP01

BO_ 2499748968 HVESP01_ChgLimitsDebug_4: 8 HVESP01
 SG_ HVESP01_iChgLimContLut_4 : 0|12@1+ (1,0) [0|4095] "A"  HVESP01
 SG_ HVESP01_iChgLim10sLut_4 : 12|12@1+ (1,0) [0|4095] "A"  HVESP01
 SG_ HVESP01_iChgLimInstLut_4 : 24|12@1+ (1,0) [0|4095] "A"  HVESP01
 SG_ HVESP01_iChgLimHeat_4 : 36|12@1+ (1,0) [0|4095] "A"  HVESP01
 SG_ HVESP01_iChgLimDcir_4 : 48|12@1+ (1,0) [0|4095] "A"  HVESP01

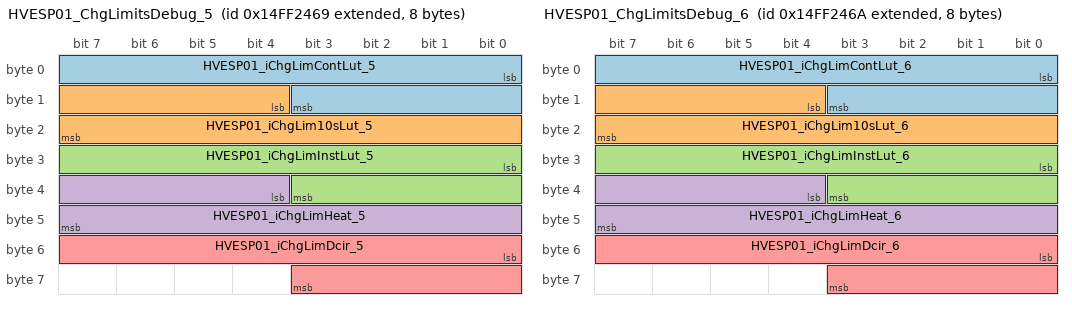
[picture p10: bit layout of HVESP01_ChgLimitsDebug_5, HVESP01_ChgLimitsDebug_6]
BO_ 2499748969 HVESP01_ChgLimitsDebug_5: 8 HVESP01
 SG_ HVESP01_iChgLimContLut_5 : 0|12@1+ (1,0) [0|4095] "A"  HVESP01
 SG_ HVESP01_iChgLim10sLut_5 : 12|12@1+ (1,0) [0|4095] "A"  HVESP01
 SG_ HVESP01_iChgLimInstLut_5 : 24|12@1+ (1,0) [0|4095] "A"  HVESP01
 SG_ HVESP01_iChgLimHeat_5 : 36|12@1+ (1,0) [0|4095] "A"  HVESP01
 SG_ HVESP01_iChgLimDcir_5 : 48|12@1+ (1,0) [0|4095] "A"  HVESP01

BO_ 2499748970 HVESP01_ChgLimitsDebug_6: 8 HVESP01
 SG_ HVESP01_iChgLimContLut_6 : 0|12@1+ (1,0) [0|4095] "A"  HVESP01
 SG_ HVESP01_iChgLim10sLut_6 : 12|12@1+ (1,0) [0|4095] "A"  HVESP01
 SG_ HVESP01_iChgLimInstLut_6 : 24|12@1+ (1,0) [0|4095] "A"  HVESP01
 SG_ HVESP01_iChgLimHeat_6 : 36|12@1+ (1,0) [0|4095] "A"  HVESP01
 SG_ HVESP01_iChgLimDcir_6 : 48|12@1+ (1,0) [0|4095] "A"  HVESP01

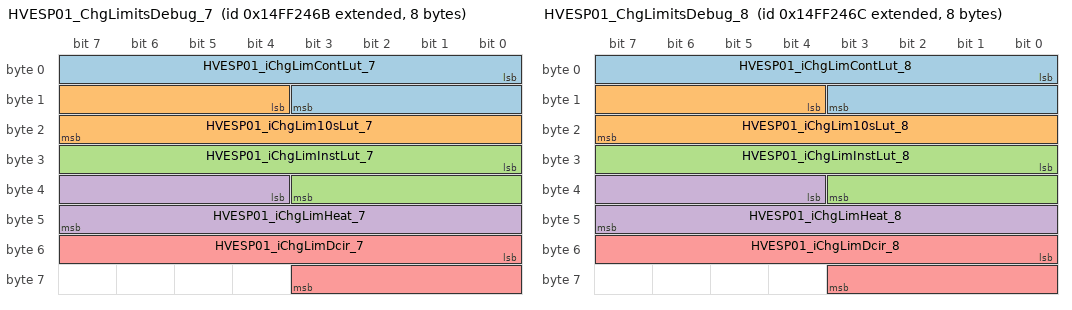
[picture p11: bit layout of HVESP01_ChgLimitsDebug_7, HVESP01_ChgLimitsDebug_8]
BO_ 2499748971 HVESP01_ChgLimitsDebug_7: 8 HVESP01
 SG_ HVESP01_iChgLimContLut_7 : 0|12@1+ (1,0) [0|4095] "A"  HVESP01
 SG_ HVESP01_iChgLim10sLut_7 : 12|12@1+ (1,0) [0|4095] "A"  HVESP01
 SG_ HVESP01_iChgLimInstLut_7 : 24|12@1+ (1,0) [0|4095] "A"  HVESP01
 SG_ HVESP01_iChgLimHeat_7 : 36|12@1+ (1,0) [0|4095] "A"  HVESP01
 SG_ HVESP01_iChgLimDcir_7 : 48|12@1+ (1,0) [0|4095] "A"  HVESP01

BO_ 2499748972 HVESP01_ChgLimitsDebug_8: 8 HVESP01
 SG_ HVESP01_iChgLimContLut_8 : 0|12@1+ (1,0) [0|4095] "A"  HVESP01
 SG_ HVESP01_iChgLim10sLut_8 : 12|12@1+ (1,0) [0|4095] "A"  HVESP01
 SG_ HVESP01_iChgLimInstLut_8 : 24|12@1+ (1,0) [0|4095] "A"  HVESP01
 SG_ HVESP01_iChgLimHeat_8 : 36|12@1+ (1,0) [0|4095] "A"  HVESP01
 SG_ HVESP01_iChgLimDcir_8 : 48|12@1+ (1,0) [0|4095] "A"  HVESP01

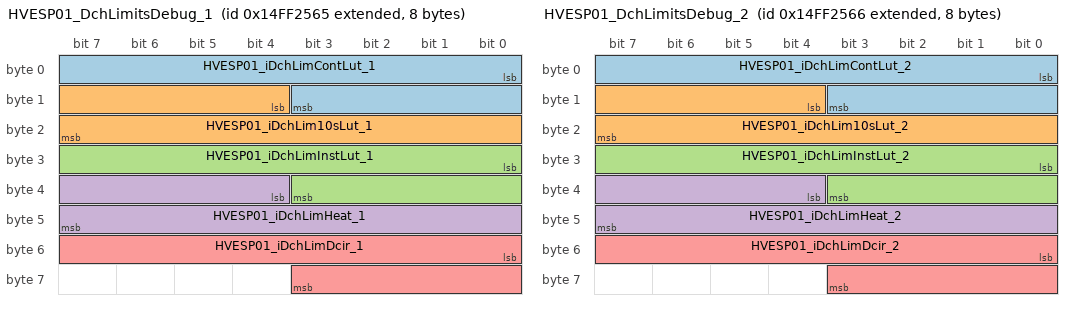
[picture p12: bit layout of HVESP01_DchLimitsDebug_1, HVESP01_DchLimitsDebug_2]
BO_ 2499749221 HVESP01_DchLimitsDebug_1: 8 HVESP01
 SG_ HVESP01_iDchLimContLut_1 : 0|12@1+ (1,0) [0|4095] "A"  HVESP01
 SG_ HVESP01_iDchLim10sLut_1 : 12|12@1+ (1,0) [0|4095] "A"  HVESP01
 SG_ HVESP01_iDchLimInstLut_1 : 24|12@1+ (1,0) [0|4095] "A"  HVESP01
 SG_ HVESP01_iDchLimHeat_1 : 36|12@1+ (1,0) [0|4095] "A"  HVESP01
 SG_ HVESP01_iDchLimDcir_1 : 48|12@1+ (1,0) [0|4095] "A"  HVESP01

BO_ 2499749222 HVESP01_DchLimitsDebug_2: 8 HVESP01
 SG_ HVESP01_iDchLimContLut_2 : 0|12@1+ (1,0) [0|4095] "A"  HVESP01
 SG_ HVESP01_iDchLim10sLut_2 : 12|12@1+ (1,0) [0|4095] "A"  HVESP01
 SG_ HVESP01_iDchLimInstLut_2 : 24|12@1+ (1,0) [0|4095] "A"  HVESP01
 SG_ HVESP01_iDchLimHeat_2 : 36|12@1+ (1,0) [0|4095] "A"  HVESP01
 SG_ HVESP01_iDchLimDcir_2 : 48|12@1+ (1,0) [0|4095] "A"  HVESP01

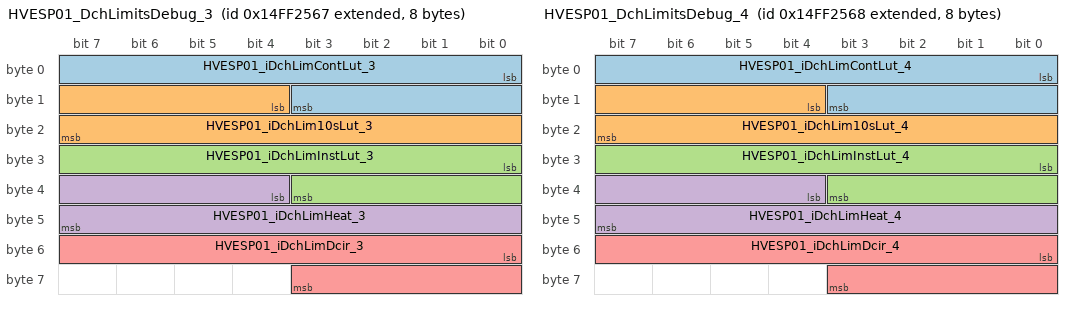
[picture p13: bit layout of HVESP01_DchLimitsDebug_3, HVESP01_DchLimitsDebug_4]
BO_ 2499749223 HVESP01_DchLimitsDebug_3: 8 HVESP01
 SG_ HVESP01_iDchLimContLut_3 : 0|12@1+ (1,0) [0|4095] "A"  HVESP01
 SG_ HVESP01_iDchLim10sLut_3 : 12|12@1+ (1,0) [0|4095] "A"  HVESP01
 SG_ HVESP01_iDchLimInstLut_3 : 24|12@1+ (1,0) [0|4095] "A"  HVESP01
 SG_ HVESP01_iDchLimHeat_3 : 36|12@1+ (1,0) [0|4095] "A"  HVESP01
 SG_ HVESP01_iDchLimDcir_3 : 48|12@1+ (1,0) [0|4095] "A"  HVESP01

BO_ 2499749224 HVESP01_DchLimitsDebug_4: 8 HVESP01
 SG_ HVESP01_iDchLimContLut_4 : 0|12@1+ (1,0) [0|4095] "A"  HVESP01
 SG_ HVESP01_iDchLim10sLut_4 : 12|12@1+ (1,0) [0|4095] "A"  HVESP01
 SG_ HVESP01_iDchLimInstLut_4 : 24|12@1+ (1,0) [0|4095] "A"  HVESP01
 SG_ HVESP01_iDchLimHeat_4 : 36|12@1+ (1,0) [0|4095] "A"  HVESP01
 SG_ HVESP01_iDchLimDcir_4 : 48|12@1+ (1,0) [0|4095] "A"  HVESP01

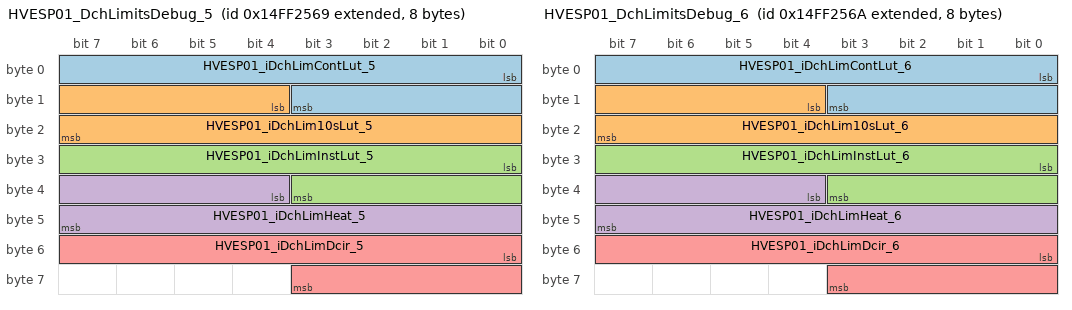
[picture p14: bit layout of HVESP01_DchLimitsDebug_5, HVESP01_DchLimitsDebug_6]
BO_ 2499749225 HVESP01_DchLimitsDebug_5: 8 HVESP01
 SG_ HVESP01_iDchLimContLut_5 : 0|12@1+ (1,0) [0|4095] "A"  HVESP01
 SG_ HVESP01_iDchLim10sLut_5 : 12|12@1+ (1,0) [0|4095] "A"  HVESP01
 SG_ HVESP01_iDchLimInstLut_5 : 24|12@1+ (1,0) [0|4095] "A"  HVESP01
 SG_ HVESP01_iDchLimHeat_5 : 36|12@1+ (1,0) [0|4095] "A"  HVESP01
 SG_ HVESP01_iDchLimDcir_5 : 48|12@1+ (1,0) [0|4095] "A"  HVESP01

BO_ 2499749226 HVESP01_DchLimitsDebug_6: 8 HVESP01
 SG_ HVESP01_iDchLimContLut_6 : 0|12@1+ (1,0) [0|4095] "A"  HVESP01
 SG_ HVESP01_iDchLim10sLut_6 : 12|12@1+ (1,0) [0|4095] "A"  HVESP01
 SG_ HVESP01_iDchLimInstLut_6 : 24|12@1+ (1,0) [0|4095] "A"  HVESP01
 SG_ HVESP01_iDchLimHeat_6 : 36|12@1+ (1,0) [0|4095] "A"  HVESP01
 SG_ HVESP01_iDchLimDcir_6 : 48|12@1+ (1,0) [0|4095] "A"  HVESP01

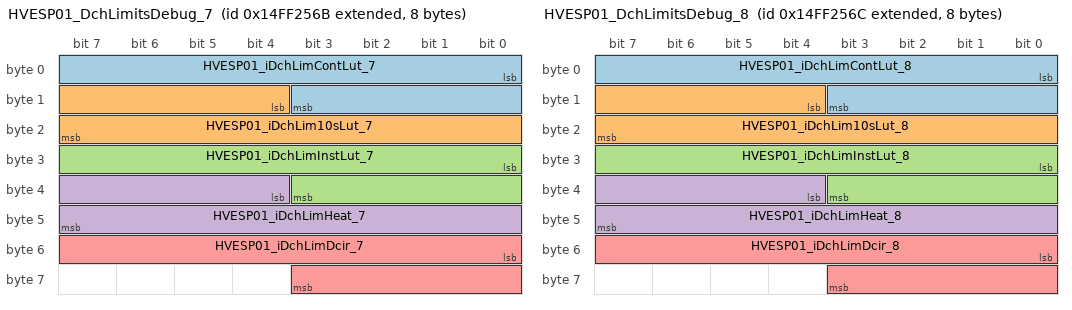
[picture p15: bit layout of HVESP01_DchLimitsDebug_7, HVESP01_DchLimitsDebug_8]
BO_ 2499749227 HVESP01_DchLimitsDebug_7: 8 HVESP01
 SG_ HVESP01_iDchLimContLut_7 : 0|12@1+ (1,0) [0|4095] "A"  HVESP01
 SG_ HVESP01_iDchLim10sLut_7 : 12|12@1+ (1,0) [0|4095] "A"  HVESP01
 SG_ HVESP01_iDchLimInstLut_7 : 24|12@1+ (1,0) [0|4095] "A"  HVESP01
 SG_ HVESP01_iDchLimHeat_7 : 36|12@1+ (1,0) [0|4095] "A"  HVESP01
 SG_ HVESP01_iDchLimDcir_7 : 48|12@1+ (1,0) [0|4095] "A"  HVESP01

BO_ 2499749228 HVESP01_DchLimitsDebug_8: 8 HVESP01
 SG_ HVESP01_iDchLimContLut_8 : 0|12@1+ (1,0) [0|4095] "A"  HVESP01
 SG_ HVESP01_iDchLim10sLut_8 : 12|12@1+ (1,0) [0|4095] "A"  HVESP01
 SG_ HVESP01_iDchLimInstLut_8 : 24|12@1+ (1,0) [0|4095] "A"  HVESP01
 SG_ HVESP01_iDchLimHeat_8 : 36|12@1+ (1,0) [0|4095] "A"  HVESP01
 SG_ HVESP01_iDchLimDcir_8 : 48|12@1+ (1,0) [0|4095] "A"  HVESP01

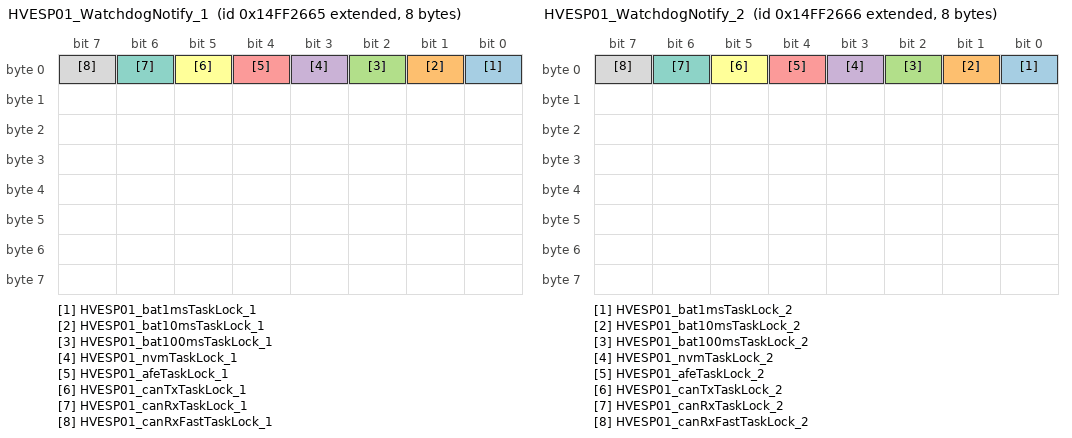
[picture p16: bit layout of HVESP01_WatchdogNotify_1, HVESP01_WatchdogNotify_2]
BO_ 2499749477 HVESP01_WatchdogNotify_1: 8 HVESP01
 SG_ HVESP01_bat1msTaskLock_1 : 0|1@1+ (1,0) [0|1] ""  HVESP01
 SG_ HVESP01_bat10msTaskLock_1 : 1|1@1+ (1,0) [0|1] ""  HVESP01
 SG_ HVESP01_bat100msTaskLock_1 : 2|1@1+ (1,0) [0|1] ""  HVESP01
 SG_ HVESP01_nvmTaskLock_1 : 3|1@1+ (1,0) [0|1] ""  HVESP01
 SG_ HVESP01_afeTaskLock_1 : 4|1@1+ (1,0) [0|1] ""  HVESP01
 SG_ HVESP01_canTxTaskLock_1 : 5|1@1+ (1,0) [0|1] ""  HVESP01
 SG_ HVESP01_canRxTaskLock_1 : 6|1@1+ (1,0) [0|1] ""  HVESP01
 SG_ HVESP01_canRxFastTaskLock_1 : 7|1@1+ (1,0) [0|1] ""  HVESP01

BO_ 2499749478 HVESP01_WatchdogNotify_2: 8 HVESP01
 SG_ HVESP01_bat1msTaskLock_2 : 0|1@1+ (1,0) [0|1] ""  HVESP01
 SG_ HVESP01_bat10msTaskLock_2 : 1|1@1+ (1,0) [0|1] ""  HVESP01
 SG_ HVESP01_bat100msTaskLock_2 : 2|1@1+ (1,0) [0|1] ""  HVESP01
 SG_ HVESP01_nvmTaskLock_2 : 3|1@1+ (1,0) [0|1] ""  HVESP01
 SG_ HVESP01_afeTaskLock_2 : 4|1@1+ (1,0) [0|1] ""  HVESP01
 SG_ HVESP01_canTxTaskLock_2 : 5|1@1+ (1,0) [0|1] ""  HVESP01
 SG_ HVESP01_canRxTaskLock_2 : 6|1@1+ (1,0) [0|1] ""  HVESP01
 SG_ HVESP01_canRxFastTaskLock_2 : 7|1@1+ (1,0) [0|1] ""  HVESP01

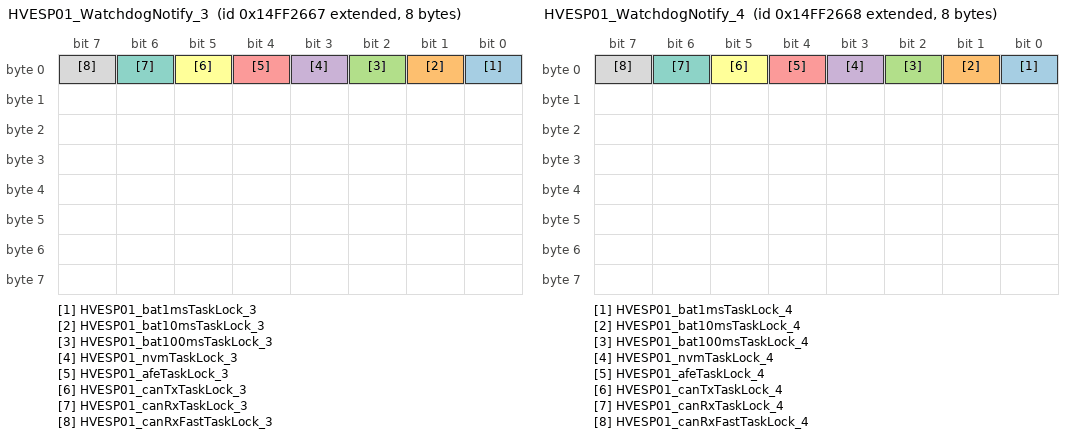
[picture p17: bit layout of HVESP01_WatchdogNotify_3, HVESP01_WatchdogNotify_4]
BO_ 2499749479 HVESP01_WatchdogNotify_3: 8 HVESP01
 SG_ HVESP01_bat1msTaskLock_3 : 0|1@1+ (1,0) [0|1] ""  HVESP01
 SG_ HVESP01_bat10msTaskLock_3 : 1|1@1+ (1,0) [0|1] ""  HVESP01
 SG_ HVESP01_bat100msTaskLock_3 : 2|1@1+ (1,0) [0|1] ""  HVESP01
 SG_ HVESP01_nvmTaskLock_3 : 3|1@1+ (1,0) [0|1] ""  HVESP01
 SG_ HVESP01_afeTaskLock_3 : 4|1@1+ (1,0) [0|1] ""  HVESP01
 SG_ HVESP01_canTxTaskLock_3 : 5|1@1+ (1,0) [0|1] ""  HVESP01
 SG_ HVESP01_canRxTaskLock_3 : 6|1@1+ (1,0) [0|1] ""  HVESP01
 SG_ HVESP01_canRxFastTaskLock_3 : 7|1@1+ (1,0) [0|1] ""  HVESP01

BO_ 2499749480 HVESP01_WatchdogNotify_4: 8 HVESP01
 SG_ HVESP01_bat1msTaskLock_4 : 0|1@1+ (1,0) [0|1] ""  HVESP01
 SG_ HVESP01_bat10msTaskLock_4 : 1|1@1+ (1,0) [0|1] ""  HVESP01
 SG_ HVESP01_bat100msTaskLock_4 : 2|1@1+ (1,0) [0|1] ""  HVESP01
 SG_ HVESP01_nvmTaskLock_4 : 3|1@1+ (1,0) [0|1] ""  HVESP01
 SG_ HVESP01_afeTaskLock_4 : 4|1@1+ (1,0) [0|1] ""  HVESP01
 SG_ HVESP01_canTxTaskLock_4 : 5|1@1+ (1,0) [0|1] ""  HVESP01
 SG_ HVESP01_canRxTaskLock_4 : 6|1@1+ (1,0) [0|1] ""  HVESP01
 SG_ HVESP01_canRxFastTaskLock_4 : 7|1@1+ (1,0) [0|1] ""  HVESP01

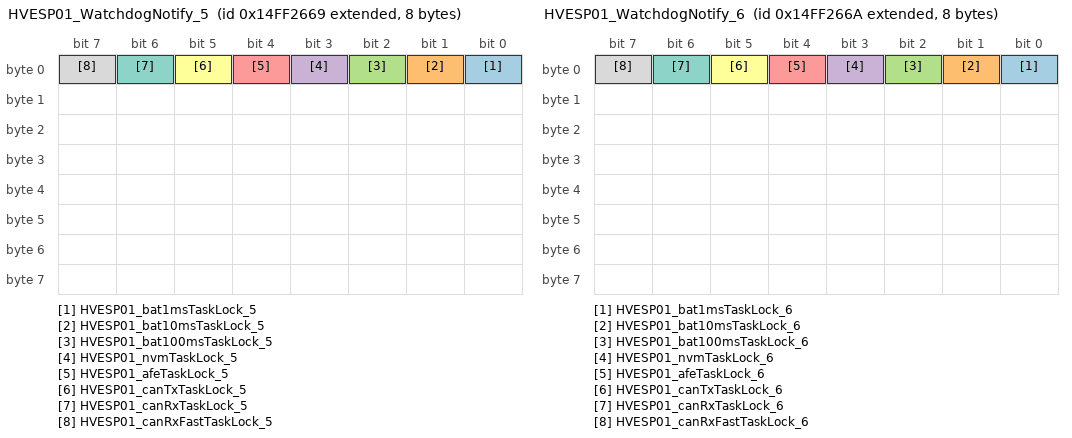
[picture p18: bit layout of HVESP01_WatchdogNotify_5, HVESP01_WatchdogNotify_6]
BO_ 2499749481 HVESP01_WatchdogNotify_5: 8 HVESP01
 SG_ HVESP01_bat1msTaskLock_5 : 0|1@1+ (1,0) [0|1] ""  HVESP01
 SG_ HVESP01_bat10msTaskLock_5 : 1|1@1+ (1,0) [0|1] ""  HVESP01
 SG_ HVESP01_bat100msTaskLock_5 : 2|1@1+ (1,0) [0|1] ""  HVESP01
 SG_ HVESP01_nvmTaskLock_5 : 3|1@1+ (1,0) [0|1] ""  HVESP01
 SG_ HVESP01_afeTaskLock_5 : 4|1@1+ (1,0) [0|1] ""  HVESP01
 SG_ HVESP01_canTxTaskLock_5 : 5|1@1+ (1,0) [0|1] ""  HVESP01
 SG_ HVESP01_canRxTaskLock_5 : 6|1@1+ (1,0) [0|1] ""  HVESP01
 SG_ HVESP01_canRxFastTaskLock_5 : 7|1@1+ (1,0) [0|1] ""  HVESP01

BO_ 2499749482 HVESP01_WatchdogNotify_6: 8 HVESP01
 SG_ HVESP01_bat1msTaskLock_6 : 0|1@1+ (1,0) [0|1] ""  HVESP01
 SG_ HVESP01_bat10msTaskLock_6 : 1|1@1+ (1,0) [0|1] ""  HVESP01
 SG_ HVESP01_bat100msTaskLock_6 : 2|1@1+ (1,0) [0|1] ""  HVESP01
 SG_ HVESP01_nvmTaskLock_6 : 3|1@1+ (1,0) [0|1] ""  HVESP01
 SG_ HVESP01_afeTaskLock_6 : 4|1@1+ (1,0) [0|1] ""  HVESP01
 SG_ HVESP01_canTxTaskLock_6 : 5|1@1+ (1,0) [0|1] ""  HVESP01
 SG_ HVESP01_canRxTaskLock_6 : 6|1@1+ (1,0) [0|1] ""  HVESP01
 SG_ HVESP01_canRxFastTaskLock_6 : 7|1@1+ (1,0) [0|1] ""  HVESP01

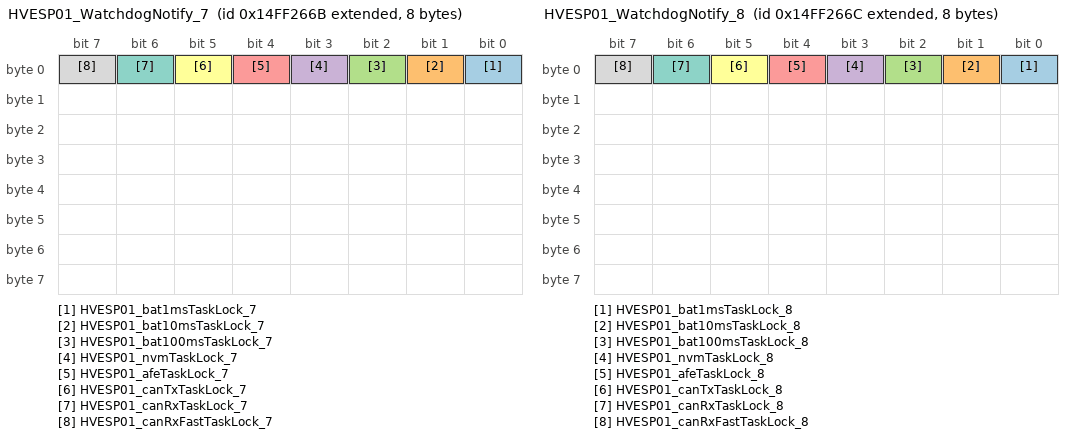
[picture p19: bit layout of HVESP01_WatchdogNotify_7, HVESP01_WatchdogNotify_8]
BO_ 2499749483 HVESP01_WatchdogNotify_7: 8 HVESP01
 SG_ HVESP01_bat1msTaskLock_7 : 0|1@1+ (1,0) [0|1] ""  HVESP01
 SG_ HVESP01_bat10msTaskLock_7 : 1|1@1+ (1,0) [0|1] ""  HVESP01
 SG_ HVESP01_bat100msTaskLock_7 : 2|1@1+ (1,0) [0|1] ""  HVESP01
 SG_ HVESP01_nvmTaskLock_7 : 3|1@1+ (1,0) [0|1] ""  HVESP01
 SG_ HVESP01_afeTaskLock_7 : 4|1@1+ (1,0) [0|1] ""  HVESP01
 SG_ HVESP01_canTxTaskLock_7 : 5|1@1+ (1,0) [0|1] ""  HVESP01
 SG_ HVESP01_canRxTaskLock_7 : 6|1@1+ (1,0) [0|1] ""  HVESP01
 SG_ HVESP01_canRxFastTaskLock_7 : 7|1@1+ (1,0) [0|1] ""  HVESP01

BO_ 2499749484 HVESP01_WatchdogNotify_8: 8 HVESP01
 SG_ HVESP01_bat1msTaskLock_8 : 0|1@1+ (1,0) [0|1] ""  HVESP01
 SG_ HVESP01_bat10msTaskLock_8 : 1|1@1+ (1,0) [0|1] ""  HVESP01
 SG_ HVESP01_bat100msTaskLock_8 : 2|1@1+ (1,0) [0|1] ""  HVESP01
 SG_ HVESP01_nvmTaskLock_8 : 3|1@1+ (1,0) [0|1] ""  HVESP01
 SG_ HVESP01_afeTaskLock_8 : 4|1@1+ (1,0) [0|1] ""  HVESP01
 SG_ HVESP01_canTxTaskLock_8 : 5|1@1+ (1,0) [0|1] ""  HVESP01
 SG_ HVESP01_canRxTaskLock_8 : 6|1@1+ (1,0) [0|1] ""  HVESP01
 SG_ HVESP01_canRxFastTaskLock_8 : 7|1@1+ (1,0) [0|1] ""  HVESP01

BA_DEF_ BO_  "GenMsgDiag" ENUM "No","Yes";
BA_DEF_ BO_  "GenMsgInstanced" STRING ;
BA_DEF_ SG_  "SigType" ENUM "Default","Range","RangeSigned","ASCII","Discrete","Control","ReferencePGN","DTC","StringDelimiter","StringLength","StringLengthControl","MessageCounter","MessageChecksum";
BA_DEF_ SG_  "GenSigEVName" STRING ;
BA_DEF_ SG_  "GenSigILSupport" ENUM "No","Yes";
BA_DEF_ SG_  "GenSigSendType" ENUM "Cyclic","OnWrite","OnWriteWithRepetition","OnChange","OnChangeWithRepetition","IfActive","IfActiveWithRepetition","NoSigSendType";
BA_DEF_ BO_  "GenMsgILSupport" ENUM "No","Yes";
BA_DEF_ BO_  "GenMsgSendType" ENUM "cyclic","NotUsed","IfActive","NotUsed","NotUsed","NotUsed","NotUsed","NotUsed","noMsgSendType";
BA_DEF_ BO_  "GenMsgRequestable" INT 0 1;
BA_DEF_ BO_  "GenMsgCycleTime" INT 0 3600000;
BA_DEF_ BO_  "VFrameFormat" ENUM "StandardCAN","ExtendedCAN","reserved","J1939PG";
BA_DEF_ SG_  "SystemSignalLongSymbol" STRING ;
BA_DEF_DEF_  "GenMsgDiag" "No";
BA_DEF_DEF_  "GenMsgInstanced" "No";
BA_DEF_DEF_  "SigType" "Default";
BA_DEF_DEF_  "GenSigEVName" "Env@Nodename_@Signame";
BA_DEF_DEF_  "GenSigILSupport" "Yes";
BA_DEF_DEF_  "GenSigSendType" "NoSigSendType";
BA_DEF_DEF_  "GenMsgILSupport" "Yes";
BA_DEF_DEF_  "GenMsgSendType" "noMsgSendType";
BA_DEF_DEF_  "GenMsgRequestable" 1;
BA_DEF_DEF_  "GenMsgCycleTime" 0;
BA_DEF_DEF_  "VFrameFormat" "J1939PG";
BA_DEF_DEF_  "SystemSignalLongSymbol" "";
BA_ "GenMsgDiag" BO_ 2499748197 1;
BA_ "GenMsgDiag" BO_ 2499748198 1;
BA_ "GenMsgDiag" BO_ 2499748199 1;
BA_ "GenMsgDiag" BO_ 2499748200 1;
BA_ "GenMsgDiag" BO_ 2499748201 1;
BA_ "GenMsgDiag" BO_ 2499748202 1;
BA_ "GenMsgDiag" BO_ 2499748203 1;
BA_ "GenMsgDiag" BO_ 2499748204 1;
BA_ "GenMsgDiag" BO_ 2499748453 1;
BA_ "GenMsgDiag" BO_ 2499748454 1;
BA_ "GenMsgDiag" BO_ 2499748455 1;
BA_ "GenMsgDiag" BO_ 2499748456 1;
BA_ "GenMsgDiag" BO_ 2499748457 1;
BA_ "GenMsgDiag" BO_ 2499748458 1;
BA_ "GenMsgDiag" BO_ 2499748459 1;
BA_ "GenMsgDiag" BO_ 2499748460 1;
BA_ "GenMsgDiag" BO_ 2499748709 1;
BA_ "GenMsgDiag" BO_ 2499748710 1;
BA_ "GenMsgDiag" BO_ 2499748711 1;
BA_ "GenMsgDiag" BO_ 2499748712 1;
BA_ "GenMsgDiag" BO_ 2499748713 1;
BA_ "GenMsgDiag" BO_ 2499748714 1;
BA_ "GenMsgDiag" BO_ 2499748715 1;
BA_ "GenMsgDiag" BO_ 2499748716 1;
BA_ "GenMsgDiag" BO_ 2499748965 1;
BA_ "GenMsgDiag" BO_ 2499748966 1;
BA_ "GenMsgDiag" BO_ 2499748967 1;
BA_ "GenMsgDiag" BO_ 2499748968 1;
BA_ "GenMsgDiag" BO_ 2499748969 1;
BA_ "GenMsgDiag" BO_ 2499748970 1;
BA_ "GenMsgDiag" BO_ 2499748971 1;
BA_ "GenMsgDiag" BO_ 2499748972 1;
BA_ "GenMsgDiag" BO_ 2499749221 1;
BA_ "GenMsgDiag" BO_ 2499749222 1;
BA_ "GenMsgDiag" BO_ 2499749223 1;
BA_ "GenMsgDiag" BO_ 2499749224 1;
BA_ "GenMsgDiag" BO_ 2499749225 1;
BA_ "GenMsgDiag" BO_ 2499749226 1;
BA_ "GenMsgDiag" BO_ 2499749227 1;
BA_ "GenMsgDiag" BO_ 2499749228 1;
BA_ "GenMsgInstanced" BO_ 2499743845 "False";
BA_ "GenMsgInstanced" BO_ 2499743846 "False";
BA_ "GenMsgInstanced" BO_ 2499743847 "False";
BA_ "GenMsgInstanced" BO_ 2499743848 "False";
BA_ "GenMsgInstanced" BO_ 2499743849 "False";
BA_ "GenMsgInstanced" BO_ 2499743850 "False";
BA_ "GenMsgInstanced" BO_ 2499743851 "False";
BA_ "GenMsgInstanced" BO_ 2499743852 "False";
BA_ "GenMsgInstanced" BO_ 2499744101 "False";
BA_ "GenMsgInstanced" BO_ 2499744102 "False";
BA_ "GenMsgInstanced" BO_ 2499744103 "False";
BA_ "GenMsgInstanced" BO_ 2499744104 "False";
BA_ "GenMsgInstanced" BO_ 2499744105 "False";
BA_ "GenMsgInstanced" BO_ 2499744106 "False";
BA_ "GenMsgInstanced" BO_ 2499744107 "False";
BA_ "GenMsgInstanced" BO_ 2499744108 "False";
BA_ "GenMsgInstanced" BO_ 2499744357 "False";
BA_ "GenMsgInstanced" BO_ 2499744358 "False";
BA_ "GenMsgInstanced" BO_ 2499744359 "False";
BA_ "GenMsgInstanced" BO_ 2499744360 "False";
BA_ "GenMsgInstanced" BO_ 2499744361 "False";
BA_ "GenMsgInstanced" BO_ 2499744362 "False";
BA_ "GenMsgInstanced" BO_ 2499744363 "False";
BA_ "GenMsgInstanced" BO_ 2499744364 "False";
BA_ "GenMsgInstanced" BO_ 2499744613 "False";
BA_ "GenMsgInstanced" BO_ 2499744614 "False";
BA_ "GenMsgInstanced" BO_ 2499744615 "False";
BA_ "GenMsgInstanced" BO_ 2499744616 "False";
BA_ "GenMsgInstanced" BO_ 2499744617 "False";
BA_ "GenMsgInstanced" BO_ 2499744618 "False";
BA_ "GenMsgInstanced" BO_ 2499744619 "False";
BA_ "GenMsgInstanced" BO_ 2499744620 "False";
BA_ "GenMsgInstanced" BO_ 2499744869 "False";
BA_ "GenMsgInstanced" BO_ 2499744870 "False";
BA_ "GenMsgInstanced" BO_ 2499744871 "False";
BA_ "GenMsgInstanced" BO_ 2499744872 "False";
BA_ "GenMsgInstanced" BO_ 2499744873 "False";
BA_ "GenMsgInstanced" BO_ 2499744874 "False";
BA_ "GenMsgInstanced" BO_ 2499744875 "False";
BA_ "GenMsgInstanced" BO_ 2499744876 "False";
BA_ "GenMsgInstanced" BO_ 2499745125 "False";
BA_ "GenMsgInstanced" BO_ 2499745126 "False";
BA_ "GenMsgInstanced" BO_ 2499745127 "False";
BA_ "GenMsgInstanced" BO_ 2499745128 "False";
BA_ "GenMsgInstanced" BO_ 2499745129 "False";
BA_ "GenMsgInstanced" BO_ 2499745130 "False";
BA_ "GenMsgInstanced" BO_ 2499745131 "False";
BA_ "GenMsgInstanced" BO_ 2499745132 "False";
BA_ "GenMsgInstanced" BO_ 2499745381 "False";
BA_ "GenMsgInstanced" BO_ 2499745382 "False";
BA_ "GenMsgInstanced" BO_ 2499745383 "False";
BA_ "GenMsgInstanced" BO_ 2499745384 "False";
BA_ "GenMsgInstanced" BO_ 2499745385 "False";
BA_ "GenMsgInstanced" BO_ 2499745386 "False";
BA_ "GenMsgInstanced" BO_ 2499745387 "False";
BA_ "GenMsgInstanced" BO_ 2499745388 "False";
BA_ "GenMsgInstanced" BO_ 2499745637 "False";
BA_ "GenMsgInstanced" BO_ 2499745638 "False";
BA_ "GenMsgInstanced" BO_ 2499745639 "False";
BA_ "GenMsgInstanced" BO_ 2499745640 "False";
BA_ "GenMsgInstanced" BO_ 2499745641 "False";
BA_ "GenMsgInstanced" BO_ 2499745642 "False";
BA_ "GenMsgInstanced" BO_ 2499745643 "False";
BA_ "GenMsgInstanced" BO_ 2499745644 "False";
BA_ "GenMsgInstanced" BO_ 2499745893 "False";
BA_ "GenMsgInstanced" BO_ 2499745894 "False";
BA_ "GenMsgInstanced" BO_ 2499745895 "False";
BA_ "GenMsgInstanced" BO_ 2499745896 "False";
BA_ "GenMsgInstanced" BO_ 2499745897 "False";
BA_ "GenMsgInstanced" BO_ 2499745898 "False";
BA_ "GenMsgInstanced" BO_ 2499745899 "False";
BA_ "GenMsgInstanced" BO_ 2499745900 "False";
BA_ "GenMsgInstanced" BO_ 2499746149 "False";
BA_ "GenMsgInstanced" BO_ 2499746150 "False";
BA_ "GenMsgInstanced" BO_ 2499746151 "False";
BA_ "GenMsgInstanced" BO_ 2499746152 "False";
BA_ "GenMsgInstanced" BO_ 2499746153 "False";
BA_ "GenMsgInstanced" BO_ 2499746154 "False";
BA_ "GenMsgInstanced" BO_ 2499746155 "False";
BA_ "GenMsgInstanced" BO_ 2499746156 "False";
BA_ "GenMsgInstanced" BO_ 2499747941 "False";
BA_ "GenMsgInstanced" BO_ 2499747942 "False";
BA_ "GenMsgInstanced" BO_ 2499747943 "False";
BA_ "GenMsgInstanced" BO_ 2499747944 "False";
BA_ "GenMsgInstanced" BO_ 2499747945 "False";
BA_ "GenMsgInstanced" BO_ 2499747946 "False";
BA_ "GenMsgInstanced" BO_ 2499747947 "False";
BA_ "GenMsgInstanced" BO_ 2499747948 "False";
BA_ "GenMsgInstanced" BO_ 2499748197 "False";
BA_ "GenMsgInstanced" BO_ 2499748198 "False";
BA_ "GenMsgInstanced" BO_ 2499748199 "False";
BA_ "GenMsgInstanced" BO_ 2499748200 "False";
BA_ "GenMsgInstanced" BO_ 2499748201 "False";
BA_ "GenMsgInstanced" BO_ 2499748202 "False";
BA_ "GenMsgInstanced" BO_ 2499748203 "False";
BA_ "GenMsgInstanced" BO_ 2499748204 "False";
BA_ "GenMsgInstanced" BO_ 2499748453 "False";
BA_ "GenMsgInstanced" BO_ 2499748454 "False";
BA_ "GenMsgInstanced" BO_ 2499748455 "False";
BA_ "GenMsgInstanced" BO_ 2499748456 "False";
BA_ "GenMsgInstanced" BO_ 2499748457 "False";
BA_ "GenMsgInstanced" BO_ 2499748458 "False";
BA_ "GenMsgInstanced" BO_ 2499748459 "False";
BA_ "GenMsgInstanced" BO_ 2499748460 "False";
BA_ "GenMsgInstanced" BO_ 2499748709 "False";
BA_ "GenMsgInstanced" BO_ 2499748710 "False";
BA_ "GenMsgInstanced" BO_ 2499748711 "False";
BA_ "GenMsgInstanced" BO_ 2499748712 "False";
BA_ "GenMsgInstanced" BO_ 2499748713 "False";
BA_ "GenMsgInstanced" BO_ 2499748714 "False";
BA_ "GenMsgInstanced" BO_ 2499748715 "False";
BA_ "GenMsgInstanced" BO_ 2499748716 "False";
BA_ "GenMsgInstanced" BO_ 2499748965 "False";
BA_ "GenMsgInstanced" BO_ 2499748966 "False";
BA_ "GenMsgInstanced" BO_ 2499748967 "False";
BA_ "GenMsgInstanced" BO_ 2499748968 "False";
BA_ "GenMsgInstanced" BO_ 2499748969 "False";
BA_ "GenMsgInstanced" BO_ 2499748970 "False";
BA_ "GenMsgInstanced" BO_ 2499748971 "False";
BA_ "GenMsgInstanced" BO_ 2499748972 "False";
BA_ "GenMsgInstanced" BO_ 2499749221 "False";
BA_ "GenMsgInstanced" BO_ 2499749222 "False";
BA_ "GenMsgInstanced" BO_ 2499749223 "False";
BA_ "GenMsgInstanced" BO_ 2499749224 "False";
BA_ "GenMsgInstanced" BO_ 2499749225 "False";
BA_ "GenMsgInstanced" BO_ 2499749226 "False";
BA_ "GenMsgInstanced" BO_ 2499749227 "False";
BA_ "GenMsgInstanced" BO_ 2499749228 "False";
BA_ "GenMsgInstanced" BO_ 2499749477 "False";
BA_ "GenMsgInstanced" BO_ 2499749478 "False";
BA_ "GenMsgInstanced" BO_ 2499749479 "False";
BA_ "GenMsgInstanced" BO_ 2499749480 "False";
BA_ "GenMsgInstanced" BO_ 2499749481 "False";
BA_ "GenMsgInstanced" BO_ 2499749482 "False";
BA_ "GenMsgInstanced" BO_ 2499749483 "False";
BA_ "GenMsgInstanced" BO_ 2499749484 "False";
BA_ "GenMsgSendType" BO_ 2499743845 0;
BA_ "GenMsgSendType" BO_ 2499743846 0;
BA_ "GenMsgSendType" BO_ 2499743847 0;
BA_ "GenMsgSendType" BO_ 2499743848 0;
BA_ "GenMsgSendType" BO_ 2499743849 0;
BA_ "GenMsgSendType" BO_ 2499743850 0;
BA_ "GenMsgSendType" BO_ 2499743851 0;
BA_ "GenMsgSendType" BO_ 2499743852 0;
BA_ "GenMsgSendType" BO_ 2499744101 0;
BA_ "GenMsgSendType" BO_ 2499744102 0;
BA_ "GenMsgSendType" BO_ 2499744103 0;
BA_ "GenMsgSendType" BO_ 2499744104 0;
BA_ "GenMsgSendType" BO_ 2499744105 0;
BA_ "GenMsgSendType" BO_ 2499744106 0;
BA_ "GenMsgSendType" BO_ 2499744107 0;
BA_ "GenMsgSendType" BO_ 2499744108 0;
BA_ "GenMsgSendType" BO_ 2499744357 0;
BA_ "GenMsgSendType" BO_ 2499744358 0;
BA_ "GenMsgSendType" BO_ 2499744359 0;
BA_ "GenMsgSendType" BO_ 2499744360 0;
BA_ "GenMsgSendType" BO_ 2499744361 0;
BA_ "GenMsgSendType" BO_ 2499744362 0;
BA_ "GenMsgSendType" BO_ 2499744363 0;
BA_ "GenMsgSendType" BO_ 2499744364 0;
BA_ "GenMsgSendType" BO_ 2499744613 0;
BA_ "GenMsgSendType" BO_ 2499744614 0;
BA_ "GenMsgSendType" BO_ 2499744615 0;
BA_ "GenMsgSendType" BO_ 2499744616 0;
BA_ "GenMsgSendType" BO_ 2499744617 0;
BA_ "GenMsgSendType" BO_ 2499744618 0;
BA_ "GenMsgSendType" BO_ 2499744619 0;
BA_ "GenMsgSendType" BO_ 2499744620 0;
BA_ "GenMsgSendType" BO_ 2499745125 0;
BA_ "GenMsgSendType" BO_ 2499745126 0;
BA_ "GenMsgSendType" BO_ 2499745127 0;
BA_ "GenMsgSendType" BO_ 2499745128 0;
BA_ "GenMsgSendType" BO_ 2499745129 0;
BA_ "GenMsgSendType" BO_ 2499745130 0;
BA_ "GenMsgSendType" BO_ 2499745131 0;
BA_ "GenMsgSendType" BO_ 2499745132 0;
BA_ "GenMsgSendType" BO_ 2499745381 0;
BA_ "GenMsgSendType" BO_ 2499745382 0;
BA_ "GenMsgSendType" BO_ 2499745383 0;
BA_ "GenMsgSendType" BO_ 2499745384 0;
BA_ "GenMsgSendType" BO_ 2499745385 0;
BA_ "GenMsgSendType" BO_ 2499745386 0;
BA_ "GenMsgSendType" BO_ 2499745387 0;
BA_ "GenMsgSendType" BO_ 2499745388 0;
BA_ "GenMsgSendType" BO_ 2499745637 0;
BA_ "GenMsgSendType" BO_ 2499745638 0;
BA_ "GenMsgSendType" BO_ 2499745639 0;
BA_ "GenMsgSendType" BO_ 2499745640 0;
BA_ "GenMsgSendType" BO_ 2499745641 0;
BA_ "GenMsgSendType" BO_ 2499745642 0;
BA_ "GenMsgSendType" BO_ 2499745643 0;
BA_ "GenMsgSendType" BO_ 2499745644 0;
BA_ "GenMsgSendType" BO_ 2499745893 0;
BA_ "GenMsgSendType" BO_ 2499745894 0;
BA_ "GenMsgSendType" BO_ 2499745895 0;
BA_ "GenMsgSendType" BO_ 2499745896 0;
BA_ "GenMsgSendType" BO_ 2499745897 0;
BA_ "GenMsgSendType" BO_ 2499745898 0;
BA_ "GenMsgSendType" BO_ 2499745899 0;
BA_ "GenMsgSendType" BO_ 2499745900 0;
BA_ "GenMsgSendType" BO_ 2499746149 0;
BA_ "GenMsgSendType" BO_ 2499746150 0;
BA_ "GenMsgSendType" BO_ 2499746151 0;
BA_ "GenMsgSendType" BO_ 2499746152 0;
BA_ "GenMsgSendType" BO_ 2499746153 0;
BA_ "GenMsgSendType" BO_ 2499746154 0;
BA_ "GenMsgSendType" BO_ 2499746155 0;
BA_ "GenMsgSendType" BO_ 2499746156 0;
BA_ "GenMsgSendType" BO_ 2499748965 0;
BA_ "GenMsgSendType" BO_ 2499748966 0;
BA_ "GenMsgSendType" BO_ 2499748967 0;
BA_ "GenMsgSendType" BO_ 2499748968 0;
BA_ "GenMsgSendType" BO_ 2499748969 0;
BA_ "GenMsgSendType" BO_ 2499748970 0;
BA_ "GenMsgSendType" BO_ 2499748971 0;
BA_ "GenMsgSendType" BO_ 2499748972 0;
BA_ "GenMsgSendType" BO_ 2499749221 0;
BA_ "GenMsgSendType" BO_ 2499749222 0;
BA_ "GenMsgSendType" BO_ 2499749223 0;
BA_ "GenMsgSendType" BO_ 2499749224 0;
BA_ "GenMsgSendType" BO_ 2499749225 0;
BA_ "GenMsgSendType" BO_ 2499749226 0;
BA_ "GenMsgSendType" BO_ 2499749227 0;
BA_ "GenMsgSendType" BO_ 2499749228 0;
BA_ "GenMsgCycleTime" BO_ 2499743845 200;
BA_ "GenMsgCycleTime" BO_ 2499743846 200;
BA_ "GenMsgCycleTime" BO_ 2499743847 200;
BA_ "GenMsgCycleTime" BO_ 2499743848 200;
BA_ "GenMsgCycleTime" BO_ 2499743849 200;
BA_ "GenMsgCycleTime" BO_ 2499743850 200;
BA_ "GenMsgCycleTime" BO_ 2499743851 200;
BA_ "GenMsgCycleTime" BO_ 2499743852 200;
BA_ "GenMsgCycleTime" BO_ 2499744101 200;
BA_ "GenMsgCycleTime" BO_ 2499744102 200;
BA_ "GenMsgCycleTime" BO_ 2499744103 200;
BA_ "GenMsgCycleTime" BO_ 2499744104 200;
BA_ "GenMsgCycleTime" BO_ 2499744105 200;
BA_ "GenMsgCycleTime" BO_ 2499744106 200;
BA_ "GenMsgCycleTime" BO_ 2499744107 200;
BA_ "GenMsgCycleTime" BO_ 2499744108 200;
BA_ "GenMsgCycleTime" BO_ 2499744357 200;
BA_ "GenMsgCycleTime" BO_ 2499744358 200;
BA_ "GenMsgCycleTime" BO_ 2499744359 200;
BA_ "GenMsgCycleTime" BO_ 2499744360 200;
BA_ "GenMsgCycleTime" BO_ 2499744361 200;
BA_ "GenMsgCycleTime" BO_ 2499744362 200;
BA_ "GenMsgCycleTime" BO_ 2499744363 200;
BA_ "GenMsgCycleTime" BO_ 2499744364 200;
BA_ "GenMsgCycleTime" BO_ 2499744613 200;
BA_ "GenMsgCycleTime" BO_ 2499744614 200;
BA_ "GenMsgCycleTime" BO_ 2499744615 200;
BA_ "GenMsgCycleTime" BO_ 2499744616 200;
BA_ "GenMsgCycleTime" BO_ 2499744617 200;
BA_ "GenMsgCycleTime" BO_ 2499744618 200;
BA_ "GenMsgCycleTime" BO_ 2499744619 200;
BA_ "GenMsgCycleTime" BO_ 2499744620 200;
BA_ "GenMsgCycleTime" BO_ 2499744869 100;
BA_ "GenMsgCycleTime" BO_ 2499744870 100;
BA_ "GenMsgCycleTime" BO_ 2499744871 100;
BA_ "GenMsgCycleTime" BO_ 2499744872 100;
BA_ "GenMsgCycleTime" BO_ 2499744873 100;
BA_ "GenMsgCycleTime" BO_ 2499744874 100;
BA_ "GenMsgCycleTime" BO_ 2499744875 100;
BA_ "GenMsgCycleTime" BO_ 2499744876 100;
BA_ "GenMsgCycleTime" BO_ 2499745125 200;
BA_ "GenMsgCycleTime" BO_ 2499745126 200;
BA_ "GenMsgCycleTime" BO_ 2499745127 200;
BA_ "GenMsgCycleTime" BO_ 2499745128 200;
BA_ "GenMsgCycleTime" BO_ 2499745129 200;
BA_ "GenMsgCycleTime" BO_ 2499745130 200;
BA_ "GenMsgCycleTime" BO_ 2499745131 200;
BA_ "GenMsgCycleTime" BO_ 2499745132 200;
BA_ "GenMsgCycleTime" BO_ 2499745381 200;
BA_ "GenMsgCycleTime" BO_ 2499745382 200;
BA_ "GenMsgCycleTime" BO_ 2499745383 200;
BA_ "GenMsgCycleTime" BO_ 2499745384 200;
BA_ "GenMsgCycleTime" BO_ 2499745385 200;
BA_ "GenMsgCycleTime" BO_ 2499745386 200;
BA_ "GenMsgCycleTime" BO_ 2499745387 200;
BA_ "GenMsgCycleTime" BO_ 2499745388 200;
BA_ "GenMsgCycleTime" BO_ 2499745637 200;
BA_ "GenMsgCycleTime" BO_ 2499745638 200;
BA_ "GenMsgCycleTime" BO_ 2499745639 200;
BA_ "GenMsgCycleTime" BO_ 2499745640 200;
BA_ "GenMsgCycleTime" BO_ 2499745641 200;
BA_ "GenMsgCycleTime" BO_ 2499745642 200;
BA_ "GenMsgCycleTime" BO_ 2499745643 200;
BA_ "GenMsgCycleTime" BO_ 2499745644 200;
BA_ "GenMsgCycleTime" BO_ 2499745893 200;
BA_ "GenMsgCycleTime" BO_ 2499745894 200;
BA_ "GenMsgCycleTime" BO_ 2499745895 200;
BA_ "GenMsgCycleTime" BO_ 2499745896 200;
BA_ "GenMsgCycleTime" BO_ 2499745897 200;
BA_ "GenMsgCycleTime" BO_ 2499745898 200;
BA_ "GenMsgCycleTime" BO_ 2499745899 200;
BA_ "GenMsgCycleTime" BO_ 2499745900 200;
BA_ "GenMsgCycleTime" BO_ 2499746149 200;
BA_ "GenMsgCycleTime" BO_ 2499746150 200;
BA_ "GenMsgCycleTime" BO_ 2499746151 200;
BA_ "GenMsgCycleTime" BO_ 2499746152 200;
BA_ "GenMsgCycleTime" BO_ 2499746153 200;
BA_ "GenMsgCycleTime" BO_ 2499746154 200;
BA_ "GenMsgCycleTime" BO_ 2499746155 200;
BA_ "GenMsgCycleTime" BO_ 2499746156 200;
BA_ "GenMsgCycleTime" BO_ 2499747941 100;
BA_ "GenMsgCycleTime" BO_ 2499747942 100;
BA_ "GenMsgCycleTime" BO_ 2499747943 100;
BA_ "GenMsgCycleTime" BO_ 2499747944 100;
BA_ "GenMsgCycleTime" BO_ 2499747945 100;
BA_ "GenMsgCycleTime" BO_ 2499747946 100;
BA_ "GenMsgCycleTime" BO_ 2499747947 100;
BA_ "GenMsgCycleTime" BO_ 2499747948 100;
BA_ "GenMsgCycleTime" BO_ 2499748197 1000;
BA_ "GenMsgCycleTime" BO_ 2499748198 1000;
BA_ "GenMsgCycleTime" BO_ 2499748199 1000;
BA_ "GenMsgCycleTime" BO_ 2499748200 1000;
BA_ "GenMsgCycleTime" BO_ 2499748201 1000;
BA_ "GenMsgCycleTime" BO_ 2499748202 1000;
BA_ "GenMsgCycleTime" BO_ 2499748203 1000;
BA_ "GenMsgCycleTime" BO_ 2499748204 1000;
BA_ "GenMsgCycleTime" BO_ 2499748453 1000;
BA_ "GenMsgCycleTime" BO_ 2499748454 1000;
BA_ "GenMsgCycleTime" BO_ 2499748455 1000;
BA_ "GenMsgCycleTime" BO_ 2499748456 1000;
BA_ "GenMsgCycleTime" BO_ 2499748457 1000;
BA_ "GenMsgCycleTime" BO_ 2499748458 1000;
BA_ "GenMsgCycleTime" BO_ 2499748459 1000;
BA_ "GenMsgCycleTime" BO_ 2499748460 1000;
BA_ "GenMsgCycleTime" BO_ 2499748709 1000;
BA_ "GenMsgCycleTime" BO_ 2499748710 1000;
BA_ "GenMsgCycleTime" BO_ 2499748711 1000;
BA_ "GenMsgCycleTime" BO_ 2499748712 1000;
BA_ "GenMsgCycleTime" BO_ 2499748713 1000;
BA_ "GenMsgCycleTime" BO_ 2499748714 1000;
BA_ "GenMsgCycleTime" BO_ 2499748715 1000;
BA_ "GenMsgCycleTime" BO_ 2499748716 1000;
BA_ "GenMsgCycleTime" BO_ 2499748965 100;
BA_ "GenMsgCycleTime" BO_ 2499748966 100;
BA_ "GenMsgCycleTime" BO_ 2499748967 100;
BA_ "GenMsgCycleTime" BO_ 2499748968 100;
BA_ "GenMsgCycleTime" BO_ 2499748969 100;
BA_ "GenMsgCycleTime" BO_ 2499748970 100;
BA_ "GenMsgCycleTime" BO_ 2499748971 100;
BA_ "GenMsgCycleTime" BO_ 2499748972 100;
BA_ "GenMsgCycleTime" BO_ 2499749221 100;
BA_ "GenMsgCycleTime" BO_ 2499749222 100;
BA_ "GenMsgCycleTime" BO_ 2499749223 100;
BA_ "GenMsgCycleTime" BO_ 2499749224 100;
BA_ "GenMsgCycleTime" BO_ 2499749225 100;
BA_ "GenMsgCycleTime" BO_ 2499749226 100;
BA_ "GenMsgCycleTime" BO_ 2499749227 100;
BA_ "GenMsgCycleTime" BO_ 2499749228 100;
BA_ "VFrameFormat" BO_ 2499744869 1;
BA_ "VFrameFormat" BO_ 2499744870 1;
BA_ "VFrameFormat" BO_ 2499744871 1;
BA_ "VFrameFormat" BO_ 2499744872 1;
BA_ "VFrameFormat" BO_ 2499744873 1;
BA_ "VFrameFormat" BO_ 2499744874 1;
BA_ "VFrameFormat" BO_ 2499744875 1;
BA_ "VFrameFormat" BO_ 2499744876 1;
BA_ "VFrameFormat" BO_ 2499747941 1;
BA_ "VFrameFormat" BO_ 2499747942 1;
BA_ "VFrameFormat" BO_ 2499747943 1;
BA_ "VFrameFormat" BO_ 2499747944 1;
BA_ "VFrameFormat" BO_ 2499747945 1;
BA_ "VFrameFormat" BO_ 2499747946 1;
BA_ "VFrameFormat" BO_ 2499747947 1;
BA_ "VFrameFormat" BO_ 2499747948 1;
BA_ "VFrameFormat" BO_ 2499748197 1;
BA_ "VFrameFormat" BO_ 2499748198 1;
BA_ "VFrameFormat" BO_ 2499748199 1;
BA_ "VFrameFormat" BO_ 2499748200 1;
BA_ "VFrameFormat" BO_ 2499748201 1;
BA_ "VFrameFormat" BO_ 2499748202 1;
BA_ "VFrameFormat" BO_ 2499748203 1;
BA_ "VFrameFormat" BO_ 2499748204 1;
BA_ "VFrameFormat" BO_ 2499748453 1;
BA_ "VFrameFormat" BO_ 2499748454 1;
BA_ "VFrameFormat" BO_ 2499748455 1;
BA_ "VFrameFormat" BO_ 2499748456 1;
BA_ "VFrameFormat" BO_ 2499748457 1;
BA_ "VFrameFormat" BO_ 2499748458 1;
BA_ "VFrameFormat" BO_ 2499748459 1;
BA_ "VFrameFormat" BO_ 2499748460 1;
BA_ "VFrameFormat" BO_ 2499748709 1;
BA_ "VFrameFormat" BO_ 2499748710 1;
BA_ "VFrameFormat" BO_ 2499748711 1;
BA_ "VFrameFormat" BO_ 2499748712 1;
BA_ "VFrameFormat" BO_ 2499748713 1;
BA_ "VFrameFormat" BO_ 2499748714 1;
BA_ "VFrameFormat" BO_ 2499748715 1;
BA_ "VFrameFormat" BO_ 2499748716 1;
BA_ "VFrameFormat" BO_ 2499749477 1;
BA_ "VFrameFormat" BO_ 2499749478 1;
BA_ "VFrameFormat" BO_ 2499749479 1;
BA_ "VFrameFormat" BO_ 2499749480 1;
BA_ "VFrameFormat" BO_ 2499749481 1;
BA_ "VFrameFormat" BO_ 2499749482 1;
BA_ "VFrameFormat" BO_ 2499749483 1;
BA_ "VFrameFormat" BO_ 2499749484 1;
